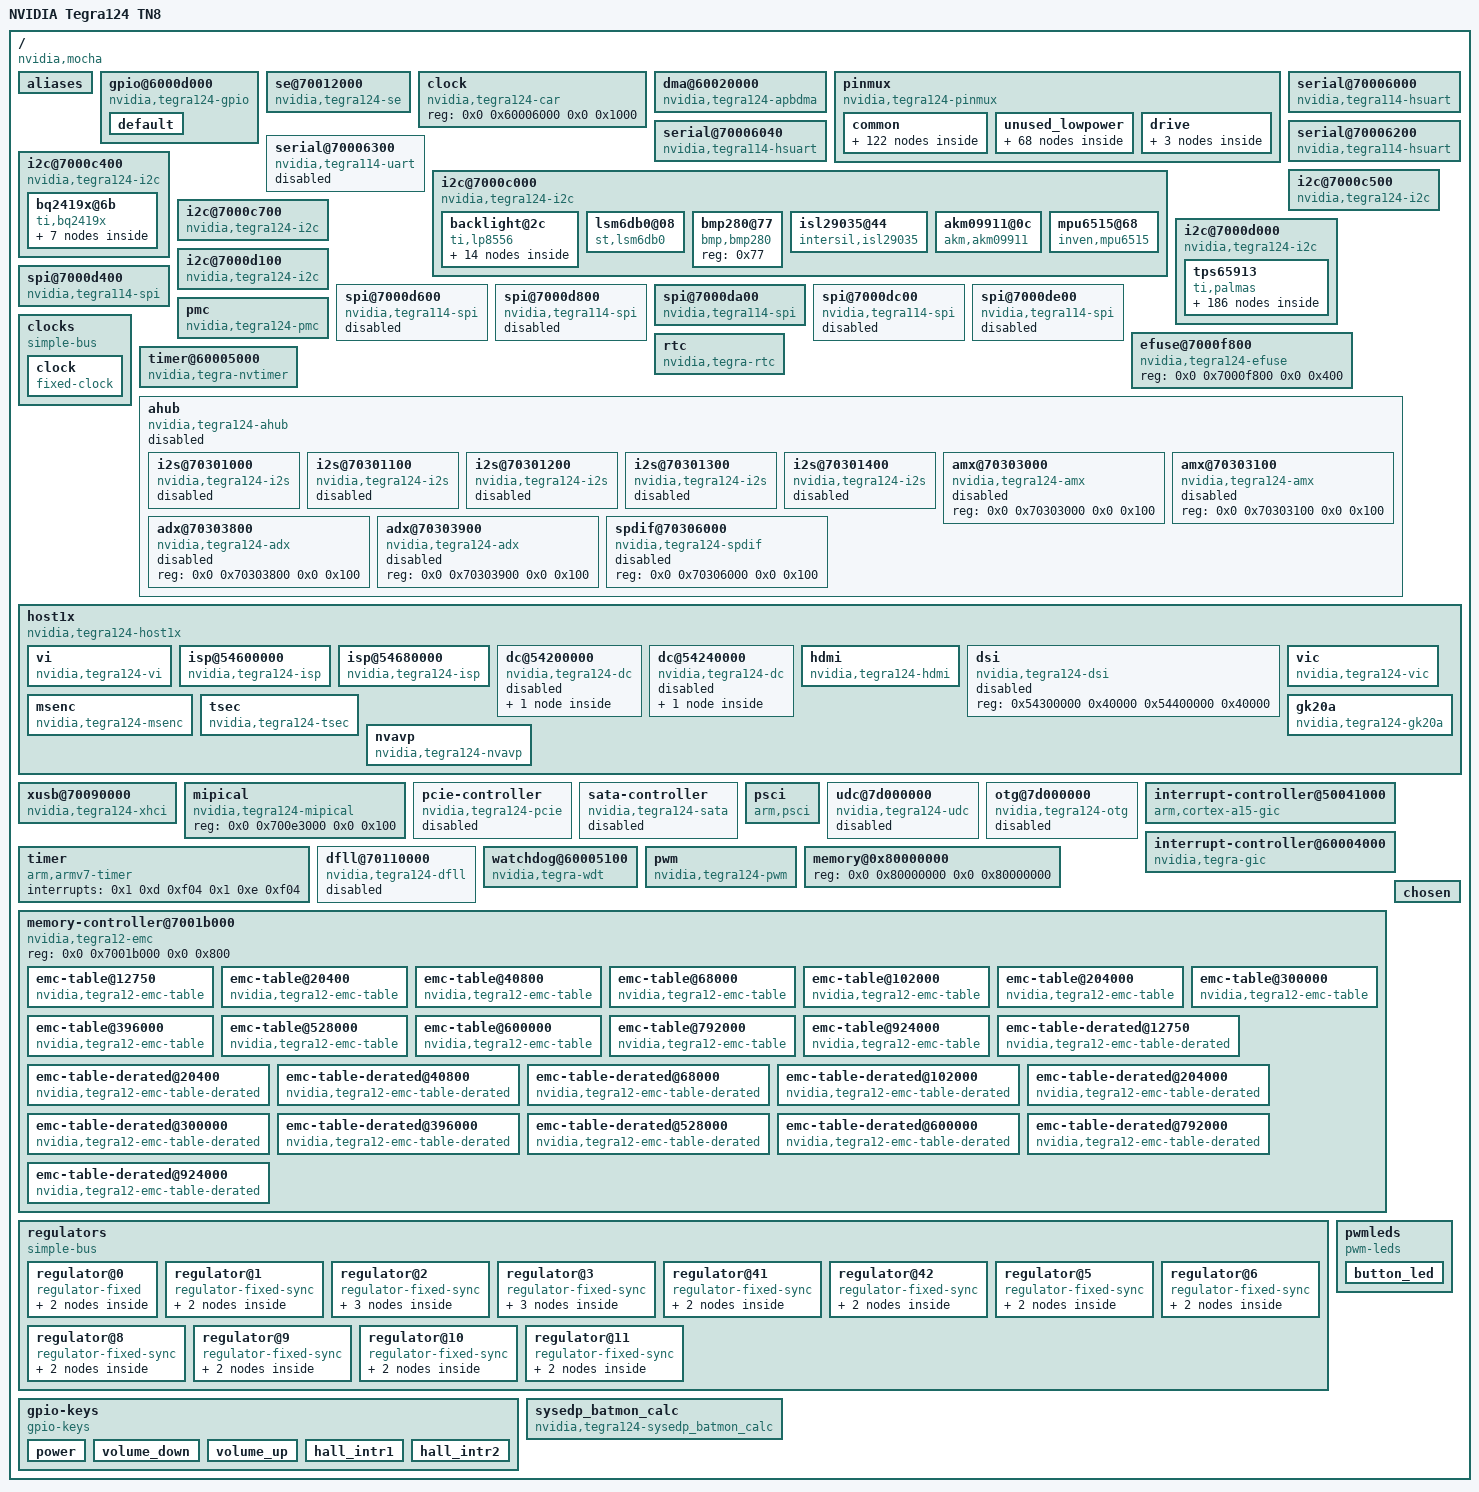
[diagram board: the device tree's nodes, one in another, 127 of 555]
/dts-v1/;

/ {
	compatible = "nvidia,mocha", "nvidia,tegra124";
	interrupt-parent = <0x1>;
	#address-cells = <0x2>;
	#size-cells = <0x2>;
	model = "NVIDIA Tegra124 TN8";
	nvidia,dtsfilename = "arch/arm/boot/dts/tegra124-mocha.dts";
	nvidia,boardids = "1780:1100:3:A:7", "1845:1000:0:A:7";

	aliases {
		i2c0 = "/i2c@7000c000";
		i2c1 = "/i2c@7000c400";
		i2c2 = "/i2c@7000c500";
		i2c3 = "/i2c@7000c700";
		i2c4 = "/i2c@7000d000";
		i2c5 = "/i2c@7000d100";
		serial0 = "/serial@70006000";
		serial1 = "/serial@70006040";
		serial2 = "/serial@70006200";
		serial3 = "/serial@70006300";
		spi0 = "/spi@7000d400";
		spi1 = "/spi@7000d600";
		spi2 = "/spi@7000d800";
		spi3 = "/spi@7000da00";
		spi4 = "/spi@7000dc00";
		spi5 = "/spi@7000de00";
		udc0 = "/udc@7d000000";
	};

	gpio@6000d000 {
		compatible = "nvidia,tegra124-gpio", "nvidia,tegra30-gpio";
		reg = <0x0 0x6000d000 0x0 0x1000>;
		interrupts = <0x0 0x20 0x4 0x0 0x21 0x4 0x0 0x22 0x4 0x0 0x23 0x4 0x0 0x37 0x4 0x0 0x57 0x4 0x0 0x59 0x4 0x0 0x7d 0x4>;
		#gpio-cells = <0x2>;
		gpio-controller;
		#interrupt-cells = <0x2>;
		interrupt-controller;
		gpio-init-names = "default";
		gpio-init-0 = <0x2>;
		linux,phandle = <0x7>;
		phandle = <0x7>;

		default {
			gpio-input = <0x2 0x3 0x32 0x33 0x45 0x46 0x47 0x48 0x50 0x52 0x80 0x85 0x86 0x87 0x8f 0x90 0x95 0xa5 0xa6 0xb2 0xb3 0xbb>;
			gpio-output-low = <0x4 0x5 0x36 0x37 0x3d 0x40 0x51 0x54 0x84 0x88 0x89 0x8b 0x8d 0x96 0xb9 0xbf 0xdb 0xde 0xdf 0xe1 0xe5 0xf1>;
			gpio-output-high = <0x3b 0x44 0x8a 0x92 0xb5 0xbd 0xdc 0xdd>;
			linux,phandle = <0x2>;
			phandle = <0x2>;
		};
	};

	se@70012000 {
		compatible = "nvidia,tegra124-se";
		reg = <0x0 0x70012000 0x0 0x2000 0x0 0x7000e400 0x0 0x400>;
		interrupts = <0x0 0x3a 0x4>;
	};

	clock {
		compatible = "nvidia,tegra124-car";
		reg = <0x0 0x60006000 0x0 0x1000>;
		#clock-cells = <0x1>;
		linux,phandle = <0xe>;
		phandle = <0xe>;
	};

	dma@60020000 {
		compatible = "nvidia,tegra124-apbdma";
		reg = <0x0 0x60020000 0x0 0x1400>;
		interrupts = <0x0 0x68 0x4 0x0 0x69 0x4 0x0 0x6a 0x4 0x0 0x6b 0x4 0x0 0x6c 0x4 0x0 0x6d 0x4 0x0 0x6e 0x4 0x0 0x6f 0x4 0x0 0x70 0x4 0x0 0x71 0x4 0x0 0x72 0x4 0x0 0x73 0x4 0x0 0x74 0x4 0x0 0x75 0x4 0x0 0x76 0x4 0x0 0x77 0x4 0x0 0x80 0x4 0x0 0x81 0x4 0x0 0x82 0x4 0x0 0x83 0x4 0x0 0x84 0x4 0x0 0x85 0x4 0x0 0x86 0x4 0x0 0x87 0x4 0x0 0x88 0x4 0x0 0x89 0x4 0x0 0x8a 0x4 0x0 0x8b 0x4 0x0 0x8c 0x4 0x0 0x8d 0x4 0x0 0x8e 0x4 0x0 0x8f 0x4>;
		linux,phandle = <0x6>;
		phandle = <0x6>;
	};

	pinmux {
		compatible = "nvidia,tegra124-pinmux";
		reg = <0x0 0x70000868 0x0 0x164 0x0 0x70003000 0x0 0x434>;
		status = "okay";
		pinctrl-names = "default", "drive", "unused";
		pinctrl-0 = <0x3>;
		pinctrl-1 = <0x4>;
		pinctrl-2 = <0x5>;

		common {
			linux,phandle = <0x3>;
			phandle = <0x3>;

			dap_mclk1_pw4 {
				nvidia,pins = "dap_mclk1_pw4";
				nvidia,function = "extperiph1";
				nvidia,enable-input = <0x0>;
				nvidia,pull = <0x0>;
				nvidia,tristate = <0x0>;
			};

			dap1_din_pn1 {
				nvidia,pins = "dap1_din_pn1";
				nvidia,function = "i2s0";
				nvidia,enable-input = <0x1>;
				nvidia,pull = <0x0>;
				nvidia,tristate = <0x1>;
			};

			dap1_dout_pn2 {
				nvidia,pins = "dap1_dout_pn2";
				nvidia,function = "i2s0";
				nvidia,enable-input = <0x0>;
				nvidia,pull = <0x0>;
				nvidia,tristate = <0x1>;
			};

			dap1_fs_pn0 {
				nvidia,pins = "dap1_fs_pn0";
				nvidia,function = "i2s0";
				nvidia,enable-input = <0x1>;
				nvidia,pull = <0x0>;
				nvidia,tristate = <0x1>;
			};

			dap1_sclk_pn3 {
				nvidia,pins = "dap1_sclk_pn3";
				nvidia,function = "i2s0";
				nvidia,enable-input = <0x1>;
				nvidia,pull = <0x0>;
				nvidia,tristate = <0x1>;
			};

			dap2_din_pa4 {
				nvidia,pins = "dap2_din_pa4";
				nvidia,function = "safe";
				nvidia,enable-input = <0x0>;
				nvidia,pull = <0x0>;
				nvidia,tristate = <0x0>;
			};

			dap2_dout_pa5 {
				nvidia,pins = "dap2_dout_pa5";
				nvidia,function = "safe";
				nvidia,enable-input = <0x0>;
				nvidia,pull = <0x0>;
				nvidia,tristate = <0x0>;
			};

			dap2_fs_pa2 {
				nvidia,pins = "dap2_fs_pa2";
				nvidia,function = "safe";
				nvidia,enable-input = <0x1>;
				nvidia,pull = <0x2>;
				nvidia,tristate = <0x0>;
			};

			dap2_sclk_pa3 {
				nvidia,pins = "dap2_sclk_pa3";
				nvidia,function = "safe";
				nvidia,enable-input = <0x1>;
				nvidia,pull = <0x2>;
				nvidia,tristate = <0x0>;
			};

			dvfs_pwm_px0 {
				nvidia,pins = "dvfs_pwm_px0";
				nvidia,function = "cldvfs";
				nvidia,enable-input = <0x0>;
				nvidia,pull = <0x0>;
				nvidia,tristate = <0x1>;
			};

			dvfs_clk_px2 {
				nvidia,pins = "dvfs_clk_px2";
				nvidia,function = "cldvfs";
				nvidia,enable-input = <0x0>;
				nvidia,pull = <0x0>;
				nvidia,tristate = <0x0>;
			};

			cam_i2c_scl_pbb1 {
				nvidia,pins = "cam_i2c_scl_pbb1";
				nvidia,function = "i2c3";
				nvidia,enable-input = <0x1>;
				nvidia,pull = <0x0>;
				nvidia,tristate = <0x0>;
				nvidia,lock = <0x0>;
				nvidia,open-drain = <0x0>;
			};

			cam_i2c_sda_pbb2 {
				nvidia,pins = "cam_i2c_sda_pbb2";
				nvidia,function = "i2c3";
				nvidia,enable-input = <0x1>;
				nvidia,pull = <0x0>;
				nvidia,tristate = <0x0>;
				nvidia,lock = <0x0>;
				nvidia,open-drain = <0x0>;
			};

			cam_mclk_pcc0 {
				nvidia,pins = "cam_mclk_pcc0";
				nvidia,function = "vi_alt3";
				nvidia,enable-input = <0x0>;
				nvidia,pull = <0x0>;
				nvidia,tristate = <0x0>;
			};

			pbb0 {
				nvidia,pins = "pbb0";
				nvidia,function = "vimclk2_alt";
				nvidia,enable-input = <0x0>;
				nvidia,pull = <0x0>;
				nvidia,tristate = <0x0>;
			};

			gen2_i2c_scl_pt5 {
				nvidia,pins = "gen2_i2c_scl_pt5";
				nvidia,function = "i2c2";
				nvidia,enable-input = <0x1>;
				nvidia,pull = <0x0>;
				nvidia,tristate = <0x0>;
				nvidia,lock = <0x0>;
				nvidia,open-drain = <0x0>;
			};

			gen2_i2c_sda_pt6 {
				nvidia,pins = "gen2_i2c_sda_pt6";
				nvidia,function = "i2c2";
				nvidia,enable-input = <0x1>;
				nvidia,pull = <0x0>;
				nvidia,tristate = <0x0>;
				nvidia,lock = <0x0>;
				nvidia,open-drain = <0x0>;
			};

			pj7 {
				nvidia,pins = "pj7";
				nvidia,function = "uartd";
				nvidia,enable-input = <0x0>;
				nvidia,pull = <0x0>;
				nvidia,tristate = <0x0>;
			};

			pb0 {
				nvidia,pins = "pb0";
				nvidia,function = "uartd";
				nvidia,enable-input = <0x1>;
				nvidia,pull = <0x2>;
				nvidia,tristate = <0x1>;
			};

			pg6 {
				nvidia,pins = "pg6";
				nvidia,function = "safe";
				nvidia,enable-input = <0x0>;
				nvidia,pull = <0x0>;
				nvidia,tristate = <0x0>;
			};

			pg7 {
				nvidia,pins = "pg7";
				nvidia,function = "safe";
				nvidia,enable-input = <0x0>;
				nvidia,pull = <0x0>;
				nvidia,tristate = <0x0>;
			};

			ph0 {
				nvidia,pins = "ph0";
				nvidia,function = "pwm0";
				nvidia,enable-input = <0x0>;
				nvidia,pull = <0x0>;
				nvidia,tristate = <0x0>;
			};

			ph1 {
				nvidia,pins = "ph1";
				nvidia,function = "pwm1";
				nvidia,enable-input = <0x0>;
				nvidia,pull = <0x0>;
				nvidia,tristate = <0x0>;
			};

			pj2 {
				nvidia,pins = "pj2";
				nvidia,function = "soc";
				nvidia,enable-input = <0x1>;
				nvidia,pull = <0x2>;
				nvidia,tristate = <0x0>;
			};

			kb_row15_ps7 {
				nvidia,pins = "kb_row15_ps7";
				nvidia,function = "soc";
				nvidia,enable-input = <0x1>;
				nvidia,pull = <0x2>;
				nvidia,tristate = <0x0>;
			};

			clk_32k_out_pa0 {
				nvidia,pins = "clk_32k_out_pa0";
				nvidia,function = "soc";
				nvidia,enable-input = <0x1>;
				nvidia,pull = <0x2>;
				nvidia,tristate = <0x0>;
			};

			clk2_out_pw5 {
				nvidia,pins = "clk2_out_pw5";
				nvidia,function = "safe";
				nvidia,enable-input = <0x0>;
				nvidia,pull = <0x2>;
				nvidia,tristate = <0x0>;
			};

			sdmmc1_clk_pz0 {
				nvidia,pins = "sdmmc1_clk_pz0";
				nvidia,function = "sdmmc1";
				nvidia,enable-input = <0x1>;
				nvidia,pull = <0x0>;
				nvidia,tristate = <0x0>;
			};

			sdmmc1_cmd_pz1 {
				nvidia,pins = "sdmmc1_cmd_pz1";
				nvidia,function = "sdmmc1";
				nvidia,enable-input = <0x1>;
				nvidia,pull = <0x2>;
				nvidia,tristate = <0x0>;
			};

			sdmmc1_dat0_py7 {
				nvidia,pins = "sdmmc1_dat0_py7";
				nvidia,function = "sdmmc1";
				nvidia,enable-input = <0x1>;
				nvidia,pull = <0x2>;
				nvidia,tristate = <0x0>;
			};

			sdmmc1_dat1_py6 {
				nvidia,pins = "sdmmc1_dat1_py6";
				nvidia,function = "sdmmc1";
				nvidia,enable-input = <0x1>;
				nvidia,pull = <0x2>;
				nvidia,tristate = <0x0>;
			};

			sdmmc1_dat2_py5 {
				nvidia,pins = "sdmmc1_dat2_py5";
				nvidia,function = "sdmmc1";
				nvidia,enable-input = <0x1>;
				nvidia,pull = <0x2>;
				nvidia,tristate = <0x0>;
			};

			sdmmc1_dat3_py4 {
				nvidia,pins = "sdmmc1_dat3_py4";
				nvidia,function = "sdmmc1";
				nvidia,enable-input = <0x1>;
				nvidia,pull = <0x2>;
				nvidia,tristate = <0x0>;
			};

			sdmmc3_clk_pa6 {
				nvidia,pins = "sdmmc3_clk_pa6";
				nvidia,function = "sdmmc3";
				nvidia,enable-input = <0x1>;
				nvidia,pull = <0x0>;
				nvidia,tristate = <0x0>;
			};

			sdmmc3_cmd_pa7 {
				nvidia,pins = "sdmmc3_cmd_pa7";
				nvidia,function = "sdmmc3";
				nvidia,enable-input = <0x1>;
				nvidia,pull = <0x2>;
				nvidia,tristate = <0x0>;
			};

			sdmmc3_dat0_pb7 {
				nvidia,pins = "sdmmc3_dat0_pb7";
				nvidia,function = "sdmmc3";
				nvidia,enable-input = <0x1>;
				nvidia,pull = <0x2>;
				nvidia,tristate = <0x0>;
			};

			sdmmc3_dat1_pb6 {
				nvidia,pins = "sdmmc3_dat1_pb6";
				nvidia,function = "sdmmc3";
				nvidia,enable-input = <0x1>;
				nvidia,pull = <0x2>;
				nvidia,tristate = <0x0>;
			};

			sdmmc3_dat2_pb5 {
				nvidia,pins = "sdmmc3_dat2_pb5";
				nvidia,function = "sdmmc3";
				nvidia,enable-input = <0x1>;
				nvidia,pull = <0x2>;
				nvidia,tristate = <0x0>;
			};

			sdmmc3_dat3_pb4 {
				nvidia,pins = "sdmmc3_dat3_pb4";
				nvidia,function = "sdmmc3";
				nvidia,enable-input = <0x1>;
				nvidia,pull = <0x2>;
				nvidia,tristate = <0x0>;
			};

			sdmmc3_clk_lb_out_pee4 {
				nvidia,pins = "sdmmc3_clk_lb_out_pee4";
				nvidia,function = "sdmmc3";
				nvidia,enable-input = <0x1>;
				nvidia,pull = <0x2>;
				nvidia,tristate = <0x0>;
			};

			sdmmc3_clk_lb_in_pee5 {
				nvidia,pins = "sdmmc3_clk_lb_in_pee5";
				nvidia,function = "sdmmc3";
				nvidia,enable-input = <0x1>;
				nvidia,pull = <0x2>;
				nvidia,tristate = <0x0>;
			};

			sdmmc3_cd_n_pv2 {
				nvidia,pins = "sdmmc3_cd_n_pv2";
				nvidia,function = "sdmmc3";
				nvidia,enable-input = <0x1>;
				nvidia,pull = <0x0>;
				nvidia,tristate = <0x0>;
			};

			sdmmc4_clk_pcc4 {
				nvidia,pins = "sdmmc4_clk_pcc4";
				nvidia,function = "sdmmc4";
				nvidia,enable-input = <0x1>;
				nvidia,pull = <0x0>;
				nvidia,tristate = <0x0>;
			};

			sdmmc4_cmd_pt7 {
				nvidia,pins = "sdmmc4_cmd_pt7";
				nvidia,function = "sdmmc4";
				nvidia,enable-input = <0x1>;
				nvidia,pull = <0x2>;
				nvidia,tristate = <0x0>;
			};

			sdmmc4_dat0_paa0 {
				nvidia,pins = "sdmmc4_dat0_paa0";
				nvidia,function = "sdmmc4";
				nvidia,enable-input = <0x1>;
				nvidia,pull = <0x2>;
				nvidia,tristate = <0x0>;
			};

			sdmmc4_dat1_paa1 {
				nvidia,pins = "sdmmc4_dat1_paa1";
				nvidia,function = "sdmmc4";
				nvidia,enable-input = <0x1>;
				nvidia,pull = <0x2>;
				nvidia,tristate = <0x0>;
			};

			sdmmc4_dat2_paa2 {
				nvidia,pins = "sdmmc4_dat2_paa2";
				nvidia,function = "sdmmc4";
				nvidia,enable-input = <0x1>;
				nvidia,pull = <0x2>;
				nvidia,tristate = <0x0>;
			};

			sdmmc4_dat3_paa3 {
				nvidia,pins = "sdmmc4_dat3_paa3";
				nvidia,function = "sdmmc4";
				nvidia,enable-input = <0x1>;
				nvidia,pull = <0x2>;
				nvidia,tristate = <0x0>;
			};

			sdmmc4_dat4_paa4 {
				nvidia,pins = "sdmmc4_dat4_paa4";
				nvidia,function = "sdmmc4";
				nvidia,enable-input = <0x1>;
				nvidia,pull = <0x2>;
				nvidia,tristate = <0x0>;
			};

			sdmmc4_dat5_paa5 {
				nvidia,pins = "sdmmc4_dat5_paa5";
				nvidia,function = "sdmmc4";
				nvidia,enable-input = <0x1>;
				nvidia,pull = <0x2>;
				nvidia,tristate = <0x0>;
			};

			sdmmc4_dat6_paa6 {
				nvidia,pins = "sdmmc4_dat6_paa6";
				nvidia,function = "sdmmc4";
				nvidia,enable-input = <0x1>;
				nvidia,pull = <0x2>;
				nvidia,tristate = <0x0>;
			};

			sdmmc4_dat7_paa7 {
				nvidia,pins = "sdmmc4_dat7_paa7";
				nvidia,function = "sdmmc4";
				nvidia,enable-input = <0x1>;
				nvidia,pull = <0x2>;
				nvidia,tristate = <0x0>;
			};

			kb_row3_pr3 {
				nvidia,pins = "kb_row3_pr3";
				nvidia,function = "safe";
				nvidia,enable-input = <0x1>;
				nvidia,pull = <0x0>;
				nvidia,tristate = <0x0>;
			};

			kb_row6_pr6 {
				nvidia,pins = "kb_row6_pr6";
				nvidia,function = "displaya_alt";
				nvidia,enable-input = <0x1>;
				nvidia,pull = <0x0>;
				nvidia,tristate = <0x0>;
			};

			pwr_i2c_scl_pz6 {
				nvidia,pins = "pwr_i2c_scl_pz6";
				nvidia,function = "i2cpwr";
				nvidia,enable-input = <0x1>;
				nvidia,pull = <0x0>;
				nvidia,tristate = <0x0>;
				nvidia,open-drain = <0x0>;
			};

			pwr_i2c_sda_pz7 {
				nvidia,pins = "pwr_i2c_sda_pz7";
				nvidia,function = "i2cpwr";
				nvidia,enable-input = <0x1>;
				nvidia,pull = <0x0>;
				nvidia,tristate = <0x0>;
				nvidia,open-drain = <0x0>;
			};

			clk_32k_in {
				nvidia,pins = "clk_32k_in";
				nvidia,function = "clk";
				nvidia,enable-input = <0x1>;
				nvidia,pull = <0x0>;
				nvidia,tristate = <0x0>;
			};

			core_pwr_req {
				nvidia,pins = "core_pwr_req";
				nvidia,function = "pwron";
				nvidia,enable-input = <0x0>;
				nvidia,pull = <0x0>;
				nvidia,tristate = <0x0>;
			};

			cpu_pwr_req {
				nvidia,pins = "cpu_pwr_req";
				nvidia,function = "cpu";
				nvidia,enable-input = <0x0>;
				nvidia,pull = <0x0>;
				nvidia,tristate = <0x0>;
			};

			pwr_int_n {
				nvidia,pins = "pwr_int_n";
				nvidia,function = "pmi";
				nvidia,enable-input = <0x1>;
				nvidia,pull = <0x2>;
				nvidia,tristate = <0x0>;
			};

			reset_out_n {
				nvidia,pins = "reset_out_n";
				nvidia,function = "reset_out_n";
				nvidia,enable-input = <0x0>;
				nvidia,pull = <0x0>;
				nvidia,tristate = <0x0>;
			};

			gen1_i2c_sda_pc5 {
				nvidia,pins = "gen1_i2c_sda_pc5";
				nvidia,function = "i2c1";
				nvidia,enable-input = <0x1>;
				nvidia,pull = <0x0>;
				nvidia,tristate = <0x0>;
				nvidia,lock = <0x0>;
				nvidia,open-drain = <0x0>;
			};

			gen1_i2c_scl_pc4 {
				nvidia,pins = "gen1_i2c_scl_pc4";
				nvidia,function = "i2c1";
				nvidia,enable-input = <0x1>;
				nvidia,pull = <0x0>;
				nvidia,tristate = <0x0>;
				nvidia,lock = <0x0>;
				nvidia,open-drain = <0x0>;
			};

			uart2_cts_n_pj5 {
				nvidia,pins = "uart2_cts_n_pj5";
				nvidia,function = "uartb";
				nvidia,enable-input = <0x1>;
				nvidia,pull = <0x2>;
				nvidia,tristate = <0x0>;
			};

			uart2_rts_n_pj6 {
				nvidia,pins = "uart2_rts_n_pj6";
				nvidia,function = "uartb";
				nvidia,enable-input = <0x0>;
				nvidia,pull = <0x2>;
				nvidia,tristate = <0x0>;
			};

			uart2_rxd_pc3 {
				nvidia,pins = "uart2_rxd_pc3";
				nvidia,function = "irda";
				nvidia,enable-input = <0x1>;
				nvidia,pull = <0x2>;
				nvidia,tristate = <0x0>;
			};

			uart2_txd_pc2 {
				nvidia,pins = "uart2_txd_pc2";
				nvidia,function = "irda";
				nvidia,enable-input = <0x0>;
				nvidia,pull = <0x2>;
				nvidia,tristate = <0x0>;
			};

			uart3_cts_n_pa1 {
				nvidia,pins = "uart3_cts_n_pa1";
				nvidia,function = "uartc";
				nvidia,enable-input = <0x1>;
				nvidia,pull = <0x2>;
				nvidia,tristate = <0x0>;
			};

			uart3_rts_n_pc0 {
				nvidia,pins = "uart3_rts_n_pc0";
				nvidia,function = "uartc";
				nvidia,enable-input = <0x0>;
				nvidia,pull = <0x2>;
				nvidia,tristate = <0x0>;
			};

			uart3_rxd_pw7 {
				nvidia,pins = "uart3_rxd_pw7";
				nvidia,function = "uartc";
				nvidia,enable-input = <0x1>;
				nvidia,pull = <0x2>;
				nvidia,tristate = <0x0>;
			};

			uart3_txd_pw6 {
				nvidia,pins = "uart3_txd_pw6";
				nvidia,function = "uartc";
				nvidia,enable-input = <0x0>;
				nvidia,pull = <0x2>;
				nvidia,tristate = <0x0>;
			};

			ddc_scl_pv4 {
				nvidia,pins = "ddc_scl_pv4";
				nvidia,function = "i2c4";
				nvidia,enable-input = <0x1>;
				nvidia,pull = <0x0>;
				nvidia,tristate = <0x0>;
			};

			ddc_sda_pv5 {
				nvidia,pins = "ddc_sda_pv5";
				nvidia,function = "i2c4";
				nvidia,enable-input = <0x1>;
				nvidia,pull = <0x0>;
				nvidia,tristate = <0x0>;
			};

			pi7 {
				nvidia,pins = "pi7";
				nvidia,function = "safe";
				nvidia,enable-input = <0x1>;
				nvidia,pull = <0x2>;
				nvidia,tristate = <0x0>;
			};

			gpio_x5_aud_px5 {
				nvidia,pins = "gpio_x5_aud_px5";
				nvidia,function = "safe";
				nvidia,enable-input = <0x0>;
				nvidia,pull = <0x0>;
				nvidia,tristate = <0x0>;
			};

			gpio_x7_aud_px7 {
				nvidia,pins = "gpio_x7_aud_px7";
				nvidia,function = "safe";
				nvidia,enable-input = <0x0>;
				nvidia,pull = <0x0>;
				nvidia,tristate = <0x0>;
			};

			gpio_w2_aud_pw2 {
				nvidia,pins = "gpio_w2_aud_pw2";
				nvidia,function = "safe";
				nvidia,enable-input = <0x1>;
				nvidia,pull = <0x2>;
				nvidia,tristate = <0x0>;
			};

			gpio_w3_aud_pw3 {
				nvidia,pins = "gpio_w3_aud_pw3";
				nvidia,function = "safe";
				nvidia,enable-input = <0x1>;
				nvidia,pull = <0x2>;
				nvidia,tristate = <0x0>;
			};

			gpio_x1_aud_px1 {
				nvidia,pins = "gpio_x1_aud_px1";
				nvidia,function = "safe";
				nvidia,enable-input = <0x0>;
				nvidia,pull = <0x0>;
				nvidia,tristate = <0x0>;
			};

			gpio_x3_aud_px3 {
				nvidia,pins = "gpio_x3_aud_px3";
				nvidia,function = "safe";
				nvidia,enable-input = <0x1>;
				nvidia,pull = <0x2>;
				nvidia,tristate = <0x0>;
			};

			ulpi_data1_po2 {
				nvidia,pins = "ulpi_data1_po2";
				nvidia,function = "spi3";
				nvidia,enable-input = <0x1>;
				nvidia,pull = <0x2>;
				nvidia,tristate = <0x0>;
			};

			ulpi_data2_po3 {
				nvidia,pins = "ulpi_data2_po3";
				nvidia,function = "spi3";
				nvidia,enable-input = <0x1>;
				nvidia,pull = <0x2>;
				nvidia,tristate = <0x0>;
			};

			pbb3 {
				nvidia,pins = "pbb3";
				nvidia,function = "safe";
				nvidia,enable-input = <0x0>;
				nvidia,pull = <0x0>;
				nvidia,tristate = <0x0>;
			};

			pbb4 {
				nvidia,pins = "pbb4";
				nvidia,function = "safe";
				nvidia,enable-input = <0x0>;
				nvidia,pull = <0x2>;
				nvidia,tristate = <0x0>;
			};

			pbb5 {
				nvidia,pins = "pbb5";
				nvidia,function = "safe";
				nvidia,enable-input = <0x0>;
				nvidia,pull = <0x2>;
				nvidia,tristate = <0x0>;
			};

			pbb6 {
				nvidia,pins = "pbb6";
				nvidia,function = "safe";
				nvidia,enable-input = <0x0>;
				nvidia,pull = <0x0>;
				nvidia,tristate = <0x0>;
			};

			pbb7 {
				nvidia,pins = "pbb7";
				nvidia,function = "safe";
				nvidia,enable-input = <0x0>;
				nvidia,pull = <0x0>;
				nvidia,tristate = <0x0>;
			};

			pcc1 {
				nvidia,pins = "pcc1";
				nvidia,function = "safe";
				nvidia,enable-input = <0x0>;
				nvidia,pull = <0x0>;
				nvidia,tristate = <0x0>;
			};

			ph2 {
				nvidia,pins = "ph2";
				nvidia,function = "pwm2";
				nvidia,enable-input = <0x0>;
				nvidia,pull = <0x0>;
				nvidia,tristate = <0x0>;
			};

			ph3 {
				nvidia,pins = "ph3";
				nvidia,function = "safe";
				nvidia,enable-input = <0x0>;
				nvidia,pull = <0x2>;
				nvidia,tristate = <0x0>;
			};

			ph5 {
				nvidia,pins = "ph5";
				nvidia,function = "safe";
				nvidia,enable-input = <0x0>;
				nvidia,pull = <0x0>;
				nvidia,tristate = <0x0>;
			};

			pg2 {
				nvidia,pins = "pg2";
				nvidia,function = "safe";
				nvidia,enable-input = <0x1>;
				nvidia,pull = <0x1>;
				nvidia,tristate = <0x0>;
			};

			pg3 {
				nvidia,pins = "pg3";
				nvidia,function = "safe";
				nvidia,enable-input = <0x1>;
				nvidia,pull = <0x1>;
				nvidia,tristate = <0x0>;
			};

			pk1 {
				nvidia,pins = "pk1";
				nvidia,function = "safe";
				nvidia,enable-input = <0x0>;
				nvidia,pull = <0x0>;
				nvidia,tristate = <0x0>;
			};

			pj0 {
				nvidia,pins = "pj0";
				nvidia,function = "safe";
				nvidia,enable-input = <0x1>;
				nvidia,pull = <0x2>;
				nvidia,tristate = <0x0>;
			};

			pk4 {
				nvidia,pins = "pk4";
				nvidia,function = "safe";
				nvidia,enable-input = <0x0>;
				nvidia,pull = <0x0>;
				nvidia,tristate = <0x0>;
			};

			pk2 {
				nvidia,pins = "pk2";
				nvidia,function = "safe";
				nvidia,enable-input = <0x1>;
				nvidia,pull = <0x2>;
				nvidia,tristate = <0x0>;
			};

			pi6 {
				nvidia,pins = "pi6";
				nvidia,function = "safe";
				nvidia,enable-input = <0x1>;
				nvidia,pull = <0x2>;
				nvidia,tristate = <0x0>;
			};

			pi5 {
				nvidia,pins = "pi5";
				nvidia,function = "safe";
				nvidia,enable-input = <0x1>;
				nvidia,pull = <0x0>;
				nvidia,tristate = <0x0>;
			};

			pc7 {
				nvidia,pins = "pc7";
				nvidia,function = "safe";
				nvidia,enable-input = <0x1>;
				nvidia,pull = <0x2>;
				nvidia,tristate = <0x0>;
			};

			pi0 {
				nvidia,pins = "pi0";
				nvidia,function = "safe";
				nvidia,enable-input = <0x0>;
				nvidia,pull = <0x0>;
				nvidia,tristate = <0x0>;
			};

			clk2_req_pcc5 {
				nvidia,pins = "clk2_req_pcc5";
				nvidia,function = "safe";
				nvidia,enable-input = <0x0>;
				nvidia,pull = <0x0>;
				nvidia,tristate = <0x0>;
			};

			kb_col0_pq0 {
				nvidia,pins = "kb_col0_pq0";
				nvidia,function = "safe";
				nvidia,enable-input = <0x1>;
				nvidia,pull = <0x2>;
				nvidia,tristate = <0x0>;
			};

			kb_col5_pq5 {
				nvidia,pins = "kb_col5_pq5";
				nvidia,function = "safe";
				nvidia,enable-input = <0x1>;
				nvidia,pull = <0x2>;
				nvidia,tristate = <0x0>;
			};

			kb_col6_pq6 {
				nvidia,pins = "kb_col6_pq6";
				nvidia,function = "safe";
				nvidia,enable-input = <0x1>;
				nvidia,pull = <0x2>;
				nvidia,tristate = <0x0>;
			};

			kb_col7_pq7 {
				nvidia,pins = "kb_col7_pq7";
				nvidia,function = "safe";
				nvidia,enable-input = <0x1>;
				nvidia,pull = <0x2>;
				nvidia,tristate = <0x0>;
			};

			kb_row0_pr0 {
				nvidia,pins = "kb_row0_pr0";
				nvidia,function = "safe";
				nvidia,enable-input = <0x0>;
				nvidia,pull = <0x0>;
				nvidia,tristate = <0x0>;
			};

			kb_row1_pr1 {
				nvidia,pins = "kb_row1_pr1";
				nvidia,function = "safe";
				nvidia,enable-input = <0x0>;
				nvidia,pull = <0x0>;
				nvidia,tristate = <0x0>;
			};

			kb_row13_ps5 {
				nvidia,pins = "kb_row13_ps5";
				nvidia,function = "safe";
				nvidia,enable-input = <0x1>;
				nvidia,pull = <0x2>;
				nvidia,tristate = <0x0>;
			};

			kb_row14_ps6 {
				nvidia,pins = "kb_row14_ps6";
				nvidia,function = "safe";
				nvidia,enable-input = <0x0>;
				nvidia,pull = <0x0>;
				nvidia,tristate = <0x0>;
			};

			kb_row2_pr2 {
				nvidia,pins = "kb_row2_pr2";
				nvidia,function = "safe";
				nvidia,enable-input = <0x0>;
				nvidia,pull = <0x0>;
				nvidia,tristate = <0x0>;
			};

			kb_row5_pr5 {
				nvidia,pins = "kb_row5_pr5";
				nvidia,function = "safe";
				nvidia,enable-input = <0x0>;
				nvidia,pull = <0x0>;
				nvidia,tristate = <0x0>;
			};

			kb_row7_pr7 {
				nvidia,pins = "kb_row7_pr7";
				nvidia,function = "safe";
				nvidia,enable-input = <0x1>;
				nvidia,pull = <0x2>;
				nvidia,tristate = <0x0>;
			};

			kb_row8_ps0 {
				nvidia,pins = "kb_row8_ps0";
				nvidia,function = "safe";
				nvidia,enable-input = <0x1>;
				nvidia,pull = <0x2>;
				nvidia,tristate = <0x0>;
			};

			kb_row10_ps2 {
				nvidia,pins = "kb_row10_ps2";
				nvidia,function = "safe";
				nvidia,enable-input = <0x0>;
				nvidia,pull = <0x2>;
				nvidia,tristate = <0x0>;
			};

			clk3_req_pee1 {
				nvidia,pins = "clk3_req_pee1";
				nvidia,function = "safe";
				nvidia,enable-input = <0x0>;
				nvidia,pull = <0x0>;
				nvidia,tristate = <0x0>;
			};

			pu4 {
				nvidia,pins = "pu4";
				nvidia,function = "safe";
				nvidia,enable-input = <0x0>;
				nvidia,pull = <0x0>;
				nvidia,tristate = <0x0>;
			};

			pu5 {
				nvidia,pins = "pu5";
				nvidia,function = "safe";
				nvidia,enable-input = <0x1>;
				nvidia,pull = <0x2>;
				nvidia,tristate = <0x0>;
			};

			pu6 {
				nvidia,pins = "pu6";
				nvidia,function = "safe";
				nvidia,enable-input = <0x1>;
				nvidia,pull = <0x2>;
				nvidia,tristate = <0x0>;
			};

			ulpi_data0_po1 {
				nvidia,pins = "ulpi_data0_po1";
				nvidia,function = "spi3";
				nvidia,enable-input = <0x0>;
				nvidia,pull = <0x1>;
				nvidia,tristate = <0x1>;
			};

			ulpi_data3_po4 {
				nvidia,pins = "ulpi_data3_po4";
				nvidia,function = "spi3";
				nvidia,enable-input = <0x0>;
				nvidia,pull = <0x1>;
				nvidia,tristate = <0x1>;
			};

			pi1 {
				nvidia,pins = "pi1";
				nvidia,function = "safe";
				nvidia,enable-input = <0x0>;
				nvidia,pull = <0x1>;
				nvidia,tristate = <0x1>;
			};
		};

		unused_lowpower {
			linux,phandle = <0x5>;
			phandle = <0x5>;

			dap_mclk1_req_pee2 {
				nvidia,pins = "dap_mclk1_req_pee2";
				nvidia,function = "safe";
				nvidia,enable-input = <0x0>;
				nvidia,pull = <0x1>;
				nvidia,tristate = <0x1>;
			};

			dap3_din_pp1 {
				nvidia,pins = "dap3_din_pp1";
				nvidia,function = "safe";
				nvidia,enable-input = <0x0>;
				nvidia,pull = <0x1>;
				nvidia,tristate = <0x1>;
			};

			dap3_dout_pp2 {
				nvidia,pins = "dap3_dout_pp2";
				nvidia,function = "safe";
				nvidia,enable-input = <0x0>;
				nvidia,pull = <0x1>;
				nvidia,tristate = <0x1>;
			};

			dap3_fs_pp0 {
				nvidia,pins = "dap3_fs_pp0";
				nvidia,function = "safe";
				nvidia,enable-input = <0x0>;
				nvidia,pull = <0x1>;
				nvidia,tristate = <0x1>;
			};

			dap3_sclk_pp3 {
				nvidia,pins = "dap3_sclk_pp3";
				nvidia,function = "safe";
				nvidia,enable-input = <0x0>;
				nvidia,pull = <0x1>;
				nvidia,tristate = <0x1>;
			};

			pex_l0_clkreq_n_pdd2 {
				nvidia,pins = "pex_l0_clkreq_n_pdd2";
				nvidia,function = "safe";
				nvidia,enable-input = <0x0>;
				nvidia,pull = <0x1>;
				nvidia,tristate = <0x1>;
			};

			pex_l0_rst_n_pdd1 {
				nvidia,pins = "pex_l0_rst_n_pdd1";
				nvidia,function = "safe";
				nvidia,enable-input = <0x0>;
				nvidia,pull = <0x1>;
				nvidia,tristate = <0x1>;
			};

			pex_l1_clkreq_n_pdd6 {
				nvidia,pins = "pex_l1_clkreq_n_pdd6";
				nvidia,function = "safe";
				nvidia,enable-input = <0x0>;
				nvidia,pull = <0x1>;
				nvidia,tristate = <0x1>;
			};

			pex_l1_rst_n_pdd5 {
				nvidia,pins = "pex_l1_rst_n_pdd5";
				nvidia,function = "safe";
				nvidia,enable-input = <0x0>;
				nvidia,pull = <0x1>;
				nvidia,tristate = <0x1>;
			};

			pex_wake_n_pdd3 {
				nvidia,pins = "pex_wake_n_pdd3";
				nvidia,function = "safe";
				nvidia,enable-input = <0x0>;
				nvidia,pull = <0x1>;
				nvidia,tristate = <0x1>;
			};

			pff2 {
				nvidia,pins = "pff2";
				nvidia,function = "safe";
				nvidia,enable-input = <0x0>;
				nvidia,pull = <0x1>;
				nvidia,tristate = <0x1>;
			};

			kb_col3_pq3 {
				nvidia,pins = "kb_col3_pq3";
				nvidia,function = "safe";
				nvidia,enable-input = <0x0>;
				nvidia,pull = <0x1>;
				nvidia,tristate = <0x1>;
			};

			kb_row16_pt0 {
				nvidia,pins = "kb_row16_pt0";
				nvidia,function = "safe";
				nvidia,enable-input = <0x0>;
				nvidia,pull = <0x1>;
				nvidia,tristate = <0x1>;
			};

			kb_row17_pt1 {
				nvidia,pins = "kb_row17_pt1";
				nvidia,function = "safe";
				nvidia,enable-input = <0x0>;
				nvidia,pull = <0x1>;
				nvidia,tristate = <0x1>;
			};

			owr {
				nvidia,pins = "owr";
				nvidia,function = "safe";
				nvidia,enable-input = <0x0>;
				nvidia,pull = <0x1>;
				nvidia,tristate = <0x1>;
			};

			ulpi_clk_py0 {
				nvidia,pins = "ulpi_clk_py0";
				nvidia,function = "safe";
				nvidia,enable-input = <0x0>;
				nvidia,pull = <0x1>;
				nvidia,tristate = <0x1>;
			};

			ulpi_dir_py1 {
				nvidia,pins = "ulpi_dir_py1";
				nvidia,function = "safe";
				nvidia,enable-input = <0x0>;
				nvidia,pull = <0x1>;
				nvidia,tristate = <0x1>;
			};

			ulpi_nxt_py2 {
				nvidia,pins = "ulpi_nxt_py2";
				nvidia,function = "safe";
				nvidia,enable-input = <0x0>;
				nvidia,pull = <0x1>;
				nvidia,tristate = <0x1>;
			};

			ulpi_stp_py3 {
				nvidia,pins = "ulpi_stp_py3";
				nvidia,function = "safe";
				nvidia,enable-input = <0x0>;
				nvidia,pull = <0x1>;
				nvidia,tristate = <0x1>;
			};

			hdmi_cec_pee3 {
				nvidia,pins = "hdmi_cec_pee3";
				nvidia,function = "safe";
				nvidia,enable-input = <0x0>;
				nvidia,pull = <0x1>;
				nvidia,tristate = <0x1>;
			};

			clk3_out_pee0 {
				nvidia,pins = "clk3_out_pee0";
				nvidia,function = "safe";
				nvidia,enable-input = <0x0>;
				nvidia,pull = <0x1>;
				nvidia,tristate = <0x1>;
			};

			dp_hpd_pff0 {
				nvidia,pins = "dp_hpd_pff0";
				nvidia,function = "safe";
				nvidia,enable-input = <0x0>;
				nvidia,pull = <0x1>;
				nvidia,tristate = <0x1>;
			};

			dap4_din_pp5 {
				nvidia,pins = "dap4_din_pp5";
				nvidia,function = "safe";
				nvidia,enable-input = <0x0>;
				nvidia,pull = <0x1>;
				nvidia,tristate = <0x1>;
			};

			dap4_dout_pp6 {
				nvidia,pins = "dap4_dout_pp6";
				nvidia,function = "safe";
				nvidia,enable-input = <0x0>;
				nvidia,pull = <0x1>;
				nvidia,tristate = <0x1>;
			};

			dap4_fs_pp4 {
				nvidia,pins = "dap4_fs_pp4";
				nvidia,function = "safe";
				nvidia,enable-input = <0x0>;
				nvidia,pull = <0x1>;
				nvidia,tristate = <0x1>;
			};

			dap4_sclk_pp7 {
				nvidia,pins = "dap4_sclk_pp7";
				nvidia,function = "safe";
				nvidia,enable-input = <0x0>;
				nvidia,pull = <0x1>;
				nvidia,tristate = <0x1>;
			};

			kb_row9_ps1 {
				nvidia,pins = "kb_row9_ps1";
				nvidia,function = "safe";
				nvidia,enable-input = <0x0>;
				nvidia,pull = <0x1>;
				nvidia,tristate = <0x1>;
			};

			pk0 {
				nvidia,pins = "pk0";
				nvidia,function = "safe";
				nvidia,enable-input = <0x0>;
				nvidia,pull = <0x1>;
				nvidia,tristate = <0x1>;
			};

			pi3 {
				nvidia,pins = "pi3";
				nvidia,function = "safe";
				nvidia,enable-input = <0x0>;
				nvidia,pull = <0x1>;
				nvidia,tristate = <0x1>;
			};

			pb1 {
				nvidia,pins = "pb1";
				nvidia,function = "safe";
				nvidia,enable-input = <0x0>;
				nvidia,pull = <0x1>;
				nvidia,tristate = <0x1>;
			};

			ulpi_data4_po5 {
				nvidia,pins = "ulpi_data4_po5";
				nvidia,function = "safe";
				nvidia,enable-input = <0x0>;
				nvidia,pull = <0x1>;
				nvidia,tristate = <0x1>;
			};

			ulpi_data5_po6 {
				nvidia,pins = "ulpi_data5_po6";
				nvidia,function = "safe";
				nvidia,enable-input = <0x0>;
				nvidia,pull = <0x1>;
				nvidia,tristate = <0x1>;
			};

			ulpi_data6_po7 {
				nvidia,pins = "ulpi_data6_po7";
				nvidia,function = "safe";
				nvidia,enable-input = <0x0>;
				nvidia,pull = <0x1>;
				nvidia,tristate = <0x1>;
			};

			ulpi_data7_po0 {
				nvidia,pins = "ulpi_data7_po0";
				nvidia,function = "safe";
				nvidia,enable-input = <0x0>;
				nvidia,pull = <0x1>;
				nvidia,tristate = <0x1>;
			};

			pv0 {
				nvidia,pins = "pv0";
				nvidia,function = "safe";
				nvidia,enable-input = <0x0>;
				nvidia,pull = <0x1>;
				nvidia,tristate = <0x1>;
			};

			pv1 {
				nvidia,pins = "pv1";
				nvidia,function = "safe";
				nvidia,enable-input = <0x0>;
				nvidia,pull = <0x1>;
				nvidia,tristate = <0x1>;
			};

			gpio_x6_aud_px6 {
				nvidia,pins = "gpio_x6_aud_px6";
				nvidia,function = "safe";
				nvidia,enable-input = <0x0>;
				nvidia,pull = <0x1>;
				nvidia,tristate = <0x1>;
			};

			gpio_x4_aud_px4 {
				nvidia,pins = "gpio_x4_aud_px4";
				nvidia,function = "safe";
				nvidia,enable-input = <0x0>;
				nvidia,pull = <0x1>;
				nvidia,tristate = <0x1>;
			};

			ph6 {
				nvidia,pins = "ph6";
				nvidia,function = "safe";
				nvidia,enable-input = <0x0>;
				nvidia,pull = <0x1>;
				nvidia,tristate = <0x1>;
			};

			ph7 {
				nvidia,pins = "ph7";
				nvidia,function = "safe";
				nvidia,enable-input = <0x0>;
				nvidia,pull = <0x1>;
				nvidia,tristate = <0x1>;
			};

			hdmi_int_pn7 {
				nvidia,pins = "hdmi_int_pn7";
				nvidia,function = "safe";
				nvidia,enable-input = <0x0>;
				nvidia,pull = <0x1>;
				nvidia,tristate = <0x1>;
			};

			spdif_out_pk5 {
				nvidia,pins = "spdif_out_pk5";
				nvidia,function = "safe";
				nvidia,enable-input = <0x0>;
				nvidia,pull = <0x1>;
				nvidia,tristate = <0x1>;
			};

			spdif_in_pk6 {
				nvidia,pins = "spdif_in_pk6";
				nvidia,function = "safe";
				nvidia,enable-input = <0x0>;
				nvidia,pull = <0x1>;
				nvidia,tristate = <0x1>;
			};

			pu2 {
				nvidia,pins = "pu2";
				nvidia,function = "safe";
				nvidia,enable-input = <0x0>;
				nvidia,pull = <0x1>;
				nvidia,tristate = <0x1>;
			};

			pu3 {
				nvidia,pins = "pu3";
				nvidia,function = "safe";
				nvidia,enable-input = <0x0>;
				nvidia,pull = <0x1>;
				nvidia,tristate = <0x1>;
			};

			kb_row4_pr4 {
				nvidia,pins = "kb_row4_pr4";
				nvidia,function = "safe";
				nvidia,enable-input = <0x0>;
				nvidia,pull = <0x1>;
				nvidia,tristate = <0x1>;
			};

			kb_row11_ps3 {
				nvidia,pins = "kb_row11_ps3";
				nvidia,function = "safe";
				nvidia,enable-input = <0x0>;
				nvidia,pull = <0x1>;
				nvidia,tristate = <0x1>;
			};

			kb_row12_ps4 {
				nvidia,pins = "kb_row12_ps4";
				nvidia,function = "safe";
				nvidia,enable-input = <0x0>;
				nvidia,pull = <0x1>;
				nvidia,tristate = <0x1>;
			};

			kb_col1_pq1 {
				nvidia,pins = "kb_col1_pq1";
				nvidia,function = "safe";
				nvidia,enable-input = <0x0>;
				nvidia,pull = <0x1>;
				nvidia,tristate = <0x1>;
			};

			kb_col2_pq2 {
				nvidia,pins = "kb_col2_pq2";
				nvidia,function = "safe";
				nvidia,enable-input = <0x0>;
				nvidia,pull = <0x1>;
				nvidia,tristate = <0x1>;
			};

			kb_col4_pq4 {
				nvidia,pins = "kb_col4_pq4";
				nvidia,function = "safe";
				nvidia,enable-input = <0x0>;
				nvidia,pull = <0x0>;
				nvidia,tristate = <0x0>;
			};

			sdmmc1_wp_n_pv3 {
				nvidia,pins = "sdmmc1_wp_n_pv3";
				nvidia,function = "safe";
				nvidia,enable-input = <0x0>;
				nvidia,pull = <0x1>;
				nvidia,tristate = <0x1>;
			};

			pc7 {
				nvidia,pins = "pc7";
				nvidia,function = "safe";
				nvidia,enable-input = <0x0>;
				nvidia,pull = <0x1>;
				nvidia,tristate = <0x1>;
			};

			pi2 {
				nvidia,pins = "pi2";
				nvidia,function = "safe";
				nvidia,enable-input = <0x0>;
				nvidia,pull = <0x1>;
				nvidia,tristate = <0x1>;
			};

			pk3 {
				nvidia,pins = "pk3";
				nvidia,function = "safe";
				nvidia,enable-input = <0x0>;
				nvidia,pull = <0x1>;
				nvidia,tristate = <0x1>;
			};

			ph4 {
				nvidia,pins = "ph4";
				nvidia,function = "safe";
				nvidia,enable-input = <0x0>;
				nvidia,pull = <0x1>;
				nvidia,tristate = <0x1>;
			};

			pcc2 {
				nvidia,pins = "pcc2";
				nvidia,function = "safe";
				nvidia,enable-input = <0x0>;
				nvidia,pull = <0x1>;
				nvidia,tristate = <0x1>;
			};

			pg0 {
				nvidia,pins = "pg0";
				nvidia,function = "safe";
				nvidia,enable-input = <0x0>;
				nvidia,pull = <0x1>;
				nvidia,tristate = <0x1>;
			};

			pg1 {
				nvidia,pins = "pg1";
				nvidia,function = "safe";
				nvidia,enable-input = <0x0>;
				nvidia,pull = <0x1>;
				nvidia,tristate = <0x1>;
			};

			pk7 {
				nvidia,pins = "pk7";
				nvidia,function = "safe";
				nvidia,enable-input = <0x0>;
				nvidia,pull = <0x1>;
				nvidia,tristate = <0x1>;
			};

			pu0 {
				nvidia,pins = "pu0";
				nvidia,function = "safe";
				nvidia,enable-input = <0x0>;
				nvidia,pull = <0x1>;
				nvidia,tristate = <0x1>;
			};

			pu1 {
				nvidia,pins = "pu1";
				nvidia,function = "safe";
				nvidia,enable-input = <0x0>;
				nvidia,pull = <0x1>;
				nvidia,tristate = <0x1>;
			};

			pg4 {
				nvidia,pins = "pg4";
				nvidia,function = "safe";
				nvidia,enable-input = <0x0>;
				nvidia,pull = <0x1>;
				nvidia,tristate = <0x1>;
			};

			pg5 {
				nvidia,pins = "pg5";
				nvidia,function = "safe";
				nvidia,enable-input = <0x0>;
				nvidia,pull = <0x1>;
				nvidia,tristate = <0x1>;
			};

			usb_vbus_en0_pn4 {
				nvidia,pins = "usb_vbus_en0_pn4";
				nvidia,function = "safe";
				nvidia,enable-input = <0x0>;
				nvidia,pull = <0x1>;
				nvidia,tristate = <0x1>;
			};

			usb_vbus_en1_pn5 {
				nvidia,pins = "usb_vbus_en1_pn5";
				nvidia,function = "safe";
				nvidia,enable-input = <0x0>;
				nvidia,pull = <0x1>;
				nvidia,tristate = <0x1>;
			};

			usb_vbus_en2_pff1 {
				nvidia,pins = "usb_vbus_en2_pff1";
				nvidia,function = "safe";
				nvidia,enable-input = <0x0>;
				nvidia,pull = <0x1>;
				nvidia,tristate = <0x1>;
			};

			jtag_rtck {
				nvidia,pins = "jtag_rtck";
				nvidia,function = "safe";
				nvidia,enable-input = <0x0>;
				nvidia,pull = <0x1>;
				nvidia,tristate = <0x1>;
			};
		};

		drive {
			linux,phandle = <0x4>;
			phandle = <0x4>;

			drive_sdio1 {
				nvidia,pins = "drive_sdio1";
				nvidia,high-speed-mode = <0x1>;
				nvidia,schmitt = <0x0>;
				nvidia,pull-down-strength = <0x20>;
				nvidia,pull-up-strength = <0x2a>;
				nvidia,slew-rate-rising = <0x0>;
				nvidia,slew-rate-falling = <0x0>;
			};

			drive_sdio3 {
				nvidia,pins = "drive_sdio3";
				nvidia,high-speed-mode = <0x1>;
				nvidia,schmitt = <0x0>;
				nvidia,pull-down-strength = <0x14>;
				nvidia,pull-up-strength = <0x24>;
				nvidia,slew-rate-rising = <0x0>;
				nvidia,slew-rate-falling = <0x0>;
			};

			drive_gma {
				nvidia,pins = "drive_gma";
				nvidia,high-speed-mode = <0x1>;
				nvidia,schmitt = <0x0>;
				nvidia,low-power-mode = <0x3>;
				nvidia,pull-down-strength = <0x1>;
				nvidia,pull-up-strength = <0x2>;
				nvidia,slew-rate-rising = <0x0>;
				nvidia,slew-rate-falling = <0x0>;
				nvidia,drive-type = <0x1>;
			};
		};
	};

	serial@70006000 {
		compatible = "nvidia,tegra114-hsuart";
		reg = <0x0 0x70006000 0x0 0x40>;
		reg-shift = <0x2>;
		interrupts = <0x0 0x24 0x4>;
		nvidia,dma-request-selector = <0x6 0x8>;
		nvidia,memory-clients = <0xe>;
		status = "okay";
	};

	serial@70006040 {
		compatible = "nvidia,tegra114-hsuart";
		reg = <0x0 0x70006040 0x0 0x40>;
		reg-shift = <0x2>;
		interrupts = <0x0 0x25 0x4>;
		nvidia,dma-request-selector = <0x6 0x9>;
		nvidia,memory-clients = <0xe>;
		status = "okay";
	};

	serial@70006200 {
		compatible = "nvidia,tegra114-hsuart";
		reg = <0x0 0x70006200 0x0 0x40>;
		reg-shift = <0x2>;
		interrupts = <0x0 0x2e 0x4>;
		nvidia,dma-request-selector = <0x6 0xa>;
		nvidia,memory-clients = <0xe>;
		status = "okay";
	};

	serial@70006300 {
		compatible = "nvidia,tegra114-uart", "nvidia,tegra20-uart";
		reg = <0x0 0x70006300 0x0 0x40>;
		reg-shift = <0x2>;
		interrupts = <0x0 0x5a 0x4>;
		nvidia,dma-request-selector = <0x6 0x13>;
		nvidia,memory-clients = <0xe>;
		status = "disabled";
	};

	i2c@7000c000 {
		#address-cells = <0x1>;
		#size-cells = <0x0>;
		compatible = "nvidia,tegra124-i2c";
		reg = <0x0 0x7000c000 0x0 0x100>;
		interrupts = <0x0 0x26 0x4>;
		scl-gpio = <0x7 0x14 0x0>;
		sda-gpio = <0x7 0x15 0x0>;
		nvidia,memory-clients = <0xe>;
		status = "okay";
		clock-frequency = <0x61a80>;

		backlight@2c {
			compatible = "ti,lp8556";
			reg = <0x2c>;
			dev-ctrl = [83];
			init-brt = [1f];
			led-en = [0f];

			rom_98h {
				rom-addr = [98];
				rom-val = [80];
			};

			rom_9eh {
				rom-addr = [9e];
				rom-val = [21];
			};

			rom_a0h {
				rom-addr = [a0];
				rom-val = [ff];
			};

			rom_a1h {
				rom-addr = [a1];
				rom-val = [3f];
			};

			rom_a2h {
				rom-addr = [a2];
				rom-val = [20];
			};

			rom_a3h {
				rom-addr = [a3];
				rom-val = [00];
			};

			rom_a4h {
				rom-addr = [a4];
				rom-val = [72];
			};

			rom_a5h {
				rom-addr = [a5];
				rom-val = [24];
			};

			rom_a6h {
				rom-addr = [a6];
				rom-val = [80];
			};

			rom_a7h {
				rom-addr = [a7];
				rom-val = [f5];
			};

			rom_a8h {
				rom-addr = [a8];
				rom-val = [24];
			};

			rom_a9h {
				rom-addr = [a9];
				rom-val = [b2];
			};

			rom_aah {
				rom-addr = [aa];
				rom-val = [8f];
			};

			rom_aeh {
				rom-addr = [ae];
				rom-val = [0f];
			};
		};

		lsm6db0@08 {
			compatible = "st,lsm6db0";
			reg = <0x8>;
			st,irq-gpio = <0x7 0x8b 0x0>;
			st,reset-gpio = <0x7 0xb5 0x0>;
			st,wakeup-gpio = <0x7 0x90 0x0>;
		};

		bmp280@77 {
			compatible = "bmp,bmp280";
			reg = <0x77>;
		};

		isl29035@44 {
			compatible = "intersil,isl29035";
			reg = <0x44>;
			interrupt-parent = <0x7>;
			interrupts = <0xbb 0x8>;
			als_factor = <0x10>;
			als_highrange = <0x2>;
			als_lowthres = <0xe00>;
			als_highthres = <0xf800>;
			als_sensitive = <0x19>;
		};

		akm09911@0c {
			compatible = "akm,akm09911";
			reg = <0xc>;
			akm,layout = <0x6>;
			akm,gpio_rst = <0x84>;
		};

		mpu6515@68 {
			compatible = "inven,mpu6515";
			reg = <0x68>;
			interrupt-parent = <0x7>;
			interrupts = <0x8b 0x1>;
			regulator_config = <0x0>;
			fs_range = <0x0>;
			axis_map_x = <0x0>;
			axis_map_y = <0x1>;
			axis_map_z = <0x2>;
			negate_x = <0x0>;
			negate_y = <0x1>;
			negate_z = <0x1>;
			poll_interval = <0xc8>;
			min_interval = <0x5>;
			inven,secondary_type = "none";
			inven,secondary_reg = <0xc>;
			inven,secondary_name = "ak8963";
			inven,secondary_axis_map_x = <0x1>;
			inven,secondary_axis_map_y = <0x0>;
			inven,secondary_axis_map_z = <0x2>;
			inven,secondary_negate_x = <0x0>;
			inven,secondary_negate_y = <0x0>;
			inven,secondary_negate_z = <0x1>;
			inven,aux_type = "none";
			inven,aux_reg = <0x76>;
			inven,aus_name = "bmp280";
		};
	};

	i2c@7000c400 {
		#address-cells = <0x1>;
		#size-cells = <0x0>;
		compatible = "nvidia,tegra124-i2c";
		reg = <0x0 0x7000c400 0x0 0x100>;
		interrupts = <0x0 0x54 0x4>;
		scl-gpio = <0x7 0x9d 0x0>;
		sda-gpio = <0x7 0x9e 0x0>;
		nvidia,memory-clients = <0xe>;
		status = "okay";
		clock-frequency = <0x61a80>;

		bq2419x@6b {
			compatible = "ti,bq2419x";
			interrupt-parent = <0x7>;
			interrupts = <0x48 0x0>;
			reg = <0x6b>;

			charger {
				regulator-name = "batt_regulator";
				regulator-max-microamp = <0x1e8480>;
				ti,watchdog-timeout = <0x0>;
				rtc-alarm-time = <0xe10>;
				ti,auto-recharge-time = <0x3c>;
				ti,input-voltage-limit-millivolt = <0x10cc>;
				ti,fast-charge-current-limit-milliamp = <0x9c4>;
				ti,pre-charge-current-limit-milliamp = <0x100>;
				ti,charge-term-current-limit-milliamp = <0x190>;
				ti,ir-comp-resister-ohm = <0xa>;
				ti,ir-comp-voltage-millivolt = <0x20>;
				ti,thermal-regulation-threshold-degc = <0x64>;
				ti,charge-voltage-limit-millivolt = <0x10fe>;
				ti,disbale-suspend-during-charging;

				consumers {

					c1 {
						regulator-consumer-supply = "usb_bat_chg";
						regulator-consumer-device = "tegra-udc.0";
					};
				};
			};

			vbus {
				regulator-name = "vbus_regulator";

				consumers {

					c1 {
						regulator-consumer-supply = "usb_vbus";
						regulator-consumer-device = "tegra-ehci.0";
					};

					c2 {
						regulator-consumer-supply = "usb_vbus";
						regulator-consumer-device = "tegra-otg";
					};
				};
			};
		};
	};

	i2c@7000c500 {
		#address-cells = <0x1>;
		#size-cells = <0x0>;
		compatible = "nvidia,tegra124-i2c";
		reg = <0x0 0x7000c500 0x0 0x100>;
		interrupts = <0x0 0x5c 0x4>;
		scl-gpio = <0x7 0xd9 0x0>;
		sda-gpio = <0x7 0xda 0x0>;
		nvidia,memory-clients = <0xe>;
		status = "okay";
		clock-frequency = <0x61a80>;
	};

	i2c@7000c700 {
		#address-cells = <0x1>;
		#size-cells = <0x0>;
		compatible = "nvidia,tegra124-i2c";
		reg = <0x0 0x7000c700 0x0 0x100>;
		interrupts = <0x0 0x78 0x4>;
		scl-gpio = <0x7 0xac 0x0>;
		sda-gpio = <0x7 0xad 0x0>;
		nvidia,memory-clients = <0xe>;
		status = "okay";
		clock-frequency = <0x61a80>;
		nvidia,clock-always-on;
	};

	i2c@7000d000 {
		#address-cells = <0x1>;
		#size-cells = <0x0>;
		compatible = "nvidia,tegra124-i2c";
		reg = <0x0 0x7000d000 0x0 0x100>;
		interrupts = <0x0 0x35 0x4>;
		nvidia,require-cldvfs-clock;
		scl-gpio = <0x7 0xce 0x0>;
		sda-gpio = <0x7 0xcf 0x0>;
		nvidia,memory-clients = <0xe>;
		status = "okay";
		clock-frequency = <0x61a80>;
		nvidia,bit-banging-xfer-after-shutdown;

		tps65913 {
			compatible = "ti,palmas";
			reg = <0x58>;
			interrupts = <0x0 0x56 0x0>;
			#interrupt-cells = <0x2>;
			interrupt-controller;
			ti,long_press_delay = <0x1>;
			linux,phandle = <0x8>;
			phandle = <0x8>;

			gpio {
				compatible = "ti,palmas-gpio";
				gpio-controller;
				#gpio-cells = <0x2>;
				linux,phandle = <0x10>;
				phandle = <0x10>;
			};

			rtc {
				compatible = "ti,palmas-rtc";
				interrupt-parent = <0x8>;
				interrupts = <0x8 0x0>;
			};

			pinmux {
				compatible = "ti,tps65913-pinctrl";
				pinctrl-names = "default";
				pinctrl-0 = <0x9>;

				pinmux {
					linux,phandle = <0x9>;
					phandle = <0x9>;

					powergood {
						pins = "powergood";
						function = "powergood";
					};

					vac {
						pins = "vac";
						function = "vac";
					};

					pin_gpio0 {
						pins = "gpio0";
						function = "id";
						bias-pull-up;
					};

					pin_gpio1 {
						pins = "gpio1";
						function = "gpio";
					};

					pin_gpio6 {
						pins = "gpio2", "gpio3", "gpio4", "gpio6", "gpio7";
						function = "gpio";
					};

					pin_gpio5 {
						pins = "gpio5";
						function = "clk32kgaudio";
					};
				};
			};

			extcon {
				compatible = "ti,palmas-usb";
				extcon-name = "palmas-extcon";
				ti,wakeup;
				ti,enable-id-detection;
				ti,enable-vbus-detection;
			};

			power_pm {
				compatible = "ti,palmas-pm";
				system-pmic-power-off;
			};

			gpadc {
				compatible = "ti,palmas-gpadc";
				interrupt-parent = <0x8>;
				interrupts = <0x12 0x0 0x10 0x0 0x11 0x0>;
				ti,channel0-current-microamp = <0x14>;

				iio_map {

					ch1 {
						ti,adc-channel-number = <0x1>;
						ti,adc-consumer-device = "generic-adc-thermal.0";
						ti,adc-consumer-channel = "battery-temp-channel";
					};

					ch6 {
						ti,adc-channel-number = <0x6>;
						ti,adc-consumer-device = "palmas-battery";
						ti,adc-consumer-channel = "vbat_channel";
					};
				};
			};

			clock {
				compatible = "ti,palmas-clk";

				clk32k_kg {
					ti,clock-boot-enable;
				};

				clk32k_kg_audio {
					ti,clock-boot-enable;
				};
			};

			pmic {
				compatible = "ti,tps65913-pmic", "ti,palmas-pmic";
				ldo1-in-supply = <0xa>;
				ldo2-in-supply = <0xa>;
				ldo3-in-supply = <0xb>;
				ldo5-in-supply = <0xc>;
				ldo6-in-supply = <0xd>;
				ldo7-in-supply = <0xd>;
				ldo9-in-supply = <0xd>;
				ldoln-in-supply = <0xb>;
				smps10-out2-supply = <0xb>;

				regulators {

					smps123 {
						regulator-name = "vdd-cpu";
						regulator-min-microvolt = <0xaae60>;
						regulator-max-microvolt = <0x155cc0>;
						regulator-always-on;
						regulator-boot-on;
						ti,roof-floor = <0x1>;
						ti,config-flags = <0x8>;

						consumers {

							c1 {
								regulator-consumer-supply = "vdd_cpu";
							};
						};
					};

					smps45 {
						regulator-name = "vdd-gpu";
						regulator-min-microvolt = <0xaae60>;
						regulator-max-microvolt = <0x155cc0>;
						regulator-init-microvolt = <0xf4240>;
						regulator-boot-on;

						consumers {

							c1 {
								regulator-consumer-supply = "vdd_gpu";
							};
						};
					};

					smps6 {
						regulator-name = "vddio-ddr";
						regulator-min-microvolt = <0x124f80>;
						regulator-max-microvolt = <0x124f80>;
						regulator-always-on;
						regulator-boot-on;
						linux,phandle = <0xa>;
						phandle = <0xa>;

						consumers {

							c1 {
								regulator-consumer-supply = "vddio_ddr";
							};

							c2 {
								regulator-consumer-supply = "vddio_ddr_mclk";
							};

							c3 {
								regulator-consumer-supply = "vddio_ddr3";
							};

							c4 {
								regulator-consumer-supply = "vcore1_ddr3";
							};
						};
					};

					smps7 {
						regulator-name = "vdd-core";
						regulator-min-microvolt = <0xaae60>;
						regulator-max-microvolt = <0x155cc0>;
						regulator-always-on;
						regulator-boot-on;
						ti,roof-floor = <0x3>;

						consumers {

							c1 {
								regulator-consumer-supply = "vdd_core";
							};
						};
					};

					smps8 {
						regulator-name = "vdd-1v8";
						regulator-min-microvolt = <0x1b7740>;
						regulator-max-microvolt = <0x1b7740>;
						regulator-always-on;
						regulator-boot-on;
						linux,phandle = <0xc>;
						phandle = <0xc>;

						consumers {

							c1 {
								regulator-consumer-supply = "dbvdd";
								regulator-consumer-device = "tegra-snd-rt5639.0";
							};

							c2 {
								regulator-consumer-supply = "dbvdd";
								regulator-consumer-device = "tegra-snd-rt5645.0";
							};

							c3 {
								regulator-consumer-supply = "avdd";
								regulator-consumer-device = "tegra-snd-rt5639.0";
							};

							c4 {
								regulator-consumer-supply = "avdd";
								regulator-consumer-device = "tegra-snd-rt5645.0";
							};

							c5 {
								regulator-consumer-supply = "dmicvdd";
								regulator-consumer-device = "tegra-snd-rt5639.0";
							};

							c6 {
								regulator-consumer-supply = "dmicvdd";
								regulator-consumer-device = "tegra-snd-rt5645.0";
							};

							c7 {
								regulator-consumer-supply = "avdd_osc";
							};

							c8 {
								regulator-consumer-supply = "vddio_sys";
							};

							c9 {
								regulator-consumer-supply = "vddio_sys_2";
							};

							c10 {
								regulator-consumer-supply = "pwrdet_nand";
							};

							c11 {
								regulator-consumer-supply = "vddio_sdmmc";
								regulator-consumer-device = "sdhci-tegra.0";
							};

							c12 {
								regulator-consumer-supply = "pwrdet_sdmmc1";
							};

							c13 {
								regulator-consumer-supply = "vddio_sdmmc";
								regulator-consumer-device = "sdhci-tegra.3";
							};

							c14 {
								regulator-consumer-supply = "pwrdet_sdmmc4";
							};

							c15 {
								regulator-consumer-supply = "avdd_pll_utmip";
								regulator-consumer-device = "tegra-udc.0";
							};

							c16 {
								regulator-consumer-supply = "avdd_pll_utmip";
								regulator-consumer-device = "tegra-ehci.0";
							};

							c17 {
								regulator-consumer-supply = "avdd_pll_utmip";
								regulator-consumer-device = "tegra-ehci.1";
							};

							c18 {
								regulator-consumer-supply = "avdd_pll_utmip";
								regulator-consumer-device = "tegra-ehci.2";
							};

							c19 {
								regulator-consumer-supply = "avdd_pll_utmip";
								regulator-consumer-device = "tegra-xhci";
							};

							c20 {
								regulator-consumer-supply = "vddio_audio";
							};

							c21 {
								regulator-consumer-supply = "pwrdet_audio";
							};

							c22 {
								regulator-consumer-supply = "vddio_uart";
							};

							c23 {
								regulator-consumer-supply = "pwrdet_uart";
							};

							c24 {
								regulator-consumer-supply = "vddio_bb";
							};

							c25 {
								regulator-consumer-supply = "pwrdet_bb";
							};

							c26 {
								regulator-consumer-supply = "vdd_dtv";
							};

							c27 {
								regulator-consumer-supply = "vdd_1v8_eeprom";
							};

							c28 {
								regulator-consumer-supply = "vddio_cam";
								regulator-consumer-device = "tegra_camera";
							};

							c29 {
								regulator-consumer-supply = "vddio_cam";
								regulator-consumer-device = "vi";
							};

							c30 {
								regulator-consumer-supply = "pwrdet_cam";
							};

							c31 {
								regulator-consumer-supply = "dvdd";
								regulator-consumer-device = "spi0.0";
							};

							c32 {
								regulator-consumer-supply = "vdd";
								regulator-consumer-device = "0-004c";
							};

							c33 {
								regulator-consumer-supply = "vdd";
								regulator-consumer-device = "0-004d";
							};

							c34 {
								regulator-consumer-supply = "vddio";
								regulator-consumer-device = "0-0077";
							};

							c35 {
								regulator-consumer-supply = "dvdd_lcd";
							};

							c36 {
								regulator-consumer-supply = "vdd_lcd_1v8_s";
							};
						};
					};

					smps9 {
						regulator-name = "vdd-snsr";
						regulator-min-microvolt = <0x325aa0>;
						regulator-max-microvolt = <0x325aa0>;
						linux,phandle = <0xd>;
						phandle = <0xd>;

						consumers {

							c1 {
								regulator-consumer-supply = "vdd_snsr";
							};

							c2 {
								regulator-consumer-supply = "vddio_sd_slot";
								regulator-consumer-device = "sdhci-tegra.3";
							};

							c3 {
								regulator-consumer-supply = "vddio_sd_slot";
								regulator-consumer-device = "sdhci-tegra.2";
							};

							c4 {
								regulator-consumer-supply = "vdd_3v3_gps";
							};

							c5 {
								regulator-consumer-supply = "vdd_3v3_nfc";
							};

							c8 {
								regulator-consumer-supply = "vdd";
								regulator-consumer-device = "0-0077";
							};
						};
					};

					smps10_out1 {
						regulator-name = "vdd-out1-5v0";
						regulator-min-microvolt = <0x4c4b40>;
						regulator-max-microvolt = <0x4c4b40>;
						regulator-always-on;
						regulator-boot-on;
						linux,phandle = <0x11>;
						phandle = <0x11>;
					};

					smps10_out2 {
						regulator-name = "vdd-out2-5v0";
						regulator-min-microvolt = <0x4c4b40>;
						regulator-max-microvolt = <0x4c4b40>;
						linux,phandle = <0xb>;
						phandle = <0xb>;

						consumers {

							c1 {
								regulator-consumer-supply = "vdd_5v0_mdm";
							};

							c2 {
								regulator-consumer-supply = "vdd_5v0_snsr";
							};

							c3 {
								regulator-consumer-supply = "vdd_5v0_dis";
							};

							c6 {
								regulator-consumer-supply = "avddio_pex";
								regulator-consumer-device = "tegra-pcie";
							};

							c7 {
								regulator-consumer-supply = "dvddio_pex";
								regulator-consumer-device = "tegra-pcie";
							};

							c8 {
								regulator-consumer-supply = "avddio_usb";
								regulator-consumer-device = "tegra-xhci";
							};
						};
					};

					ldo1 {
						regulator-name = "avdd-pll";
						regulator-min-microvolt = <0x100590>;
						regulator-max-microvolt = <0x100590>;
						regulator-always-on;
						regulator-boot-on;
						ti,roof-floor = <0x3>;

						consumers {

							c1 {
								regulator-consumer-supply = "avdd_pll_m";
							};

							c2 {
								regulator-consumer-supply = "avdd_pll_ap_c2_c3";
							};

							c3 {
								regulator-consumer-supply = "avdd_pll_cud2dpd";
							};

							c4 {
								regulator-consumer-supply = "avdd_pll_c4";
							};

							c5 {
								regulator-consumer-supply = "avdd_lvds0_io";
							};

							c6 {
								regulator-consumer-supply = "vddio_ddr_hs";
							};

							c7 {
								regulator-consumer-supply = "avdd_pll_erefe";
							};

							c8 {
								regulator-consumer-supply = "avdd_pll_x";
							};

							c9 {
								regulator-consumer-supply = "avdd_pll_cg";
							};

							c10 {
								regulator-consumer-supply = "avdd_pex_pll";
								regulator-consumer-device = "tegra-pcie";
							};

							c11 {
								regulator-consumer-supply = "avdd_hdmi_pll";
								regulator-consumer-device = "tegradc.1";
							};
						};
					};

					ldo2 {
						regulator-name = "vdd-lcd-io";
						regulator-min-microvolt = <0x1b7740>;
						regulator-max-microvolt = <0x1b7740>;
						regulator-boot-on;

						consumers {

							c1 {
								regulator-consumer-supply = "vdd_cam_1v1_cam";
							};

							c2 {
								regulator-consumer-supply = "imx179_reg2";
							};

							c3 {
								regulator-consumer-supply = "vdd_1v2_cam";
							};

							c4 {
								regulator-consumer-supply = "vdig";
								regulator-consumer-device = "2-0010";
							};

							c5 {
								regulator-consumer-supply = "dvdd";
								regulator-consumer-device = "2-0036";
							};

							c6 {
								regulator-consumer-supply = "vdig";
								regulator-consumer-device = "2-0036";
							};

							c7 {
								regulator-consumer-supply = "vdig_lv";
								regulator-consumer-device = "2-0010";
							};

							c8 {
								regulator-consumer-supply = "dvdd_lcdio";
							};
						};
					};

					ldo3 {
						regulator-name = "vdd-touch";
						regulator-min-microvolt = <0x325aa0>;
						regulator-max-microvolt = <0x325aa0>;

						consumers {

							c1 {
								regulator-consumer-supply = "avdd";
								regulator-consumer-device = "spi0.0";
							};

							c2 {
								regulator-consumer-supply = "vdd-touch";
								regulator-consumer-device = "3-004a";
							};
						};
					};

					ldo4 {
						regulator-name = "avdd-cam";
						regulator-min-microvolt = <0x2932e0>;
						regulator-max-microvolt = <0x2932e0>;

						consumers {

							c1 {
								regulator-consumer-supply = "vdd_2v7_hv";
							};

							c2 {
								regulator-consumer-supply = "avdd_cam1_cam";
							};

							c3 {
								regulator-consumer-supply = "avdd_cam2_cam";
							};

							c4 {
								regulator-consumer-supply = "avdd_cam3_cam";
							};

							c5 {
								regulator-consumer-supply = "vana";
								regulator-consumer-device = "2-0010";
							};

							c6 {
								regulator-consumer-supply = "avdd";
								regulator-consumer-device = "2-0010";
							};

							c7 {
								regulator-consumer-supply = "avdd_ov5693";
								regulator-consumer-device = "2-0036";
							};
						};
					};

					ldo5 {
						regulator-name = "avdd-dsi-csi";
						regulator-min-microvolt = <0x124f80>;
						regulator-max-microvolt = <0x124f80>;

						consumers {

							c1 {
								regulator-consumer-supply = "vddio_hsic";
								regulator-consumer-device = "tegra-ehci.1";
							};

							c2 {
								regulator-consumer-supply = "vddio_hsic";
								regulator-consumer-device = "tegra-ehci.2";
							};

							c3 {
								regulator-consumer-supply = "vddio_hsic";
								regulator-consumer-device = "tegra-xhci";
							};

							c4 {
								regulator-consumer-supply = "avdd_dsi_csi";
								regulator-consumer-device = "tegradc.0";
							};

							c5 {
								regulator-consumer-supply = "avdd_dsi_csi";
								regulator-consumer-device = "tegradc.1";
							};

							c6 {
								regulator-consumer-supply = "avdd_dsi_csi";
								regulator-consumer-device = "vi.0";
							};

							c7 {
								regulator-consumer-supply = "avdd_dsi_csi";
								regulator-consumer-device = "vi.1";
							};

							c8 {
								regulator-consumer-supply = "pwrdet_mipi";
							};

							c9 {
								regulator-consumer-supply = "avdd_hsic_com";
							};

							c10 {
								regulator-consumer-supply = "avdd_hsic_mdm";
							};

							c11 {
								regulator-consumer-supply = "vdd_lcd_bl";
							};
						};
					};

					ldo6 {
						regulator-name = "vdd-cam-af";
						regulator-min-microvolt = <0x1b7740>;
						regulator-max-microvolt = <0x1b7740>;

						consumers {

							c1 {
								regulator-consumer-supply = "vdd_cam1_1v8_cam";
							};

							c2 {
								regulator-consumer-supply = "vdd_cam2_1v8_cam";
							};

							c3 {
								regulator-consumer-supply = "vif";
								regulator-consumer-device = "2-0010";
							};

							c4 {
								regulator-consumer-supply = "dovdd";
								regulator-consumer-device = "2-0036";
							};

							c5 {
								regulator-consumer-supply = "vif2";
								regulator-consumer-device = "2-0021";
							};

							c6 {
								regulator-consumer-supply = "vif";
								regulator-consumer-device = "2-0036";
							};

							c7 {
								regulator-consumer-supply = "vdd_i2c";
								regulator-consumer-device = "2-000c";
							};

							c8 {
								regulator-consumer-supply = "vi2c";
								regulator-consumer-device = "2-0030";
							};

							c9 {
								regulator-consumer-supply = "vdd";
								regulator-consumer-device = "2-004a";
							};

							c10 {
								regulator-consumer-supply = "vif";
								regulator-consumer-device = "2-0048";
							};
						};
					};

					ldo7 {
						regulator-name = "avdd-cam-af";
						regulator-min-microvolt = <0x2932e0>;
						regulator-max-microvolt = <0x2932e0>;

						consumers {

							c1 {
								regulator-consumer-supply = "avdd_af1_cam";
							};

							c2 {
								regulator-consumer-supply = "imx179_reg1";
							};

							c3 {
								regulator-consumer-supply = "vana";
								regulator-consumer-device = "2-0021";
							};

							c4 {
								regulator-consumer-supply = "vdd";
								regulator-consumer-device = "2-000c";
							};

							c5 {
								regulator-consumer-supply = "vdd_af1";
								regulator-consumer-device = "2-0010";
							};

							c6 {
								regulator-consumer-supply = "vin";
								regulator-consumer-device = "2-0030";
							};

							c7 {
								regulator-consumer-supply = "vin";
								regulator-consumer-device = "2-004a";
							};

							c8 {
								regulator-consumer-supply = "vana";
								regulator-consumer-device = "2-0036";
							};

							c9 {
								regulator-consumer-supply = "vana";
								regulator-consumer-device = "2-0048";
							};
						};
					};

					ldo8 {
						regulator-name = "vdd-rtc";
						regulator-min-microvolt = <0xe7ef0>;
						regulator-max-microvolt = <0xe7ef0>;
						regulator-always-on;
						regulator-boot-on;

						consumers {

							c1 {
								regulator-consumer-supply = "vdd_rtc";
							};
						};
					};

					ldo9 {
						regulator-name = "vddio-sdmmc-2";
						regulator-min-microvolt = <0x1b7740>;
						regulator-max-microvolt = <0x325aa0>;

						consumers {

							c1 {
								regulator-consumer-supply = "vddio_sdmmc";
								regulator-consumer-device = "sdhci-tegra.2";
							};

							c2 {
								regulator-consumer-supply = "pwrdet_sdmmc3";
							};
						};
					};

					ldoln {
						regulator-name = "vddio-hv";
						regulator-min-microvolt = <0x325aa0>;
						regulator-max-microvolt = <0x325aa0>;
						regulator-always-on;
						regulator-boot-on;

						consumers {

							c1 {
								regulator-consumer-supply = "vddio_hv";
								regulator-consumer-device = "tegradc.1";
							};

							c2 {
								regulator-consumer-supply = "avdd_hdmi";
								regulator-consumer-device = "tegradc.1";
							};

							c3 {
								regulator-consumer-supply = "pwrdet_hv";
							};

							c4 {
								regulator-consumer-supply = "vddio_pex_ctl";
								regulator-consumer-device = "tegra-pcie";
							};
						};
					};

					ldousb {
						regulator-name = "avdd-usb";
						regulator-min-microvolt = <0x325aa0>;
						regulator-max-microvolt = <0x325aa0>;
						regulator-always-on;
						regulator-boot-on;

						consumers {

							c1 {
								regulator-consumer-supply = "pwrdet_pex_ctl";
							};

							c2 {
								regulator-consumer-supply = "avdd_usb";
								regulator-consumer-device = "tegra-udc.0";
							};

							c3 {
								regulator-consumer-supply = "avdd_usb";
								regulator-consumer-device = "tegra-ehci.0";
							};

							c4 {
								regulator-consumer-supply = "avdd_usb";
								regulator-consumer-device = "tegra-ehci.1";
							};

							c5 {
								regulator-consumer-supply = "avdd_usb";
								regulator-consumer-device = "tegra-ehci.2";
							};

							c6 {
								regulator-consumer-supply = "hvdd_usb";
								regulator-consumer-device = "tegra-xhci";
							};

							c7 {
								regulator-consumer-supply = "hvdd_pex";
								regulator-consumer-device = "tegra-pcie";
							};

							c8 {
								regulator-consumer-supply = "hvdd_pex_pll_e";
								regulator-consumer-device = "tegra-pcie";
							};
						};
					};
				};
			};
		};
	};

	i2c@7000d100 {
		#address-cells = <0x1>;
		#size-cells = <0x0>;
		compatible = "nvidia,tegra124-i2c";
		reg = <0x0 0x7000d100 0x0 0x100>;
		interrupts = <0x0 0x3f 0x4>;
		nvidia,memory-clients = <0xe>;
		status = "okay";
		clock-frequency = <0x61a80>;
	};

	spi@7000d400 {
		compatible = "nvidia,tegra114-spi";
		reg = <0x0 0x7000d400 0x0 0x200>;
		interrupts = <0x0 0x3b 0x4>;
		nvidia,dma-request-selector = <0x6 0xf>;
		nvidia,memory-clients = <0xe>;
		#address-cells = <0x1>;
		#size-cells = <0x0>;
		status = "okay";
		spi-max-frequency = <0x17d7840>;
	};

	spi@7000d600 {
		compatible = "nvidia,tegra114-spi";
		reg = <0x0 0x7000d600 0x0 0x200>;
		interrupts = <0x0 0x52 0x4>;
		nvidia,dma-request-selector = <0x6 0x10>;
		nvidia,memory-clients = <0xe>;
		#address-cells = <0x1>;
		#size-cells = <0x0>;
		status = "disabled";
	};

	spi@7000d800 {
		compatible = "nvidia,tegra114-spi";
		reg = <0x0 0x7000d800 0x0 0x200>;
		interrupts = <0x0 0x53 0x4>;
		nvidia,dma-request-selector = <0x6 0x11>;
		nvidia,memory-clients = <0xe>;
		#address-cells = <0x1>;
		#size-cells = <0x0>;
		status = "disabled";
	};

	spi@7000da00 {
		compatible = "nvidia,tegra114-spi";
		reg = <0x0 0x7000da00 0x0 0x200>;
		interrupts = <0x0 0x5d 0x4>;
		nvidia,dma-request-selector = <0x6 0x12>;
		nvidia,memory-clients = <0xe>;
		#address-cells = <0x1>;
		#size-cells = <0x0>;
		status = "okay";
		spi-max-frequency = <0x17d7840>;
	};

	spi@7000dc00 {
		compatible = "nvidia,tegra114-spi";
		reg = <0x0 0x7000dc00 0x0 0x200>;
		interrupts = <0x0 0x5e 0x4>;
		nvidia,dma-request-selector = <0x6 0x1b>;
		nvidia,memory-clients = <0xe>;
		#address-cells = <0x1>;
		#size-cells = <0x0>;
		status = "disabled";
	};

	spi@7000de00 {
		compatible = "nvidia,tegra114-spi";
		reg = <0x0 0x7000de00 0x0 0x200>;
		interrupts = <0x0 0x4f 0x4>;
		nvidia,dma-request-selector = <0x6 0x1c>;
		nvidia,memory-clients = <0xe>;
		#address-cells = <0x1>;
		#size-cells = <0x0>;
		status = "disabled";
	};

	pmc {
		compatible = "nvidia,tegra124-pmc";
		reg = <0x0 0x7000e400 0x0 0x400>;
		clocks = <0xe 0x105 0xf>;
		clock-names = "pclk", "clk32k_in";
	};

	efuse@7000f800 {
		compatible = "nvidia,tegra124-efuse";
		reg = <0x0 0x7000f800 0x0 0x400>;
	};

	clocks {
		compatible = "simple-bus";
		#address-cells = <0x1>;
		#size-cells = <0x0>;

		clock {
			compatible = "fixed-clock";
			reg = <0x0>;
			#clock-cells = <0x0>;
			clock-frequency = <0x8000>;
			linux,phandle = <0xf>;
			phandle = <0xf>;
		};
	};

	timer@60005000 {
		compatible = "nvidia,tegra-nvtimer";
		reg = <0x0 0x60005000 0x0 0x400>;
		interrupts = <0x0 0x0 0x4 0x0 0x1 0x4 0x0 0x29 0x4 0x0 0x2a 0x4 0x0 0x79 0x4 0x0 0x97 0x4 0x0 0x98 0x4 0x0 0x99 0x4 0x0 0x9a 0x4 0x0 0x9b 0x4 0x0 0x7a 0x4>;
		clocks = <0xe 0x5>;
	};

	rtc {
		compatible = "nvidia,tegra-rtc";
		reg = <0x0 0x7000e000 0x0 0x100>;
		interrupts = <0x0 0x2 0x4>;
		clocks = <0xe 0x4>;
	};

	ahub {
		compatible = "nvidia,tegra124-ahub";
		reg = <0x0 0x70300000 0x0 0x200 0x0 0x70300800 0x0 0x800 0x0 0x70300200 0x0 0x200>;
		interrupts = <0x0 0x67 0x4>;
		nvidia,dma-request-selector = <0x6 0x1 0x6 0x2 0x6 0x3 0x6 0x4 0x6 0x6 0x6 0x7 0x6 0xc 0x6 0xd 0x6 0xe 0x6 0x1d>;
		status = "disabled";
		ranges;
		#address-cells = <0x2>;
		#size-cells = <0x2>;

		i2s@70301000 {
			compatible = "nvidia,tegra124-i2s";
			reg = <0x0 0x70301000 0x0 0x100>;
			nvidia,ahub-cif-ids = <0x4 0x4>;
			status = "disabled";
		};

		i2s@70301100 {
			compatible = "nvidia,tegra124-i2s";
			reg = <0x0 0x70301100 0x0 0x100>;
			nvidia,ahub-cif-ids = <0x5 0x5>;
			status = "disabled";
		};

		i2s@70301200 {
			compatible = "nvidia,tegra124-i2s";
			reg = <0x0 0x70301200 0x0 0x100>;
			nvidia,ahub-cif-ids = <0x6 0x6>;
			status = "disabled";
		};

		i2s@70301300 {
			compatible = "nvidia,tegra124-i2s";
			reg = <0x0 0x70301300 0x0 0x100>;
			nvidia,ahub-cif-ids = <0x7 0x7>;
			status = "disabled";
		};

		i2s@70301400 {
			compatible = "nvidia,tegra124-i2s";
			reg = <0x0 0x70301400 0x0 0x100>;
			nvidia,ahub-cif-ids = <0x8 0x8>;
			status = "disabled";
		};

		amx@70303000 {
			compatible = "nvidia,tegra124-amx";
			reg = <0x0 0x70303000 0x0 0x100>;
			status = "disabled";
		};

		amx@70303100 {
			compatible = "nvidia,tegra124-amx";
			reg = <0x0 0x70303100 0x0 0x100>;
			status = "disabled";
		};

		adx@70303800 {
			compatible = "nvidia,tegra124-adx";
			reg = <0x0 0x70303800 0x0 0x100>;
			status = "disabled";
		};

		adx@70303900 {
			compatible = "nvidia,tegra124-adx";
			reg = <0x0 0x70303900 0x0 0x100>;
			status = "disabled";
		};

		spdif@70306000 {
			compatible = "nvidia,tegra124-spdif";
			reg = <0x0 0x70306000 0x0 0x100>;
			status = "disabled";
		};
	};

	host1x {
		compatible = "nvidia,tegra124-host1x", "simple-bus";
		reg = <0x0 0x50000000 0x0 0x28000>;
		interrupts = <0x0 0x41 0x4 0x0 0x43 0x4>;
		nvidia,memory-clients = <0x4 0x6 0x7 0x11>;
		#address-cells = <0x1>;
		#size-cells = <0x1>;
		ranges = <0x53000000 0x0 0x53000000 0x6000000 0x60001000 0x0 0x60001000 0xe200>;

		vi {
			compatible = "nvidia,tegra124-vi";
			reg = <0x54080000 0x40000>;
			interrupts = <0x0 0x45 0x4>;
			nvidia,memory-clients = <0x12>;
		};

		isp@54600000 {
			compatible = "nvidia,tegra124-isp";
			reg = <0x54600000 0x40000>;
			interrupts = <0x0 0x47 0x4>;
			nvidia,memory-clients = <0x8 0x1d>;
		};

		isp@54680000 {
			compatible = "nvidia,tegra124-isp";
			reg = <0x54680000 0x40000>;
			interrupts = <0x0 0x46 0x4>;
			nvidia,memory-clients = <0x8 0x1d>;
		};

		dc@54200000 {
			compatible = "nvidia,tegra124-dc";
			reg = <0x54200000 0x40000>;
			interrupts = <0x0 0x49 0x4>;
			nvidia,memory-clients = <0x2>;
			status = "disabled";

			rgb {
				status = "disabled";
			};
		};

		dc@54240000 {
			compatible = "nvidia,tegra124-dc";
			reg = <0x54240000 0x40000>;
			interrupts = <0x0 0x4a 0x4>;
			nvidia,memory-clients = <0x3>;
			status = "disabled";

			rgb {
				status = "disabled";
			};
		};

		hdmi {
			compatible = "nvidia,tegra124-hdmi";
			reg = <0x54280000 0x40000>;
			interrupts = <0x0 0x4b 0x4>;
			status = "okay";
		};

		dsi {
			compatible = "nvidia,tegra124-dsi";
			reg = <0x54300000 0x40000 0x54400000 0x40000>;
			status = "disabled";
		};

		vic {
			compatible = "nvidia,tegra124-vic";
			reg = <0x54340000 0x40000>;
			nvidia,memory-clients = <0x13>;
		};

		msenc {
			compatible = "nvidia,tegra124-msenc";
			reg = <0x544c0000 0x40000>;
			nvidia,memory-clients = <0xb>;
		};

		tsec {
			compatible = "nvidia,tegra124-tsec";
			reg = <0x54500000 0x40000>;
			nvidia,memory-clients = <0x17>;
		};

		gk20a {
			compatible = "nvidia,tegra124-gk20a";
			reg = <0x57000000 0x1000000 0x58000000 0x1000000 0x538f0000 0x1000>;
			interrupts = <0x0 0x9d 0x4 0x0 0x9e 0x4>;
			nvidia,memory-clients = <0x1e 0x1f>;
		};

		nvavp {
			compatible = "nvidia,tegra124-nvavp";
			interrupts = <0x0 0x4 0x4>;
			reg = <0x60001000 0xe200>;
		};
	};

	xusb@70090000 {
		compatible = "nvidia,tegra124-xhci";
		reg = <0x0 0x70090000 0x0 0x8000 0x0 0x70098000 0x0 0x1000 0x0 0x70099000 0x0 0x1000 0x0 0x7009f000 0x0 0x1000>;
		interrupts = <0x0 0x27 0x4 0x0 0x28 0x4 0x0 0x31 0x4 0x0 0x61 0x4 0x0 0x15 0x4>;
		status = "okay";
		nvidia,gpio_ss1_sata = <0x0>;
		nvidia,portmap = <0x101>;
		nvidia,ss_portmap = <0x0>;
		nvidia,lane_owner = <0x4>;
		nvidia,ulpicap = <0x0>;
		nvidia,supply_utmi_vbuses = "usb_vbus0", "usb_vbus1", "usb_vbus2";
		nvidia,supply_s3p3v = "hvdd_usb";
		nvidia,supply_s1p8v = "avdd_pll_utmip";
		nvidia,supply_vddio_hsic = "vddio_hsic";
		nvidia,supply_s1p05v = "avddio_usb";
	};

	mipical {
		compatible = "nvidia,tegra124-mipical";
		reg = <0x0 0x700e3000 0x0 0x100>;
	};

	pcie-controller {
		compatible = "nvidia,tegra124-pcie";
		status = "disabled";
	};

	sata-controller {
		compatible = "nvidia,tegra124-sata";
		reg = <0x0 0x70027000 0x0 0x2000 0x0 0x70021000 0x0 0x1000>;
		interrupts = <0x0 0x17 0x4>;
		status = "disabled";
	};

	psci {
		compatible = "arm,psci";
		method = "smc";
		cpu_suspend = <0x84000001>;
		cpu_on = <0x84000003>;
	};

	udc@7d000000 {
		compatible = "nvidia,tegra124-udc";
		reg = <0x0 0x7d000000 0x0 0x4000>;
		interrupts = <0x0 0x14 0x4>;
		status = "disabled";
		nvidia,port-otg;
		nvidia,charging-supported;
		nvidia,turn-off-vbus-in-lp0;
		nvidia,dcp-current-limit-ma = <0xbb8>;
	};

	otg@7d000000 {
		compatible = "nvidia,tegra124-otg";
		reg = <0x0 0x7d000000 0x0 0x4000>;
		interrupts = <0x0 0x14 0x4>;
		status = "disabled";
		nvidia,turn-off-vbus-in-lp0;
	};

	interrupt-controller@50041000 {
		compatible = "arm,cortex-a15-gic";
		interrupt-controller;
		#interrupt-cells = <0x3>;
		reg = <0x0 0x50041000 0x0 0x1000 0x0 0x50042000 0x0 0x100>;
		linux,phandle = <0x1>;
		phandle = <0x1>;
	};

	interrupt-controller@60004000 {
		compatible = "nvidia,tegra-gic";
		interrupt-controller;
		reg = <0x0 0x60004000 0x0 0x40 0x0 0x60004100 0x0 0x40 0x0 0x60004200 0x0 0x40 0x0 0x60004300 0x0 0x40 0x0 0x60004400 0x0 0x40>;
	};

	timer {
		compatible = "arm,armv7-timer";
		interrupts = <0x1 0xd 0xf04 0x1 0xe 0xf04>;
	};

	dfll@70110000 {
		compatible = "nvidia,tegra124-dfll";
		reg = <0x0 0x70110000 0x0 0x400>;
		out-clock-name = "dfll_cpu";
		status = "disabled";
	};

	watchdog@60005100 {
		compatible = "nvidia,tegra-wdt";
		reg = <0x0 0x60005100 0x0 0x20 0x0 0x60005070 0x0 0x8>;
	};

	pwm {
		compatible = "nvidia,tegra124-pwm";
		reg = <0x0 0x7000a000 0x0 0x100>;
		#pwm-cells = <0x2>;
		clocks = <0xe 0x11>;
		status = "okay";
		linux,phandle = <0x12>;
		phandle = <0x12>;
	};

	memory@0x80000000 {
		device_type = "memory";
		reg = <0x0 0x80000000 0x0 0x80000000>;
	};

	memory-controller@7001b000 {
		compatible = "nvidia,tegra12-emc";
		reg = <0x0 0x7001b000 0x0 0x800>;
		#address-cells = <0x1>;
		#size-cells = <0x0>;

		emc-table@12750 {
			compatible = "nvidia,tegra12-emc-table";
			nvidia,revision = <0x19>;
			nvidia,dvfs-version = "3_12750_02_V5.0.14_V1.1";
			clock-frequency = <0x31ce>;
			nvidia,emc-min-mv = <0x320>;
			nvidia,gk20a-min-mv = <0x320>;
			nvidia,source = "pllp_out0";
			nvidia,src-sel-reg = <0x4000003e>;
			nvidia,burst-regs-num = <0xa5>;
			nvidia,burst-up-down-regs-num = <0x1f>;
			nvidia,emc-registers = <0x0 0x3 0x0 0x2 0x2 0x6 0x8 0x3 0xa 0x2 0x2 0x1 0x2 0x0 0x3 0x3 0x6 0x2 0x0 0x5 0x5 0x10000 0x3 0x0 0x0 0x0 0x0 0x4 0xc 0xd 0xf 0x30 0x0 0xc 0x2 0x2 0x2 0x0 0x1 0xc 0x3 0x3 0x3 0x3 0x3 0x6 0x4 0x3 0x3 0x56 0x0 0x0 0x0 0x1363a296 0x5800a0 0x8000 0x48000 0x48000 0x48000 0x48000 0x48000 0x48000 0x48000 0x48000 0x48000 0x48000 0x48000 0x48000 0x48000 0x48000 0x48000 0x48000 0x0 0x0 0x0 0x0 0x0 0x0 0x0 0x0 0xfc000 0xfc000 0x0 0xfc000 0xfc000 0x0 0x0 0x0 0x0 0x0 0x0 0x0 0x0 0x0 0x0 0x0 0x0 0x0 0x0 0x0 0x0 0x0 0x0 0x0 0x0 0x0 0x0 0x0 0x0 0x0 0xfc000 0xfc000 0xfc000 0xfc000 0xfc00 0xfc00 0xfc00 0xfc00 0x200 0x0 0x100100 0x130b018 0x0 0x0 0x77ffc000 0x303 0x81f1f008 0x7070000 0x3f 0x15ddddd 0x51451400 0x514514 0x514514 0x51451400 0x3f 0x0 0x0 0x64000 0x11 0xd0011 0xd0011 0x0 0x3 0xf3f3 0x80000164 0xa 0x40040001 0x8000000a 0x1 0x1 0x2 0x0 0x3 0x1 0x2 0x7 0x2 0x1 0x4 0x5 0x5040102 0x90402 0x77c30303 0x70000f03 0x1f0000>;
			nvidia,emc-burst-up-down-regs = <0x1 0x7 0xff00ff 0xff00ff 0xff00ff 0xff00ff 0xff00ff 0xff00ff 0xff00ff 0xff0049 0xff0080 0xff0004 0xff0004 0x800ff 0xff 0xff0004 0xff00ff 0xff00ff 0xff0024 0xff00ff 0xff 0xff 0xff00ff 0xff 0xff00ff 0xff00ff 0xff00ff 0xff00ff 0xff00ff 0xff00ff 0xff00ff>;
			nvidia,emc-zcal-cnt-long = <0x15>;
			nvidia,emc-acal-interval = <0x1fffff>;
			nvidia,emc-ctt-term_ctrl = <0x802>;
			nvidia,emc-cfg = <0xf3200000>;
			nvidia,emc-cfg-2 = <0x8c7>;
			nvidia,emc-sel-dpd-ctrl = <0x4013c>;
			nvidia,emc-cfg-dig-dll = <0x580068>;
			nvidia,emc-bgbias-ctl0 = <0x8>;
			nvidia,emc-auto-cal-config2 = <0x0>;
			nvidia,emc-auto-cal-config3 = <0x0>;
			nvidia,emc-auto-cal-config = <0xa1430000>;
			nvidia,emc-mode-0 = <0x0>;
			nvidia,emc-mode-1 = <0x10083>;
			nvidia,emc-mode-2 = <0x20004>;
			nvidia,emc-mode-4 = <0x800b0000>;
			nvidia,emc-clock-latency-change = <0xe1dc>;
		};

		emc-table@20400 {
			compatible = "nvidia,tegra12-emc-table";
			nvidia,revision = <0x19>;
			nvidia,dvfs-version = "3_20400_02_V5.0.14_V1.1";
			clock-frequency = <0x4fb0>;
			nvidia,emc-min-mv = <0x320>;
			nvidia,gk20a-min-mv = <0x320>;
			nvidia,source = "pllp_out0";
			nvidia,src-sel-reg = <0x40000026>;
			nvidia,burst-regs-num = <0xa5>;
			nvidia,burst-up-down-regs-num = <0x1f>;
			nvidia,emc-registers = <0x1 0x4 0x0 0x2 0x2 0x6 0x8 0x3 0xa 0x2 0x2 0x1 0x2 0x0 0x3 0x3 0x6 0x2 0x0 0x5 0x5 0x10000 0x3 0x0 0x0 0x0 0x0 0x4 0xc 0xd 0xf 0x4d 0x0 0x13 0x2 0x2 0x2 0x0 0x1 0xc 0x5 0x5 0x3 0x3 0x3 0x6 0x4 0x3 0x3 0x8a 0x0 0x0 0x0 0x1363a296 0x5800a0 0x8000 0x48000 0x48000 0x48000 0x48000 0x48000 0x48000 0x48000 0x48000 0x48000 0x48000 0x48000 0x48000 0x48000 0x48000 0x48000 0x48000 0x0 0x0 0x0 0x0 0x0 0x0 0x0 0x0 0xfc000 0xfc000 0x0 0xfc000 0xfc000 0x0 0x0 0x0 0x0 0x0 0x0 0x0 0x0 0x0 0x0 0x0 0x0 0x0 0x0 0x0 0x0 0x0 0x0 0x0 0x0 0x0 0x0 0x0 0x0 0x0 0xfc000 0xfc000 0xfc000 0xfc000 0xfc00 0xfc00 0xfc00 0xfc00 0x200 0x0 0x100100 0x130b018 0x0 0x0 0x77ffc000 0x303 0x81f1f008 0x7070000 0x3f 0x15ddddd 0x51451400 0x514514 0x514514 0x51451400 0x3f 0x0 0x0 0x64000 0x11 0x150011 0x150011 0x0 0x3 0xf3f3 0x8000019f 0xa 0x40020001 0x80000012 0x1 0x1 0x2 0x0 0x3 0x1 0x2 0x7 0x2 0x1 0x4 0x5 0x5040102 0x90402 0x75a30303 0x70000f03 0x1f0000>;
			nvidia,emc-burst-up-down-regs = <0x1 0xa 0xff00ff 0xff00ff 0xff00ff 0xff00ff 0xff00ff 0xff00ff 0xff00ff 0xff0049 0xff0080 0xff0004 0xff0004 0x800ff 0xff 0xff0004 0xff00ff 0xff00ff 0xff0024 0xff00ff 0xff 0xff 0xff00ff 0xff 0xff00ff 0xff00ff 0xff00ff 0xff00ff 0xff00ff 0xff00ff 0xff00ff>;
			nvidia,emc-zcal-cnt-long = <0x15>;
			nvidia,emc-acal-interval = <0x1fffff>;
			nvidia,emc-ctt-term_ctrl = <0x802>;
			nvidia,emc-cfg = <0xf3200000>;
			nvidia,emc-cfg-2 = <0x8c7>;
			nvidia,emc-sel-dpd-ctrl = <0x4013c>;
			nvidia,emc-cfg-dig-dll = <0x580068>;
			nvidia,emc-bgbias-ctl0 = <0x8>;
			nvidia,emc-auto-cal-config2 = <0x0>;
			nvidia,emc-auto-cal-config3 = <0x0>;
			nvidia,emc-auto-cal-config = <0xa1430000>;
			nvidia,emc-mode-0 = <0x0>;
			nvidia,emc-mode-1 = <0x10083>;
			nvidia,emc-mode-2 = <0x20004>;
			nvidia,emc-mode-4 = <0x800b0000>;
			nvidia,emc-clock-latency-change = <0x8b1a>;
		};

		emc-table@40800 {
			compatible = "nvidia,tegra12-emc-table";
			nvidia,revision = <0x19>;
			nvidia,dvfs-version = "3_40800_02_V5.0.14_V1.1";
			clock-frequency = <0x9f60>;
			nvidia,emc-min-mv = <0x320>;
			nvidia,gk20a-min-mv = <0x320>;
			nvidia,source = "pllp_out0";
			nvidia,src-sel-reg = <0x40000012>;
			nvidia,burst-regs-num = <0xa5>;
			nvidia,burst-up-down-regs-num = <0x1f>;
			nvidia,emc-registers = <0x2 0x8 0x0 0x2 0x2 0x6 0x8 0x3 0xa 0x2 0x2 0x1 0x2 0x0 0x3 0x3 0x6 0x2 0x0 0x5 0x5 0x10000 0x3 0x0 0x0 0x0 0x0 0x4 0xc 0xd 0xf 0x9a 0x0 0x26 0x2 0x2 0x2 0x0 0x1 0xc 0x9 0x9 0x3 0x3 0x3 0x6 0x4 0x3 0x3 0x113 0x0 0x0 0x0 0x1363a296 0x5800a0 0x8000 0x48000 0x48000 0x48000 0x48000 0x48000 0x48000 0x48000 0x48000 0x48000 0x48000 0x48000 0x48000 0x48000 0x48000 0x48000 0x48000 0x0 0x0 0x0 0x0 0x0 0x0 0x0 0x0 0xfc000 0xfc000 0x0 0xfc000 0xfc000 0x0 0x0 0x0 0x0 0x0 0x0 0x0 0x0 0x0 0x0 0x0 0x0 0x0 0x0 0x0 0x0 0x0 0x0 0x0 0x0 0x0 0x0 0x0 0x0 0x0 0xfc000 0xfc000 0xfc000 0xfc000 0xfc00 0xfc00 0xfc00 0xfc00 0x200 0x0 0x100100 0x130b018 0x0 0x0 0x77ffc000 0x303 0x81f1f008 0x7070000 0x3f 0x15ddddd 0x51451400 0x514514 0x514514 0x51451400 0x3f 0x0 0x0 0x64000 0x11 0x290011 0x290011 0x0 0x3 0xf3f3 0x8000023a 0xa 0xa0000001 0x80000017 0x1 0x1 0x2 0x0 0x3 0x1 0x2 0x7 0x2 0x1 0x4 0x5 0x5040102 0x90402 0x74030303 0x70000f03 0x1f0000>;
			nvidia,emc-burst-up-down-regs = <0x1 0x14 0xff00ff 0xff00ff 0xff00ff 0xff00ff 0xff00ff 0xff00ff 0xff00ff 0xff0049 0xff0080 0xff0004 0xff0004 0x800ff 0xff 0xff0004 0xff00ff 0xff00ff 0xff0024 0xff00ff 0xff 0xff 0xff00ff 0xff 0xff00ff 0xff00ff 0xff00ff 0xff00ff 0xff00ff 0xff00ff 0xff00ff>;
			nvidia,emc-zcal-cnt-long = <0x15>;
			nvidia,emc-acal-interval = <0x1fffff>;
			nvidia,emc-ctt-term_ctrl = <0x802>;
			nvidia,emc-cfg = <0xf3200000>;
			nvidia,emc-cfg-2 = <0x8c7>;
			nvidia,emc-sel-dpd-ctrl = <0x4013c>;
			nvidia,emc-cfg-dig-dll = <0x580068>;
			nvidia,emc-bgbias-ctl0 = <0x8>;
			nvidia,emc-auto-cal-config2 = <0x0>;
			nvidia,emc-auto-cal-config3 = <0x0>;
			nvidia,emc-auto-cal-config = <0xa1430000>;
			nvidia,emc-mode-0 = <0x0>;
			nvidia,emc-mode-1 = <0x10083>;
			nvidia,emc-mode-2 = <0x20004>;
			nvidia,emc-mode-4 = <0x800b0000>;
			nvidia,emc-clock-latency-change = <0x5172>;
		};

		emc-table@68000 {
			compatible = "nvidia,tegra12-emc-table";
			nvidia,revision = <0x19>;
			nvidia,dvfs-version = "3_68000_02_V5.0.14_V1.1";
			clock-frequency = <0x109a0>;
			nvidia,emc-min-mv = <0x320>;
			nvidia,gk20a-min-mv = <0x320>;
			nvidia,source = "pllp_out0";
			nvidia,src-sel-reg = <0x4000000a>;
			nvidia,burst-regs-num = <0xa5>;
			nvidia,burst-up-down-regs-num = <0x1f>;
			nvidia,emc-registers = <0x4 0xe 0x0 0x2 0x2 0x6 0x8 0x3 0xa 0x2 0x2 0x1 0x2 0x0 0x3 0x3 0x6 0x2 0x0 0x5 0x5 0x10000 0x3 0x0 0x0 0x0 0x0 0x4 0xc 0xd 0xf 0x101 0x0 0x40 0x2 0x2 0x2 0x0 0x1 0xc 0xf 0xf 0x3 0x3 0x3 0x6 0x4 0x3 0x3 0x1c9 0x0 0x0 0x0 0x1363a296 0x5800a0 0x8000 0x48000 0x48000 0x48000 0x48000 0x48000 0x48000 0x48000 0x48000 0x48000 0x48000 0x48000 0x48000 0x48000 0x48000 0x48000 0x48000 0x0 0x0 0x0 0x0 0x0 0x0 0x0 0x0 0xfc000 0xfc000 0x0 0xfc000 0xfc000 0x0 0x0 0x0 0x0 0x0 0x0 0x0 0x0 0x0 0x0 0x0 0x0 0x0 0x0 0x0 0x0 0x0 0x0 0x0 0x0 0x0 0x0 0x0 0x0 0x0 0xfc000 0xfc000 0xfc000 0xfc000 0xfc00 0xfc00 0xfc00 0xfc00 0x200 0x0 0x100100 0x130b018 0x0 0x0 0x77ffc000 0x303 0x81f1f008 0x7070000 0x3f 0x15ddddd 0x51451400 0x514514 0x514514 0x51451400 0x3f 0x0 0x0 0x64000 0x19 0x440011 0x440011 0x0 0x3 0xf3f3 0x80000309 0xa 0x1 0x8000001e 0x1 0x1 0x2 0x0 0x3 0x1 0x2 0x7 0x2 0x1 0x4 0x5 0x5040102 0x90402 0x73830403 0x70000f03 0x1f0000>;
			nvidia,emc-burst-up-down-regs = <0x1 0x21 0xff00ff 0xff00ff 0xff00b0 0xff00ff 0xff00ec 0xff00ff 0xff00ec 0xe90049 0xff0080 0xff0004 0xff0004 0x800ff 0xff 0xff0004 0xff00ff 0xff00a3 0xff0024 0xff00ff 0xff 0xef 0xff00ff 0xef 0xff00ff 0xff00ff 0xee00ef 0xff00ff 0xff00ff 0xff00ff 0xff00ff>;
			nvidia,emc-zcal-cnt-long = <0x15>;
			nvidia,emc-acal-interval = <0x1fffff>;
			nvidia,emc-ctt-term_ctrl = <0x802>;
			nvidia,emc-cfg = <0xf3200000>;
			nvidia,emc-cfg-2 = <0x8c7>;
			nvidia,emc-sel-dpd-ctrl = <0x4013c>;
			nvidia,emc-cfg-dig-dll = <0x580068>;
			nvidia,emc-bgbias-ctl0 = <0x8>;
			nvidia,emc-auto-cal-config2 = <0x0>;
			nvidia,emc-auto-cal-config3 = <0x0>;
			nvidia,emc-auto-cal-config = <0xa1430000>;
			nvidia,emc-mode-0 = <0x0>;
			nvidia,emc-mode-1 = <0x10083>;
			nvidia,emc-mode-2 = <0x20004>;
			nvidia,emc-mode-4 = <0x800b0000>;
			nvidia,emc-clock-latency-change = <0x29e0>;
		};

		emc-table@102000 {
			compatible = "nvidia,tegra12-emc-table";
			nvidia,revision = <0x19>;
			nvidia,dvfs-version = "3_102000_02_V5.0.14_V1.1";
			clock-frequency = <0x18e70>;
			nvidia,emc-min-mv = <0x320>;
			nvidia,gk20a-min-mv = <0x320>;
			nvidia,source = "pllp_out0";
			nvidia,src-sel-reg = <0x40000006>;
			nvidia,burst-regs-num = <0xa5>;
			nvidia,burst-up-down-regs-num = <0x1f>;
			nvidia,emc-registers = <0x6 0x15 0x0 0x4 0x2 0x6 0x8 0x3 0xa 0x2 0x2 0x1 0x2 0x0 0x3 0x3 0x6 0x2 0x0 0x5 0x5 0x10000 0x3 0x0 0x0 0x0 0x0 0x4 0xc 0xd 0xf 0x182 0x0 0x60 0x2 0x2 0x2 0x0 0x1 0xc 0x17 0x17 0x3 0x3 0x3 0x6 0x4 0x3 0x3 0x2ae 0x0 0x0 0x0 0x1363a296 0x5800a0 0x8000 0x48000 0x48000 0x48000 0x48000 0x48000 0x48000 0x48000 0x48000 0x48000 0x48000 0x48000 0x48000 0x48000 0x48000 0x48000 0x48000 0x0 0x0 0x0 0x0 0x0 0x0 0x0 0x0 0xfc000 0xfc000 0x0 0xfc000 0xfc000 0x0 0x0 0x0 0x0 0x0 0x0 0x0 0x0 0x0 0x0 0x0 0x0 0x0 0x0 0x0 0x0 0x0 0x0 0x0 0x0 0x0 0x0 0x0 0x0 0x0 0xfc000 0xfc000 0xfc000 0xfc000 0xfc00 0xfc00 0xfc00 0xfc00 0x200 0x0 0x100100 0x130b018 0x0 0x0 0x77ffc000 0x303 0x81f1f008 0x7070000 0x3f 0x15ddddd 0x51451400 0x514514 0x514514 0x51451400 0x3f 0x0 0x0 0x64000 0x25 0x660011 0x660011 0x0 0x3 0xf3f3 0x8000040b 0xa 0x8000001 0x80000026 0x1 0x1 0x3 0x1 0x3 0x1 0x2 0x7 0x2 0x1 0x4 0x5 0x5040102 0x90403 0x73430504 0x70000f03 0x1f0000>;
			nvidia,emc-burst-up-down-regs = <0x1 0x31 0xff00da 0xff00da 0xff0075 0xff00ff 0xff009d 0xff00ff 0xff009d 0x9b0049 0xff0080 0xff0004 0xff0004 0x800ad 0xff 0xff0004 0xff00c6 0xff006d 0xff0024 0xff00d6 0xff 0x9f 0xff00ff 0x9f 0xff00ff 0xff00ff 0x9f00a0 0xff00ff 0xff00ff 0xff00ff 0xff00da>;
			nvidia,emc-zcal-cnt-long = <0x15>;
			nvidia,emc-acal-interval = <0x1fffff>;
			nvidia,emc-ctt-term_ctrl = <0x802>;
			nvidia,emc-cfg = <0xf3200000>;
			nvidia,emc-cfg-2 = <0x8c7>;
			nvidia,emc-sel-dpd-ctrl = <0x4013c>;
			nvidia,emc-cfg-dig-dll = <0x580068>;
			nvidia,emc-bgbias-ctl0 = <0x8>;
			nvidia,emc-auto-cal-config2 = <0x0>;
			nvidia,emc-auto-cal-config3 = <0x0>;
			nvidia,emc-auto-cal-config = <0xa1430000>;
			nvidia,emc-mode-0 = <0x0>;
			nvidia,emc-mode-1 = <0x10083>;
			nvidia,emc-mode-2 = <0x20004>;
			nvidia,emc-mode-4 = <0x800b0000>;
			nvidia,emc-clock-latency-change = <0x1aea>;
		};

		emc-table@204000 {
			compatible = "nvidia,tegra12-emc-table";
			nvidia,revision = <0x19>;
			nvidia,dvfs-version = "3_204000_02_V5.0.14_V1.1";
			clock-frequency = <0x31ce0>;
			nvidia,emc-min-mv = <0x320>;
			nvidia,gk20a-min-mv = <0x320>;
			nvidia,source = "pllp_out0";
			nvidia,src-sel-reg = <0x40000002>;
			nvidia,burst-regs-num = <0xa5>;
			nvidia,burst-up-down-regs-num = <0x1f>;
			nvidia,emc-registers = <0xc 0x2a 0x0 0x8 0x3 0x7 0x8 0x3 0xa 0x3 0x3 0x2 0x3 0x0 0x2 0x2 0x5 0x3 0x0 0x3 0x7 0x10000 0x4 0x0 0x0 0x0 0x0 0x2 0xe 0xf 0x11 0x304 0x0 0xc1 0x2 0x2 0x3 0x0 0x1 0xc 0x2d 0x2d 0x3 0x4 0x3 0x9 0x5 0x3 0x3 0x55b 0x0 0x0 0x0 0x1363a296 0x5800a0 0x8000 0x80000 0x80000 0x80000 0x80000 0x80000 0x80000 0x80000 0x80000 0x80000 0x80000 0x80000 0x80000 0x80000 0x80000 0x80000 0x80000 0x0 0x0 0x0 0x0 0x0 0x0 0x0 0x0 0xa8000 0xa8000 0x0 0xa8000 0xa8000 0x0 0x0 0x0 0x0 0x0 0x0 0x0 0x0 0x0 0x0 0x0 0x0 0x0 0x0 0x0 0x0 0x0 0x0 0x0 0x0 0x0 0x0 0x0 0x0 0x0 0x88000 0x88000 0x88000 0x88000 0x8c00 0x8800 0x8c00 0x8800 0x200 0x0 0x100100 0x130b018 0x0 0x0 0x77ffc000 0x303 0x81f1f008 0x7070000 0x3f 0x15ddddd 0x51451400 0x514514 0x514514 0x51451400 0x3f 0x0 0x0 0x64000 0x4a 0xcc0011 0xcc0011 0x0 0x4 0xd3b3 0x80000713 0xa 0x1000003 0x80000040 0x1 0x1 0x6 0x3 0x5 0x1 0x2 0x7 0x3 0x1 0x5 0x5 0x5050103 0xa0506 0x72e40a07 0x70000f03 0x1f0000>;
			nvidia,emc-burst-up-down-regs = <0x1 0x62 0xff006d 0xff006d 0xff003c 0xff00af 0xff004f 0xff00af 0xff004f 0x4e0049 0xff0080 0xff0004 0xff0004 0x80057 0xff 0xff0004 0xff0063 0xff0036 0xff0024 0xff006b 0xff 0x50 0xff00ff 0x50 0xff00ff 0xd400ff 0x510050 0xff00ff 0xff00ff 0xff00c6 0xff006d>;
			nvidia,emc-zcal-cnt-long = <0x17>;
			nvidia,emc-acal-interval = <0x1fffff>;
			nvidia,emc-ctt-term_ctrl = <0x802>;
			nvidia,emc-cfg = <0xf3200000>;
			nvidia,emc-cfg-2 = <0x8cf>;
			nvidia,emc-sel-dpd-ctrl = <0x4013c>;
			nvidia,emc-cfg-dig-dll = <0x580068>;
			nvidia,emc-bgbias-ctl0 = <0x8>;
			nvidia,emc-auto-cal-config2 = <0x0>;
			nvidia,emc-auto-cal-config3 = <0x0>;
			nvidia,emc-auto-cal-config = <0xa1430000>;
			nvidia,emc-mode-0 = <0x0>;
			nvidia,emc-mode-1 = <0x10083>;
			nvidia,emc-mode-2 = <0x20004>;
			nvidia,emc-mode-4 = <0x800b0000>;
			nvidia,emc-clock-latency-change = <0xd5c>;
		};

		emc-table@300000 {
			compatible = "nvidia,tegra12-emc-table";
			nvidia,revision = <0x19>;
			nvidia,dvfs-version = "3_300000_03_V5.0.14_V1.1";
			clock-frequency = <0x493e0>;
			nvidia,emc-min-mv = <0x334>;
			nvidia,gk20a-min-mv = <0x334>;
			nvidia,source = "pllc_out0";
			nvidia,src-sel-reg = <0x20000002>;
			nvidia,burst-regs-num = <0xa5>;
			nvidia,burst-up-down-regs-num = <0x1f>;
			nvidia,emc-registers = <0x11 0x3e 0x0 0xc 0x5 0x7 0x8 0x3 0xa 0x5 0x5 0x2 0x3 0x0 0x2 0x2 0x6 0x3 0x0 0x3 0x8 0x30000 0x4 0x0 0x0 0x0 0x0 0x2 0xf 0x12 0x14 0x46e 0x0 0x11b 0x2 0x2 0x5 0x0 0x1 0xc 0x42 0x42 0x3 0x5 0x3 0xd 0x7 0x3 0x3 0x7e0 0x0 0x0 0x0 0x1363a096 0x5800a0 0x8000 0x20000 0x20000 0x20000 0x20000 0x20000 0x20000 0x20000 0x20000 0x20000 0x20000 0x20000 0x20000 0x20000 0x20000 0x20000 0x20000 0x0 0x0 0x0 0x0 0x0 0x0 0x0 0x0 0x58000 0x58000 0x0 0x58000 0x58000 0x0 0x0 0x0 0x0 0x0 0x0 0x0 0x0 0x0 0x0 0x0 0x0 0x0 0x0 0x0 0x0 0x0 0x0 0x0 0x0 0x0 0x0 0x0 0x0 0x0 0x58000 0x58000 0x58000 0x58000 0x5c00 0x5800 0x5c00 0x5800 0x200 0x0 0x100100 0x1231239 0x0 0x0 0x77ffc000 0x303 0x81f1f008 0x7070000 0x3f 0x15ddddd 0x51451420 0x514514 0x514514 0x51451400 0x3f 0x0 0x0 0x64000 0x6c 0x12c0011 0x12c0011 0x0 0x4 0x52a3 0x800009ed 0xb 0x8000004 0x80000040 0x1 0x2 0x9 0x5 0x7 0x1 0x2 0x7 0x3 0x1 0x5 0x5 0x5050103 0xc0709 0x72c50e0a 0x70000f03 0x1f0000>;
			nvidia,emc-burst-up-down-regs = <0x4 0x90 0xff004a 0xff004a 0xff003c 0xff0090 0xff0041 0xff0090 0xff0041 0x350049 0xff0080 0xff0004 0xff0004 0x8003b 0xff 0xff0004 0xff0043 0xff002d 0xff0024 0xff0049 0xff 0x36 0xff00ff 0x36 0xff00ff 0xd400ff 0x510036 0xff00ff 0xff00ff 0xff0087 0xff004a>;
			nvidia,emc-zcal-cnt-long = <0x1f>;
			nvidia,emc-acal-interval = <0x1fffff>;
			nvidia,emc-ctt-term_ctrl = <0x802>;
			nvidia,emc-cfg = <0xf3300000>;
			nvidia,emc-cfg-2 = <0x8d7>;
			nvidia,emc-sel-dpd-ctrl = <0x4013c>;
			nvidia,emc-cfg-dig-dll = <0x580068>;
			nvidia,emc-bgbias-ctl0 = <0x0>;
			nvidia,emc-auto-cal-config2 = <0x0>;
			nvidia,emc-auto-cal-config3 = <0x0>;
			nvidia,emc-auto-cal-config = <0xa1430000>;
			nvidia,emc-mode-0 = <0x0>;
			nvidia,emc-mode-1 = <0x10083>;
			nvidia,emc-mode-2 = <0x20004>;
			nvidia,emc-mode-4 = <0x800b0000>;
			nvidia,emc-clock-latency-change = <0xa78>;
		};

		emc-table@396000 {
			compatible = "nvidia,tegra12-emc-table";
			nvidia,revision = <0x19>;
			nvidia,dvfs-version = "3_396000_03_V5.0.14_V1.1";
			clock-frequency = <0x60ae0>;
			nvidia,emc-min-mv = <0x352>;
			nvidia,gk20a-min-mv = <0x352>;
			nvidia,source = "pllm_out0";
			nvidia,src-sel-reg = <0x2>;
			nvidia,burst-regs-num = <0xa5>;
			nvidia,burst-up-down-regs-num = <0x1f>;
			nvidia,emc-registers = <0x17 0x53 0x0 0x10 0x7 0x8 0x8 0x3 0xa 0x7 0x7 0x3 0x3 0x0 0x2 0x2 0x6 0x3 0x0 0x2 0x9 0x30000 0x4 0x0 0x0 0x0 0x0 0x1 0x10 0x12 0x14 0x5d9 0x0 0x176 0x2 0x2 0x7 0x0 0x1 0xe 0x58 0x58 0x3 0x6 0x3 0x12 0x9 0x3 0x3 0xa66 0x0 0x0 0x0 0x1363a096 0x5800a0 0x8000 0x20000 0x20000 0x20000 0x20000 0x20000 0x20000 0x20000 0x20000 0x20000 0x20000 0x20000 0x20000 0x20000 0x20000 0x20000 0x20000 0x0 0x0 0x0 0x0 0x0 0x0 0x0 0x0 0x48000 0x48000 0x0 0x48000 0x48000 0x0 0x0 0x0 0x0 0x0 0x0 0x0 0x0 0x0 0x0 0x0 0x0 0x0 0x0 0x0 0x0 0x0 0x0 0x0 0x0 0x0 0x0 0x0 0x0 0x0 0x40000 0x40000 0x40000 0x40000 0x4000 0x4000 0x4000 0x4000 0x200 0x0 0x100100 0x1231239 0x0 0x0 0x77ffc000 0x303 0x81f1f008 0x7070000 0x3f 0x15ddddd 0x51451420 0x514514 0x514514 0x51451400 0x3f 0x0 0x0 0x64000 0x8f 0x18c0011 0x18c0011 0x0 0x4 0x52a3 0x80000cc7 0xb 0xf000005 0x80000040 0x2 0x3 0xc 0x7 0x9 0x1 0x2 0x7 0x3 0x1 0x5 0x5 0x5050103 0xe090c 0x72c6120d 0x70000f03 0x1f0000>;
			nvidia,emc-burst-up-down-regs = <0xa 0xbe 0xff0038 0xff0038 0xff003c 0xff0090 0xff0041 0xff0090 0xff0041 0x280049 0xff0080 0xff0004 0xff0004 0x8002d 0xff 0xff0004 0xff0033 0xff0022 0xff0024 0xff0037 0xff 0x36 0xff00ff 0x36 0xff00ff 0xd400ff 0x510029 0xff00ff 0xff00ff 0xff0066 0xff0038>;
			nvidia,emc-zcal-cnt-long = <0x28>;
			nvidia,emc-acal-interval = <0x1fffff>;
			nvidia,emc-ctt-term_ctrl = <0x802>;
			nvidia,emc-cfg = <0xf3300000>;
			nvidia,emc-cfg-2 = <0x897>;
			nvidia,emc-sel-dpd-ctrl = <0x4001c>;
			nvidia,emc-cfg-dig-dll = <0x580068>;
			nvidia,emc-bgbias-ctl0 = <0x0>;
			nvidia,emc-auto-cal-config2 = <0x0>;
			nvidia,emc-auto-cal-config3 = <0x0>;
			nvidia,emc-auto-cal-config = <0xa1430000>;
			nvidia,emc-mode-0 = <0x0>;
			nvidia,emc-mode-1 = <0x10083>;
			nvidia,emc-mode-2 = <0x20004>;
			nvidia,emc-mode-4 = <0x800b0000>;
			nvidia,emc-clock-latency-change = <0x884>;
		};

		emc-table@528000 {
			compatible = "nvidia,tegra12-emc-table";
			nvidia,revision = <0x19>;
			nvidia,dvfs-version = "3_528000_03_V5.0.14_V1.1";
			clock-frequency = <0x80e80>;
			nvidia,emc-min-mv = <0x370>;
			nvidia,gk20a-min-mv = <0x366>;
			nvidia,source = "pllm_ud";
			nvidia,src-sel-reg = <0x80000000>;
			nvidia,burst-regs-num = <0xa5>;
			nvidia,burst-up-down-regs-num = <0x1f>;
			nvidia,emc-registers = <0x1f 0x6e 0x0 0x16 0x9 0x9 0x9 0x3 0xd 0x9 0x9 0x5 0x4 0x0 0x2 0x2 0x7 0x4 0x0 0x2 0xb 0x40000 0x5 0x0 0x0 0x0 0x0 0x1 0x12 0x15 0x17 0x7cd 0x0 0x1f3 0x3 0x3 0x9 0x0 0x1 0x11 0x75 0x75 0x4 0x8 0x4 0x19 0xc 0x3 0x3 0xddd 0x0 0x0 0x0 0x1363a096 0xe01200b9 0x8000 0xa 0xa 0xa 0xa 0xa 0xa 0xa 0xa 0xa 0xa 0xa 0xa 0xa 0xa 0xa 0xa 0x0 0x0 0x0 0x0 0x0 0x0 0x0 0x0 0x400e 0x400e 0x0 0x4010 0x4010 0x0 0x0 0x0 0x0 0x0 0x0 0x0 0x0 0x0 0x1 0x1 0x0 0x0 0x0 0x0 0x1 0x0 0x1 0x1 0x0 0x0 0x0 0x0 0x1 0x0 0xc 0xc 0xc 0xc 0xd 0xc 0xd 0xc 0x220 0x0 0x100100 0x123123d 0x0 0x0 0x77ffc004 0x303 0x81f1f008 0x7070000 0x3f 0x15ddddd 0x51451420 0x514514 0x514514 0x51451400 0x3f 0x0 0x0 0x64000 0xbf 0x2100013 0x2100013 0x0 0x5 0x42a0 0x800010b3 0xd 0xf000007 0x80000040 0x3 0x4 0x10 0xa 0xd 0x2 0x2 0x9 0x3 0x1 0x6 0x6 0x6060103 0x120b10 0x72c81811 0x70000f03 0x1f0000>;
			nvidia,emc-burst-up-down-regs = <0xd 0xfd 0xc10038 0xc10038 0xc1003c 0xc10090 0xc10041 0xc10090 0xc10041 0x270049 0xc10080 0xc10004 0xc10004 0x80021 0xc1 0xc10004 0xc10026 0xc1001a 0xc10024 0xc10029 0xc1 0x36 0xc100c1 0x36 0xc100c1 0xd400ff 0x510029 0xc100c1 0xc100c1 0xc10065 0xc1002a>;
			nvidia,emc-zcal-cnt-long = <0x34>;
			nvidia,emc-acal-interval = <0x1fffff>;
			nvidia,emc-ctt-term_ctrl = <0x802>;
			nvidia,emc-cfg = <0xf3300000>;
			nvidia,emc-cfg-2 = <0x89f>;
			nvidia,emc-sel-dpd-ctrl = <0x4001c>;
			nvidia,emc-cfg-dig-dll = <0xe0120069>;
			nvidia,emc-bgbias-ctl0 = <0x0>;
			nvidia,emc-auto-cal-config2 = <0x0>;
			nvidia,emc-auto-cal-config3 = <0x0>;
			nvidia,emc-auto-cal-config = <0xa1430000>;
			nvidia,emc-mode-0 = <0x0>;
			nvidia,emc-mode-1 = <0x100c3>;
			nvidia,emc-mode-2 = <0x20006>;
			nvidia,emc-mode-4 = <0x800b0000>;
			nvidia,emc-clock-latency-change = <0x5a0>;
		};

		emc-table@600000 {
			compatible = "nvidia,tegra12-emc-table";
			nvidia,revision = <0x19>;
			nvidia,dvfs-version = "3_600000_02_V5.0.14_V1.1";
			clock-frequency = <0x927c0>;
			nvidia,emc-min-mv = <0x38e>;
			nvidia,gk20a-min-mv = <0x38e>;
			nvidia,source = "pllc_ud";
			nvidia,src-sel-reg = <0xe0000000>;
			nvidia,burst-regs-num = <0xa5>;
			nvidia,burst-up-down-regs-num = <0x1f>;
			nvidia,emc-registers = <0x23 0x7d 0x0 0x19 0xa 0xa 0xb 0x4 0xf 0xa 0xa 0x5 0x4 0x0 0x4 0x4 0xa 0x4 0x0 0x3 0xd 0x70000 0x5 0x0 0x0 0x0 0x0 0x2 0x14 0x18 0x1a 0x8e4 0x0 0x239 0x4 0x4 0xa 0x0 0x1 0x13 0x84 0x84 0x5 0x9 0x5 0x1c 0xd 0x3 0x3 0xfc0 0x0 0x0 0x0 0x1363a096 0xe00e00b9 0x8000 0xa 0xa 0xa 0xa 0xa 0xa 0xa 0xa 0xa 0xa 0xa 0xa 0xa 0xa 0xa 0xa 0x0 0x0 0x0 0x0 0x0 0x0 0x0 0x0 0xe 0xe 0x0 0x10 0x10 0x0 0x0 0x0 0x0 0x0 0x0 0x0 0x0 0x0 0x3 0x3 0x2 0x2 0x2 0x1 0x3 0x1 0x3 0x3 0x2 0x2 0x2 0x1 0x3 0x1 0xb 0xb 0xb 0xb 0xc 0xb 0xc 0xb 0x220 0x0 0x100100 0x121103d 0x0 0x0 0x77ffc004 0x303 0x81f1f008 0x7070000 0x3f 0x15ddddd 0x51451420 0x514514 0x514514 0x51451400 0x3f 0x0 0x0 0x64000 0xd8 0x2580014 0x2580014 0x0 0x5 0x40a0 0x800012d6 0x10 0x9 0x80000040 0x4 0x5 0x12 0xb 0xe 0x2 0x3 0xa 0x3 0x1 0x6 0x7 0x7060103 0x140d12 0x72c91b13 0x70000f03 0x1f0000>;
			nvidia,emc-burst-up-down-regs = <0xf 0x120 0xaa0038 0xaa0038 0xaa003c 0xaa0090 0xaa0041 0xaa0090 0xaa0041 0x270049 0xaa0080 0xaa0004 0xaa0004 0x8001d 0xaa 0xaa0004 0xaa0022 0xaa0018 0xaa0024 0xaa0024 0xaa 0x36 0xaa00aa 0x36 0xaa00aa 0xd400ff 0x510029 0xaa00aa 0xaa00aa 0xaa0065 0xaa0025>;
			nvidia,emc-zcal-cnt-long = <0x3a>;
			nvidia,emc-acal-interval = <0x1fffff>;
			nvidia,emc-ctt-term_ctrl = <0x802>;
			nvidia,emc-cfg = <0xf3300000>;
			nvidia,emc-cfg-2 = <0x89f>;
			nvidia,emc-sel-dpd-ctrl = <0x4001c>;
			nvidia,emc-cfg-dig-dll = <0xe00e0069>;
			nvidia,emc-bgbias-ctl0 = <0x0>;
			nvidia,emc-auto-cal-config2 = <0x0>;
			nvidia,emc-auto-cal-config3 = <0x0>;
			nvidia,emc-auto-cal-config = <0xa1430000>;
			nvidia,emc-mode-0 = <0x0>;
			nvidia,emc-mode-1 = <0x100e3>;
			nvidia,emc-mode-2 = <0x20007>;
			nvidia,emc-mode-4 = <0x800b0000>;
			nvidia,emc-clock-latency-change = <0x5a0>;
		};

		emc-table@792000 {
			compatible = "nvidia,tegra12-emc-table";
			nvidia,revision = <0x19>;
			nvidia,dvfs-version = "3_792000_01_V5.0.14_V1.1";
			clock-frequency = <0xc15c0>;
			nvidia,emc-min-mv = <0x3d4>;
			nvidia,gk20a-min-mv = <0x3d4>;
			nvidia,source = "pllm_ud";
			nvidia,src-sel-reg = <0x80000000>;
			nvidia,burst-regs-num = <0xa5>;
			nvidia,burst-up-down-regs-num = <0x1f>;
			nvidia,emc-registers = <0x2f 0xa6 0x0 0x21 0xe 0xd 0xd 0x5 0x13 0xe 0xe 0x7 0x5 0x0 0x5 0x5 0xd 0x5 0x0 0x4 0x10 0xa0000 0x7 0x0 0x0 0x0 0x0 0x3 0x17 0x1d 0x1f 0xbd1 0x0 0x2f4 0x5 0x5 0xe 0x0 0x1 0x17 0xaf 0xaf 0x6 0xc 0x6 0x26 0x11 0x3 0x3 0x14cb 0x0 0x0 0x0 0x1363a096 0xe00700b9 0x8000 0xa 0xa 0xa 0xa 0xa 0xa 0xa 0xa 0xa 0xa 0xa 0xa 0xa 0xa 0xa 0xa 0x0 0x0 0x0 0x0 0x0 0x0 0x0 0x0 0x400d 0x400d 0x0 0x4010 0x4010 0x0 0x0 0x0 0x0 0x0 0x0 0x0 0x0 0x0 0x7 0x7 0x6 0x6 0x6 0x5 0x6 0x5 0x7 0x7 0x6 0x6 0x6 0x5 0x6 0x5 0xa 0xa 0xa 0xa 0xb 0xa 0xb 0xa 0x220 0x0 0x100100 0x120103d 0x0 0x0 0x77ffc004 0x303 0x81f1f008 0x7070000 0x0 0x15ddddd 0x61861820 0x514514 0x514514 0x61861800 0x3f 0x0 0x0 0x64000 0x11e 0x3180017 0x3180017 0x0 0x7 0x4080 0x8000188b 0x14 0xe00000b 0x80000040 0x6 0x7 0x18 0xf 0x13 0x3 0x3 0xc 0x4 0x1 0x8 0x8 0x8080104 0x1a1118 0x72ac2419 0x70000f02 0x1f0000>;
			nvidia,emc-burst-up-down-regs = <0x13 0x17c 0x810038 0x810038 0x81003c 0x810090 0x810041 0x810090 0x810041 0x270049 0x810080 0x810004 0x810004 0x80016 0x81 0x810004 0x810019 0x810018 0x810024 0x81001c 0x81 0x36 0x810081 0x36 0x810081 0xd400ff 0x510029 0x810081 0x810081 0x810065 0x81001c>;
			nvidia,emc-zcal-cnt-long = <0x4c>;
			nvidia,emc-acal-interval = <0x1fffff>;
			nvidia,emc-ctt-term_ctrl = <0x802>;
			nvidia,emc-cfg = <0xf3300000>;
			nvidia,emc-cfg-2 = <0x89f>;
			nvidia,emc-sel-dpd-ctrl = <0x4001c>;
			nvidia,emc-cfg-dig-dll = <0xe0070069>;
			nvidia,emc-bgbias-ctl0 = <0x0>;
			nvidia,emc-auto-cal-config2 = <0x0>;
			nvidia,emc-auto-cal-config3 = <0x0>;
			nvidia,emc-auto-cal-config = <0xa1430000>;
			nvidia,emc-mode-0 = <0x0>;
			nvidia,emc-mode-1 = <0x10043>;
			nvidia,emc-mode-2 = <0x2001a>;
			nvidia,emc-mode-4 = <0x800b0000>;
			nvidia,emc-clock-latency-change = <0x4b0>;
		};

		emc-table@924000 {
			compatible = "nvidia,tegra12-emc-table";
			nvidia,revision = <0x19>;
			nvidia,dvfs-version = "3_924000_01_V5.0.14_V1.1";
			clock-frequency = <0xe1960>;
			nvidia,emc-min-mv = <0x3f2>;
			nvidia,gk20a-min-mv = <0x3f2>;
			nvidia,source = "pllm_ud";
			nvidia,src-sel-reg = <0x80000000>;
			nvidia,burst-regs-num = <0xa5>;
			nvidia,burst-up-down-regs-num = <0x1f>;
			nvidia,emc-registers = <0x37 0xc2 0x0 0x26 0x10 0xf 0x10 0x6 0x17 0x10 0x10 0x9 0x5 0x0 0x7 0x7 0x10 0x5 0x0 0x5 0x12 0xd0000 0x7 0x0 0x0 0x0 0x0 0x4 0x19 0x20 0x22 0xdd4 0x0 0x375 0x6 0x6 0x10 0x0 0x1 0x1b 0xcc 0xcc 0x7 0xe 0x7 0x2d 0x14 0x3 0x3 0x1842 0x0 0x0 0x0 0x1363a896 0xe00400b9 0x8000 0x4 0x4 0x4 0x4 0x4 0x4 0x4 0x4 0x4 0x4 0x4 0x4 0x4 0x4 0x4 0x4 0x0 0x0 0x0 0x0 0x0 0x0 0x0 0x0 0x400d 0x400d 0x0 0x11 0x11 0x0 0x0 0x0 0x0 0x0 0x0 0x0 0x0 0x0 0x4 0x4 0x4 0x4 0x4 0x4 0x4 0x4 0x4 0x4 0x4 0x4 0x4 0x4 0x4 0x4 0x9 0x9 0x9 0x9 0xa 0x9 0xa 0x9 0x220 0x0 0x100100 0x120103d 0x0 0x0 0x77ffc004 0x303 0x81f1f008 0x7070000 0x0 0x15ddddd 0x5d75d720 0x514514 0x514514 0x5d75d700 0x3f 0x0 0x0 0x64000 0x14d 0x39c0019 0x39c0019 0x0 0x7 0x4080 0x80001c77 0x17 0xe00000d 0x80000040 0x7 0x8 0x1b 0x12 0x17 0x4 0x4 0xe 0x4 0x1 0x9 0x9 0x9090104 0x1e141b 0x72ae2a1c 0x70000f02 0x1f0000>;
			nvidia,emc-burst-up-down-regs = <0x17 0x1bb 0x6e0038 0x6e0038 0x6e003c 0x6e0090 0x6e0041 0x6e0090 0x6e0041 0x270049 0x6e0080 0x6e0004 0x6e0004 0x80016 0x6e 0x6e0004 0x6e0019 0x6e0018 0x6e0024 0x6e001b 0x6e 0x36 0x6e006e 0x36 0x6e006e 0xd400ff 0x510029 0x6e006e 0x6e006e 0x6e0065 0x6e001c>;
			nvidia,emc-zcal-cnt-long = <0x58>;
			nvidia,emc-acal-interval = <0x1fffff>;
			nvidia,emc-ctt-term_ctrl = <0x802>;
			nvidia,emc-cfg = <0xf3300000>;
			nvidia,emc-cfg-2 = <0x89f>;
			nvidia,emc-sel-dpd-ctrl = <0x4001c>;
			nvidia,emc-cfg-dig-dll = <0xe0040069>;
			nvidia,emc-bgbias-ctl0 = <0x0>;
			nvidia,emc-auto-cal-config2 = <0x0>;
			nvidia,emc-auto-cal-config3 = <0x0>;
			nvidia,emc-auto-cal-config = <0xa1430000>;
			nvidia,emc-mode-0 = <0x0>;
			nvidia,emc-mode-1 = <0x10083>;
			nvidia,emc-mode-2 = <0x2001c>;
			nvidia,emc-mode-4 = <0x800b0000>;
			nvidia,emc-clock-latency-change = <0x49c>;
		};

		emc-table-derated@12750 {
			compatible = "nvidia,tegra12-emc-table-derated";
			nvidia,revision = <0x19>;
			nvidia,dvfs-version = "01_12750_01_V5.0.14_V1.1";
			clock-frequency = <0x31ce>;
			nvidia,emc-min-mv = <0x320>;
			nvidia,gk20a-min-mv = <0x320>;
			nvidia,source = "pllp_out0";
			nvidia,src-sel-reg = <0x4000003e>;
			nvidia,burst-regs-num = <0xa5>;
			nvidia,burst-up-down-regs-num = <0x1f>;
			nvidia,emc-registers = <0x0 0x3 0x0 0x2 0x2 0x6 0x8 0x3 0xa 0x2 0x2 0x1 0x2 0x0 0x3 0x3 0x6 0x2 0x0 0x5 0x5 0x10000 0x3 0x0 0x0 0x0 0x0 0x4 0xc 0xd 0xf 0xb 0x0 0x2 0x2 0x2 0x2 0x0 0x1 0xc 0x3 0x3 0x3 0x3 0x3 0x6 0x4 0x3 0x3 0x56 0x0 0x0 0x0 0x1363a296 0x5800a0 0x8000 0x48000 0x48000 0x48000 0x48000 0x48000 0x48000 0x48000 0x48000 0x48000 0x48000 0x48000 0x48000 0x48000 0x48000 0x48000 0x48000 0x0 0x0 0x0 0x0 0x0 0x0 0x0 0x0 0xfc000 0xfc000 0x0 0xfc000 0xfc000 0x0 0x0 0x0 0x0 0x0 0x0 0x0 0x0 0x0 0x0 0x0 0x0 0x0 0x0 0x0 0x0 0x0 0x0 0x0 0x0 0x0 0x0 0x0 0x0 0x0 0xfc000 0xfc000 0xfc000 0xfc000 0xfc00 0xfc00 0xfc00 0xfc00 0x200 0x0 0x100100 0x130b018 0x0 0x0 0x77ffc000 0x303 0x81f1f008 0x7070000 0x3f 0x15ddddd 0x51451400 0x514514 0x514514 0x51451400 0x3f 0x0 0x0 0x64000 0x11 0xd0011 0xd0011 0x0 0x3 0xf3f3 0x8000011c 0xa 0x40040001 0x8000000a 0x1 0x1 0x2 0x0 0x3 0x1 0x2 0x7 0x2 0x1 0x4 0x5 0x5040102 0x90402 0x77c30303 0x70000f03 0x1f0000>;
			nvidia,emc-burst-up-down-regs = <0x1 0x7 0xff00ff 0xff00ff 0xff00ff 0xff00ff 0xff00ff 0xff00ff 0xff00ff 0xff0049 0xff0080 0xff0004 0xff0004 0x800ff 0xff 0xff0004 0xff00ff 0xff00ff 0xff0024 0xff00ff 0xff 0xff 0xff00ff 0xff 0xff00ff 0xff00ff 0xff00ff 0xff00ff 0xff00ff 0xff00ff 0xff00ff>;
			nvidia,emc-zcal-cnt-long = <0x15>;
			nvidia,emc-acal-interval = <0x1fffff>;
			nvidia,emc-ctt-term_ctrl = <0x802>;
			nvidia,emc-cfg = <0xf3200000>;
			nvidia,emc-cfg-2 = <0x8c7>;
			nvidia,emc-sel-dpd-ctrl = <0x4013c>;
			nvidia,emc-cfg-dig-dll = <0x580068>;
			nvidia,emc-bgbias-ctl0 = <0x8>;
			nvidia,emc-auto-cal-config2 = <0x0>;
			nvidia,emc-auto-cal-config3 = <0x0>;
			nvidia,emc-auto-cal-config = <0xa1430000>;
			nvidia,emc-mode-0 = <0x0>;
			nvidia,emc-mode-1 = <0x10083>;
			nvidia,emc-mode-2 = <0x20004>;
			nvidia,emc-mode-4 = <0x800b0000>;
			nvidia,emc-clock-latency-change = <0xe1dc>;
		};

		emc-table-derated@20400 {
			compatible = "nvidia,tegra12-emc-table-derated";
			nvidia,revision = <0x19>;
			nvidia,dvfs-version = "01_20400_01_V5.0.14_V1.1";
			clock-frequency = <0x4fb0>;
			nvidia,emc-min-mv = <0x320>;
			nvidia,gk20a-min-mv = <0x320>;
			nvidia,source = "pllp_out0";
			nvidia,src-sel-reg = <0x40000026>;
			nvidia,burst-regs-num = <0xa5>;
			nvidia,burst-up-down-regs-num = <0x1f>;
			nvidia,emc-registers = <0x1 0x4 0x0 0x2 0x2 0x6 0x8 0x3 0xa 0x2 0x2 0x1 0x2 0x0 0x3 0x3 0x6 0x2 0x0 0x5 0x5 0x10000 0x3 0x0 0x0 0x0 0x0 0x4 0xc 0xd 0xf 0x13 0x0 0x4 0x2 0x2 0x2 0x0 0x1 0xc 0x5 0x5 0x3 0x3 0x3 0x6 0x4 0x3 0x3 0x8a 0x0 0x0 0x0 0x1363a296 0x5800a0 0x8000 0x48000 0x48000 0x48000 0x48000 0x48000 0x48000 0x48000 0x48000 0x48000 0x48000 0x48000 0x48000 0x48000 0x48000 0x48000 0x48000 0x0 0x0 0x0 0x0 0x0 0x0 0x0 0x0 0xfc000 0xfc000 0x0 0xfc000 0xfc000 0x0 0x0 0x0 0x0 0x0 0x0 0x0 0x0 0x0 0x0 0x0 0x0 0x0 0x0 0x0 0x0 0x0 0x0 0x0 0x0 0x0 0x0 0x0 0x0 0x0 0xfc000 0xfc000 0xfc000 0xfc000 0xfc00 0xfc00 0xfc00 0xfc00 0x200 0x0 0x100100 0x130b018 0x0 0x0 0x77ffc000 0x303 0x81f1f008 0x7070000 0x3f 0x15ddddd 0x51451400 0x514514 0x514514 0x51451400 0x3f 0x0 0x0 0x64000 0x11 0x150011 0x150011 0x0 0x3 0xf3f3 0x8000012a 0xa 0x40020001 0x80000012 0x1 0x1 0x2 0x0 0x3 0x1 0x2 0x7 0x2 0x1 0x4 0x5 0x5040102 0x90402 0x75a30303 0x70000f03 0x1f0000>;
			nvidia,emc-burst-up-down-regs = <0x1 0xa 0xff00ff 0xff00ff 0xff00ff 0xff00ff 0xff00ff 0xff00ff 0xff00ff 0xff0049 0xff0080 0xff0004 0xff0004 0x800ff 0xff 0xff0004 0xff00ff 0xff00ff 0xff0024 0xff00ff 0xff 0xff 0xff00ff 0xff 0xff00ff 0xff00ff 0xff00ff 0xff00ff 0xff00ff 0xff00ff 0xff00ff>;
			nvidia,emc-zcal-cnt-long = <0x15>;
			nvidia,emc-acal-interval = <0x1fffff>;
			nvidia,emc-ctt-term_ctrl = <0x802>;
			nvidia,emc-cfg = <0xf3200000>;
			nvidia,emc-cfg-2 = <0x8c7>;
			nvidia,emc-sel-dpd-ctrl = <0x4013c>;
			nvidia,emc-cfg-dig-dll = <0x580068>;
			nvidia,emc-bgbias-ctl0 = <0x8>;
			nvidia,emc-auto-cal-config2 = <0x0>;
			nvidia,emc-auto-cal-config3 = <0x0>;
			nvidia,emc-auto-cal-config = <0xa1430000>;
			nvidia,emc-mode-0 = <0x0>;
			nvidia,emc-mode-1 = <0x10083>;
			nvidia,emc-mode-2 = <0x20004>;
			nvidia,emc-mode-4 = <0x800b0000>;
			nvidia,emc-clock-latency-change = <0x8b1a>;
		};

		emc-table-derated@40800 {
			compatible = "nvidia,tegra12-emc-table-derated";
			nvidia,revision = <0x19>;
			nvidia,dvfs-version = "01_40800_01_V5.0.14_V1.1";
			clock-frequency = <0x9f60>;
			nvidia,emc-min-mv = <0x320>;
			nvidia,gk20a-min-mv = <0x320>;
			nvidia,source = "pllp_out0";
			nvidia,src-sel-reg = <0x40000012>;
			nvidia,burst-regs-num = <0xa5>;
			nvidia,burst-up-down-regs-num = <0x1f>;
			nvidia,emc-registers = <0x2 0x8 0x0 0x2 0x2 0x6 0x8 0x3 0xa 0x2 0x2 0x1 0x2 0x0 0x3 0x3 0x6 0x2 0x0 0x5 0x5 0x10000 0x3 0x0 0x0 0x0 0x0 0x4 0xc 0xd 0xf 0x26 0x0 0x9 0x2 0x2 0x2 0x0 0x1 0xc 0x9 0x9 0x3 0x3 0x3 0x6 0x4 0x3 0x3 0x113 0x0 0x0 0x0 0x1363a296 0x5800a0 0x8000 0x48000 0x48000 0x48000 0x48000 0x48000 0x48000 0x48000 0x48000 0x48000 0x48000 0x48000 0x48000 0x48000 0x48000 0x48000 0x48000 0x0 0x0 0x0 0x0 0x0 0x0 0x0 0x0 0xfc000 0xfc000 0x0 0xfc000 0xfc000 0x0 0x0 0x0 0x0 0x0 0x0 0x0 0x0 0x0 0x0 0x0 0x0 0x0 0x0 0x0 0x0 0x0 0x0 0x0 0x0 0x0 0x0 0x0 0x0 0x0 0xfc000 0xfc000 0xfc000 0xfc000 0xfc00 0xfc00 0xfc00 0xfc00 0x200 0x0 0x100100 0x130b018 0x0 0x0 0x77ffc000 0x303 0x81f1f008 0x7070000 0x3f 0x15ddddd 0x51451400 0x514514 0x514514 0x51451400 0x3f 0x0 0x0 0x64000 0x11 0x290011 0x290011 0x0 0x3 0xf3f3 0x80000151 0xa 0xa0000001 0x80000017 0x1 0x1 0x2 0x0 0x3 0x1 0x2 0x7 0x2 0x1 0x4 0x5 0x5040102 0x90402 0x74030303 0x70000f03 0x1f0000>;
			nvidia,emc-burst-up-down-regs = <0x1 0x14 0xff00ff 0xff00ff 0xff00ff 0xff00ff 0xff00ff 0xff00ff 0xff00ff 0xff0049 0xff0080 0xff0004 0xff0004 0x800ff 0xff 0xff0004 0xff00ff 0xff00ff 0xff0024 0xff00ff 0xff 0xff 0xff00ff 0xff 0xff00ff 0xff00ff 0xff00ff 0xff00ff 0xff00ff 0xff00ff 0xff00ff>;
			nvidia,emc-zcal-cnt-long = <0x15>;
			nvidia,emc-acal-interval = <0x1fffff>;
			nvidia,emc-ctt-term_ctrl = <0x802>;
			nvidia,emc-cfg = <0xf3200000>;
			nvidia,emc-cfg-2 = <0x8c7>;
			nvidia,emc-sel-dpd-ctrl = <0x4013c>;
			nvidia,emc-cfg-dig-dll = <0x580068>;
			nvidia,emc-bgbias-ctl0 = <0x8>;
			nvidia,emc-auto-cal-config2 = <0x0>;
			nvidia,emc-auto-cal-config3 = <0x0>;
			nvidia,emc-auto-cal-config = <0xa1430000>;
			nvidia,emc-mode-0 = <0x0>;
			nvidia,emc-mode-1 = <0x10083>;
			nvidia,emc-mode-2 = <0x20004>;
			nvidia,emc-mode-4 = <0x800b0000>;
			nvidia,emc-clock-latency-change = <0x5172>;
		};

		emc-table-derated@68000 {
			compatible = "nvidia,tegra12-emc-table-derated";
			nvidia,revision = <0x19>;
			nvidia,dvfs-version = "01_68000_01_V5.0.14_V1.1";
			clock-frequency = <0x109a0>;
			nvidia,emc-min-mv = <0x320>;
			nvidia,gk20a-min-mv = <0x320>;
			nvidia,source = "pllp_out0";
			nvidia,src-sel-reg = <0x4000000a>;
			nvidia,burst-regs-num = <0xa5>;
			nvidia,burst-up-down-regs-num = <0x1f>;
			nvidia,emc-registers = <0x4 0xe 0x0 0x2 0x2 0x6 0x8 0x3 0xa 0x2 0x2 0x1 0x2 0x0 0x3 0x3 0x6 0x2 0x0 0x5 0x5 0x10000 0x3 0x0 0x0 0x0 0x0 0x4 0xc 0xd 0xf 0x40 0x0 0x10 0x2 0x2 0x2 0x0 0x1 0xc 0xf 0xf 0x3 0x3 0x3 0x6 0x4 0x3 0x3 0x1c9 0x0 0x0 0x0 0x1363a296 0x5800a0 0x8000 0x48000 0x48000 0x48000 0x48000 0x48000 0x48000 0x48000 0x48000 0x48000 0x48000 0x48000 0x48000 0x48000 0x48000 0x48000 0x48000 0x0 0x0 0x0 0x0 0x0 0x0 0x0 0x0 0xfc000 0xfc000 0x0 0xfc000 0xfc000 0x0 0x0 0x0 0x0 0x0 0x0 0x0 0x0 0x0 0x0 0x0 0x0 0x0 0x0 0x0 0x0 0x0 0x0 0x0 0x0 0x0 0x0 0x0 0x0 0x0 0xfc000 0xfc000 0xfc000 0xfc000 0xfc00 0xfc00 0xfc00 0xfc00 0x200 0x0 0x100100 0x130b018 0x0 0x0 0x77ffc000 0x303 0x81f1f008 0x7070000 0x3f 0x15ddddd 0x51451400 0x514514 0x514514 0x51451400 0x3f 0x0 0x0 0x64000 0x19 0x440011 0x440011 0x0 0x3 0xf3f3 0x80000185 0xa 0x1 0x8000001e 0x1 0x1 0x2 0x0 0x3 0x1 0x2 0x7 0x2 0x1 0x4 0x5 0x5040102 0x90402 0x73830403 0x70000f03 0x1f0000>;
			nvidia,emc-burst-up-down-regs = <0x1 0x21 0xff00ff 0xff00ff 0xff00b0 0xff00ff 0xff00ec 0xff00ff 0xff00ec 0xe90049 0xff0080 0xff0004 0xff0004 0x800ff 0xff 0xff0004 0xff00ff 0xff00a3 0xff0024 0xff00ff 0xff 0xef 0xff00ff 0xef 0xff00ff 0xff00ff 0xee00ef 0xff00ff 0xff00ff 0xff00ff 0xff00ff>;
			nvidia,emc-zcal-cnt-long = <0x15>;
			nvidia,emc-acal-interval = <0x1fffff>;
			nvidia,emc-ctt-term_ctrl = <0x802>;
			nvidia,emc-cfg = <0xf3200000>;
			nvidia,emc-cfg-2 = <0x8c7>;
			nvidia,emc-sel-dpd-ctrl = <0x4013c>;
			nvidia,emc-cfg-dig-dll = <0x580068>;
			nvidia,emc-bgbias-ctl0 = <0x8>;
			nvidia,emc-auto-cal-config2 = <0x0>;
			nvidia,emc-auto-cal-config3 = <0x0>;
			nvidia,emc-auto-cal-config = <0xa1430000>;
			nvidia,emc-mode-0 = <0x0>;
			nvidia,emc-mode-1 = <0x10083>;
			nvidia,emc-mode-2 = <0x20004>;
			nvidia,emc-mode-4 = <0x800b0000>;
			nvidia,emc-clock-latency-change = <0x29e0>;
		};

		emc-table-derated@102000 {
			compatible = "nvidia,tegra12-emc-table-derated";
			nvidia,revision = <0x19>;
			nvidia,dvfs-version = "01_102000_01_V5.0.14_V1.1";
			clock-frequency = <0x18e70>;
			nvidia,emc-min-mv = <0x320>;
			nvidia,gk20a-min-mv = <0x320>;
			nvidia,source = "pllp_out0";
			nvidia,src-sel-reg = <0x40000006>;
			nvidia,burst-regs-num = <0xa5>;
			nvidia,burst-up-down-regs-num = <0x1f>;
			nvidia,emc-registers = <0x6 0x15 0x0 0x4 0x2 0x6 0x8 0x3 0xa 0x2 0x2 0x1 0x2 0x0 0x3 0x3 0x6 0x2 0x0 0x5 0x5 0x10000 0x3 0x0 0x0 0x0 0x0 0x4 0xc 0xd 0xf 0x60 0x0 0x18 0x2 0x2 0x2 0x0 0x1 0xc 0x17 0x17 0x3 0x3 0x3 0x6 0x4 0x3 0x3 0x2ae 0x0 0x0 0x0 0x1363a296 0x5800a0 0x8000 0x48000 0x48000 0x48000 0x48000 0x48000 0x48000 0x48000 0x48000 0x48000 0x48000 0x48000 0x48000 0x48000 0x48000 0x48000 0x48000 0x0 0x0 0x0 0x0 0x0 0x0 0x0 0x0 0xfc000 0xfc000 0x0 0xfc000 0xfc000 0x0 0x0 0x0 0x0 0x0 0x0 0x0 0x0 0x0 0x0 0x0 0x0 0x0 0x0 0x0 0x0 0x0 0x0 0x0 0x0 0x0 0x0 0x0 0x0 0x0 0xfc000 0xfc000 0xfc000 0xfc000 0xfc00 0xfc00 0xfc00 0xfc00 0x200 0x0 0x100100 0x130b018 0x0 0x0 0x77ffc000 0x303 0x81f1f008 0x7070000 0x3f 0x15ddddd 0x51451400 0x514514 0x514514 0x51451400 0x3f 0x0 0x0 0x64000 0x25 0x660011 0x660011 0x0 0x3 0xf3f3 0x800001c5 0xa 0x8000001 0x80000026 0x1 0x1 0x3 0x1 0x3 0x1 0x2 0x7 0x2 0x1 0x4 0x5 0x5040102 0x90403 0x73430504 0x70000f03 0x1f0000>;
			nvidia,emc-burst-up-down-regs = <0x1 0x31 0xff00da 0xff00da 0xff0075 0xff00ff 0xff009d 0xff00ff 0xff009d 0x9b0049 0xff0080 0xff0004 0xff0004 0x800ad 0xff 0xff0004 0xff00c6 0xff006d 0xff0024 0xff00d6 0xff 0x9f 0xff00ff 0x9f 0xff00ff 0xff00ff 0x9f00a0 0xff00ff 0xff00ff 0xff00ff 0xff00da>;
			nvidia,emc-zcal-cnt-long = <0x15>;
			nvidia,emc-acal-interval = <0x1fffff>;
			nvidia,emc-ctt-term_ctrl = <0x802>;
			nvidia,emc-cfg = <0xf3200000>;
			nvidia,emc-cfg-2 = <0x8c7>;
			nvidia,emc-sel-dpd-ctrl = <0x4013c>;
			nvidia,emc-cfg-dig-dll = <0x580068>;
			nvidia,emc-bgbias-ctl0 = <0x8>;
			nvidia,emc-auto-cal-config2 = <0x0>;
			nvidia,emc-auto-cal-config3 = <0x0>;
			nvidia,emc-auto-cal-config = <0xa1430000>;
			nvidia,emc-mode-0 = <0x0>;
			nvidia,emc-mode-1 = <0x10083>;
			nvidia,emc-mode-2 = <0x20004>;
			nvidia,emc-mode-4 = <0x800b0000>;
			nvidia,emc-clock-latency-change = <0x1aea>;
		};

		emc-table-derated@204000 {
			compatible = "nvidia,tegra12-emc-table-derated";
			nvidia,revision = <0x19>;
			nvidia,dvfs-version = "01_204000_01_V5.0.14_V1.1";
			clock-frequency = <0x31ce0>;
			nvidia,emc-min-mv = <0x320>;
			nvidia,gk20a-min-mv = <0x320>;
			nvidia,source = "pllp_out0";
			nvidia,src-sel-reg = <0x40000002>;
			nvidia,burst-regs-num = <0xa5>;
			nvidia,burst-up-down-regs-num = <0x1f>;
			nvidia,emc-registers = <0xc 0x2a 0x0 0x8 0x4 0x7 0x8 0x3 0xa 0x4 0x4 0x2 0x3 0x0 0x2 0x2 0x5 0x3 0x0 0x3 0x7 0x10000 0x4 0x0 0x0 0x0 0x0 0x2 0xe 0xf 0x11 0xc1 0x0 0x30 0x2 0x2 0x4 0x0 0x1 0xc 0x2d 0x2d 0x3 0x4 0x3 0x9 0x5 0x3 0x3 0x55b 0x0 0x0 0x0 0x1363a296 0x5800a0 0x8000 0x80000 0x80000 0x80000 0x80000 0x80000 0x80000 0x80000 0x80000 0x80000 0x80000 0x80000 0x80000 0x80000 0x80000 0x80000 0x80000 0x0 0x0 0x0 0x0 0x0 0x0 0x0 0x0 0xa8000 0xa8000 0x0 0xa8000 0xa8000 0x0 0x0 0x0 0x0 0x0 0x0 0x0 0x0 0x0 0x0 0x0 0x0 0x0 0x0 0x0 0x0 0x0 0x0 0x0 0x0 0x0 0x0 0x0 0x0 0x0 0x88000 0x88000 0x88000 0x88000 0x8c00 0x8800 0x8c00 0x8800 0x200 0x0 0x100100 0x130b018 0x0 0x0 0x77ffc000 0x303 0x81f1f008 0x7070000 0x3f 0x15ddddd 0x51451400 0x514514 0x514514 0x51451400 0x3f 0x0 0x0 0x64000 0x4a 0xcc0011 0xcc0011 0x0 0x4 0xd3b3 0x80000287 0xa 0x1000003 0x80000040 0x1 0x2 0x6 0x3 0x5 0x1 0x2 0x7 0x3 0x1 0x5 0x5 0x5050103 0xb0606 0x72e40a07 0x70000f03 0x1f0000>;
			nvidia,emc-burst-up-down-regs = <0x1 0x62 0xff006d 0xff006d 0xff003c 0xff00af 0xff004f 0xff00af 0xff004f 0x4e0049 0xff0080 0xff0004 0xff0004 0x80057 0xff 0xff0004 0xff0063 0xff0036 0xff0024 0xff006b 0xff 0x50 0xff00ff 0x50 0xff00ff 0xd400ff 0x510050 0xff00ff 0xff00ff 0xff00c6 0xff006d>;
			nvidia,emc-zcal-cnt-long = <0x17>;
			nvidia,emc-acal-interval = <0x1fffff>;
			nvidia,emc-ctt-term_ctrl = <0x802>;
			nvidia,emc-cfg = <0xf3200000>;
			nvidia,emc-cfg-2 = <0x8cf>;
			nvidia,emc-sel-dpd-ctrl = <0x4013c>;
			nvidia,emc-cfg-dig-dll = <0x580068>;
			nvidia,emc-bgbias-ctl0 = <0x8>;
			nvidia,emc-auto-cal-config2 = <0x0>;
			nvidia,emc-auto-cal-config3 = <0x0>;
			nvidia,emc-auto-cal-config = <0xa1430000>;
			nvidia,emc-mode-0 = <0x0>;
			nvidia,emc-mode-1 = <0x10083>;
			nvidia,emc-mode-2 = <0x20004>;
			nvidia,emc-mode-4 = <0x800b0000>;
			nvidia,emc-clock-latency-change = <0xd5c>;
		};

		emc-table-derated@300000 {
			compatible = "nvidia,tegra12-emc-table-derated";
			nvidia,revision = <0x19>;
			nvidia,dvfs-version = "01_300000_01_V5.0.14_V1.1";
			clock-frequency = <0x493e0>;
			nvidia,emc-min-mv = <0x334>;
			nvidia,gk20a-min-mv = <0x334>;
			nvidia,source = "pllc_out0";
			nvidia,src-sel-reg = <0x20000002>;
			nvidia,burst-regs-num = <0xa5>;
			nvidia,burst-up-down-regs-num = <0x1f>;
			nvidia,emc-registers = <0x12 0x3e 0x0 0xd 0x5 0x7 0x8 0x3 0xa 0x5 0x5 0x3 0x3 0x0 0x2 0x2 0x6 0x3 0x0 0x3 0x8 0x30000 0x4 0x0 0x0 0x0 0x0 0x2 0xf 0x12 0x14 0x11b 0x0 0x46 0x2 0x2 0x5 0x0 0x1 0xc 0x42 0x42 0x3 0x5 0x3 0xd 0x7 0x3 0x3 0x7e0 0x0 0x0 0x0 0x1363a096 0x5800a0 0x8000 0x20000 0x20000 0x20000 0x20000 0x20000 0x20000 0x20000 0x20000 0x20000 0x20000 0x20000 0x20000 0x20000 0x20000 0x20000 0x20000 0x0 0x0 0x0 0x0 0x0 0x0 0x0 0x0 0x58000 0x58000 0x0 0x58000 0x58000 0x0 0x0 0x0 0x0 0x0 0x0 0x0 0x0 0x0 0x0 0x0 0x0 0x0 0x0 0x0 0x0 0x0 0x0 0x0 0x0 0x0 0x0 0x0 0x0 0x0 0x58000 0x58000 0x58000 0x58000 0x5c00 0x5800 0x5c00 0x5800 0x200 0x0 0x100100 0x1231239 0x0 0x0 0x77ffc000 0x303 0x81f1f008 0x7070000 0x3f 0x15ddddd 0x51451420 0x514514 0x514514 0x51451400 0x3f 0x0 0x0 0x64000 0x6c 0x12c0011 0x12c0011 0x0 0x4 0x52a3 0x8000033e 0xb 0x8000004 0x80000040 0x1 0x2 0x9 0x5 0x7 0x1 0x2 0x7 0x3 0x1 0x5 0x5 0x5050103 0xc0709 0x72c50e0a 0x70000f03 0x1f0000>;
			nvidia,emc-burst-up-down-regs = <0x4 0x90 0xff004a 0xff004a 0xff003c 0xff0090 0xff0041 0xff0090 0xff0041 0x350049 0xff0080 0xff0004 0xff0004 0x8003b 0xff 0xff0004 0xff0043 0xff002d 0xff0024 0xff0049 0xff 0x36 0xff00ff 0x36 0xff00ff 0xd400ff 0x510036 0xff00ff 0xff00ff 0xff0087 0xff004a>;
			nvidia,emc-zcal-cnt-long = <0x1f>;
			nvidia,emc-acal-interval = <0x1fffff>;
			nvidia,emc-ctt-term_ctrl = <0x802>;
			nvidia,emc-cfg = <0xf3300000>;
			nvidia,emc-cfg-2 = <0x8d7>;
			nvidia,emc-sel-dpd-ctrl = <0x4013c>;
			nvidia,emc-cfg-dig-dll = <0x580068>;
			nvidia,emc-bgbias-ctl0 = <0x0>;
			nvidia,emc-auto-cal-config2 = <0x0>;
			nvidia,emc-auto-cal-config3 = <0x0>;
			nvidia,emc-auto-cal-config = <0xa1430000>;
			nvidia,emc-mode-0 = <0x0>;
			nvidia,emc-mode-1 = <0x10083>;
			nvidia,emc-mode-2 = <0x20004>;
			nvidia,emc-mode-4 = <0x800b0000>;
			nvidia,emc-clock-latency-change = <0xa78>;
		};

		emc-table-derated@396000 {
			compatible = "nvidia,tegra12-emc-table-derated";
			nvidia,revision = <0x19>;
			nvidia,dvfs-version = "01_396000_01_V5.0.14_V1.1";
			clock-frequency = <0x60ae0>;
			nvidia,emc-min-mv = <0x352>;
			nvidia,gk20a-min-mv = <0x352>;
			nvidia,source = "pllm_out0";
			nvidia,src-sel-reg = <0x2>;
			nvidia,burst-regs-num = <0xa5>;
			nvidia,burst-up-down-regs-num = <0x1f>;
			nvidia,emc-registers = <0x18 0x53 0x0 0x11 0x7 0x8 0x8 0x3 0xa 0x7 0x7 0x4 0x3 0x0 0x2 0x2 0x6 0x3 0x0 0x2 0x9 0x30000 0x4 0x0 0x0 0x0 0x0 0x1 0x10 0x12 0x14 0x176 0x0 0x5d 0x2 0x2 0x7 0x0 0x1 0xe 0x58 0x58 0x3 0x6 0x3 0x12 0xa 0x3 0x3 0xa66 0x0 0x0 0x0 0x1363a096 0x5800a0 0x8000 0x20000 0x20000 0x20000 0x20000 0x20000 0x20000 0x20000 0x20000 0x20000 0x20000 0x20000 0x20000 0x20000 0x20000 0x20000 0x20000 0x0 0x0 0x0 0x0 0x0 0x0 0x0 0x0 0x48000 0x48000 0x0 0x48000 0x48000 0x0 0x0 0x0 0x0 0x0 0x0 0x0 0x0 0x0 0x0 0x0 0x0 0x0 0x0 0x0 0x0 0x0 0x0 0x0 0x0 0x0 0x0 0x0 0x0 0x0 0x40000 0x40000 0x40000 0x40000 0x4000 0x4000 0x4000 0x4000 0x200 0x0 0x100100 0x1231239 0x0 0x0 0x77ffc000 0x303 0x81f1f008 0x7070000 0x3f 0x15ddddd 0x51451420 0x514514 0x514514 0x51451400 0x3f 0x0 0x0 0x64000 0x8f 0x18c0011 0x18c0011 0x0 0x4 0x52a3 0x800003f4 0xb 0xf000005 0x80000040 0x2 0x3 0xc 0x7 0x9 0x2 0x2 0x7 0x3 0x1 0x5 0x5 0x5050103 0xe090c 0x72c6120d 0x70000f03 0x1f0000>;
			nvidia,emc-burst-up-down-regs = <0xa 0xbe 0xff0038 0xff0038 0xff003c 0xff0090 0xff0041 0xff0090 0xff0041 0x280049 0xff0080 0xff0004 0xff0004 0x8002d 0xff 0xff0004 0xff0033 0xff0022 0xff0024 0xff0037 0xff 0x36 0xff00ff 0x36 0xff00ff 0xd400ff 0x510029 0xff00ff 0xff00ff 0xff0066 0xff0038>;
			nvidia,emc-zcal-cnt-long = <0x28>;
			nvidia,emc-acal-interval = <0x1fffff>;
			nvidia,emc-ctt-term_ctrl = <0x802>;
			nvidia,emc-cfg = <0xf3300000>;
			nvidia,emc-cfg-2 = <0x897>;
			nvidia,emc-sel-dpd-ctrl = <0x4001c>;
			nvidia,emc-cfg-dig-dll = <0x580068>;
			nvidia,emc-bgbias-ctl0 = <0x0>;
			nvidia,emc-auto-cal-config2 = <0x0>;
			nvidia,emc-auto-cal-config3 = <0x0>;
			nvidia,emc-auto-cal-config = <0xa1430000>;
			nvidia,emc-mode-0 = <0x0>;
			nvidia,emc-mode-1 = <0x10083>;
			nvidia,emc-mode-2 = <0x20004>;
			nvidia,emc-mode-4 = <0x800b0000>;
			nvidia,emc-clock-latency-change = <0x884>;
		};

		emc-table-derated@528000 {
			compatible = "nvidia,tegra12-emc-table-derated";
			nvidia,revision = <0x19>;
			nvidia,dvfs-version = "01_528000_01_V5.0.14_V1.1";
			clock-frequency = <0x80e80>;
			nvidia,emc-min-mv = <0x370>;
			nvidia,gk20a-min-mv = <0x366>;
			nvidia,source = "pllm_ud";
			nvidia,src-sel-reg = <0x80000000>;
			nvidia,burst-regs-num = <0xa5>;
			nvidia,burst-up-down-regs-num = <0x1f>;
			nvidia,emc-registers = <0x20 0x6e 0x0 0x17 0xa 0xa 0x9 0x3 0xd 0xa 0xa 0x6 0x4 0x0 0x2 0x2 0x7 0x4 0x0 0x2 0xb 0x40000 0x5 0x0 0x0 0x0 0x0 0x1 0x12 0x15 0x17 0x1f3 0x0 0x7c 0x3 0x3 0xa 0x0 0x1 0x11 0x75 0x75 0x4 0x8 0x4 0x19 0xd 0x3 0x3 0xddd 0x0 0x0 0x0 0x1363a096 0xe01200b9 0x8000 0xa 0xa 0xa 0xa 0xa 0xa 0xa 0xa 0xa 0xa 0xa 0xa 0xa 0xa 0xa 0xa 0x0 0x0 0x0 0x0 0x0 0x0 0x0 0x0 0x400e 0x400e 0x0 0x4010 0x4010 0x0 0x0 0x0 0x0 0x0 0x0 0x0 0x0 0x0 0x1 0x1 0x0 0x0 0x0 0x0 0x1 0x0 0x1 0x1 0x0 0x0 0x0 0x0 0x1 0x0 0xc 0xc 0xc 0xc 0xd 0xc 0xd 0xc 0x220 0x0 0x100100 0x123123d 0x0 0x0 0x77ffc004 0x303 0x81f1f008 0x7070000 0x3f 0x15ddddd 0x51451420 0x514514 0x514514 0x51451400 0x3f 0x0 0x0 0x64000 0xbf 0x2100013 0x2100013 0x0 0x5 0x42a0 0x800004ef 0xd 0xf000007 0x80000040 0x4 0x5 0x11 0xa 0xd 0x3 0x2 0x9 0x3 0x1 0x6 0x6 0x6060103 0x130c11 0x72c81812 0x70000f03 0x1f0000>;
			nvidia,emc-burst-up-down-regs = <0xd 0xfd 0xc10038 0xc10038 0xc1003c 0xc10090 0xc10041 0xc10090 0xc10041 0x270049 0xc10080 0xc10004 0xc10004 0x80021 0xc1 0xc10004 0xc10026 0xc1001a 0xc10024 0xc10029 0xc1 0x36 0xc100c1 0x36 0xc100c1 0xd400ff 0x510029 0xc100c1 0xc100c1 0xc10065 0xc1002a>;
			nvidia,emc-zcal-cnt-long = <0x34>;
			nvidia,emc-acal-interval = <0x1fffff>;
			nvidia,emc-ctt-term_ctrl = <0x802>;
			nvidia,emc-cfg = <0xf3300000>;
			nvidia,emc-cfg-2 = <0x89f>;
			nvidia,emc-sel-dpd-ctrl = <0x4001c>;
			nvidia,emc-cfg-dig-dll = <0xe0120069>;
			nvidia,emc-bgbias-ctl0 = <0x0>;
			nvidia,emc-auto-cal-config2 = <0x0>;
			nvidia,emc-auto-cal-config3 = <0x0>;
			nvidia,emc-auto-cal-config = <0xa1430000>;
			nvidia,emc-mode-0 = <0x0>;
			nvidia,emc-mode-1 = <0x100c3>;
			nvidia,emc-mode-2 = <0x20006>;
			nvidia,emc-mode-4 = <0x800b0000>;
			nvidia,emc-clock-latency-change = <0x5a0>;
		};

		emc-table-derated@600000 {
			compatible = "nvidia,tegra12-emc-table-derated";
			nvidia,revision = <0x19>;
			nvidia,dvfs-version = "01_600000_01_V5.0.14_V1.1";
			clock-frequency = <0x927c0>;
			nvidia,emc-min-mv = <0x38e>;
			nvidia,gk20a-min-mv = <0x38e>;
			nvidia,source = "pllc_ud";
			nvidia,src-sel-reg = <0xe0000000>;
			nvidia,burst-regs-num = <0xa5>;
			nvidia,burst-up-down-regs-num = <0x1f>;
			nvidia,emc-registers = <0x25 0x7d 0x0 0x1a 0xb 0xa 0xb 0x4 0xf 0xb 0xb 0x7 0x4 0x0 0x4 0x4 0xa 0x4 0x0 0x3 0xd 0x70000 0x5 0x0 0x0 0x0 0x0 0x2 0x14 0x18 0x1a 0x237 0x0 0x8d 0x4 0x4 0xb 0x0 0x1 0x13 0x84 0x84 0x5 0x9 0x5 0x1c 0xe 0x3 0x3 0xfc0 0x0 0x0 0x0 0x1363a096 0xe00e00b9 0x8000 0xa 0xa 0xa 0xa 0xa 0xa 0xa 0xa 0xa 0xa 0xa 0xa 0xa 0xa 0xa 0xa 0x0 0x0 0x0 0x0 0x0 0x0 0x0 0x0 0xe 0xe 0x0 0x10 0x10 0x0 0x0 0x0 0x0 0x0 0x0 0x0 0x0 0x0 0x3 0x3 0x2 0x2 0x2 0x1 0x3 0x1 0x3 0x3 0x2 0x2 0x2 0x1 0x3 0x1 0xb 0xb 0xb 0xb 0xc 0xb 0xc 0xb 0x220 0x0 0x100100 0x121103d 0x0 0x0 0x77ffc004 0x303 0x81f1f008 0x7070000 0x3f 0x15ddddd 0x51451420 0x514514 0x514514 0x51451400 0x3f 0x0 0x0 0x64000 0xd8 0x2580014 0x2580014 0x0 0x5 0x40a0 0x80000578 0x10 0x9 0x80000040 0x4 0x5 0x13 0xc 0xe 0x3 0x3 0xa 0x3 0x1 0x6 0x7 0x7060103 0x150e13 0x72a91b14 0x70000f03 0x1f0000>;
			nvidia,emc-burst-up-down-regs = <0xf 0x120 0xaa0038 0xaa0038 0xaa003c 0xaa0090 0xaa0041 0xaa0090 0xaa0041 0x270049 0xaa0080 0xaa0004 0xaa0004 0x8001d 0xaa 0xaa0004 0xaa0022 0xaa0018 0xaa0024 0xaa0024 0xaa 0x36 0xaa00aa 0x36 0xaa00aa 0xd400ff 0x510029 0xaa00aa 0xaa00aa 0xaa0065 0xaa0025>;
			nvidia,emc-zcal-cnt-long = <0x3a>;
			nvidia,emc-acal-interval = <0x1fffff>;
			nvidia,emc-ctt-term_ctrl = <0x802>;
			nvidia,emc-cfg = <0xf3300000>;
			nvidia,emc-cfg-2 = <0x89f>;
			nvidia,emc-sel-dpd-ctrl = <0x4001c>;
			nvidia,emc-cfg-dig-dll = <0xe00e0069>;
			nvidia,emc-bgbias-ctl0 = <0x0>;
			nvidia,emc-auto-cal-config2 = <0x0>;
			nvidia,emc-auto-cal-config3 = <0x0>;
			nvidia,emc-auto-cal-config = <0xa1430000>;
			nvidia,emc-mode-0 = <0x0>;
			nvidia,emc-mode-1 = <0x100e3>;
			nvidia,emc-mode-2 = <0x20007>;
			nvidia,emc-mode-4 = <0x800b0000>;
			nvidia,emc-clock-latency-change = <0x5a0>;
		};

		emc-table-derated@792000 {
			compatible = "nvidia,tegra12-emc-table-derated";
			nvidia,revision = <0x19>;
			nvidia,dvfs-version = "01_792000_01_V5.0.14_V1.1";
			clock-frequency = <0xc15c0>;
			nvidia,emc-min-mv = <0x3d4>;
			nvidia,gk20a-min-mv = <0x3d4>;
			nvidia,source = "pllm_ud";
			nvidia,src-sel-reg = <0x80000000>;
			nvidia,burst-regs-num = <0xa5>;
			nvidia,burst-up-down-regs-num = <0x1f>;
			nvidia,emc-registers = <0x30 0xa6 0x0 0x22 0xf 0xd 0xd 0x5 0x13 0xf 0xf 0x9 0x5 0x0 0x5 0x5 0xd 0x5 0x0 0x4 0x10 0xa0000 0x7 0x0 0x0 0x0 0x0 0x3 0x17 0x1d 0x1f 0x2ec 0x0 0xbb 0x5 0x5 0xf 0x0 0x1 0x17 0xaf 0xaf 0x6 0xc 0x6 0x26 0x13 0x3 0x3 0x14cb 0x0 0x0 0x0 0x1363a096 0xe00700b9 0x8000 0xa 0xa 0xa 0xa 0xa 0xa 0xa 0xa 0xa 0xa 0xa 0xa 0xa 0xa 0xa 0xa 0x0 0x0 0x0 0x0 0x0 0x0 0x0 0x0 0x400d 0x400d 0x0 0x4010 0x4010 0x0 0x0 0x0 0x0 0x0 0x0 0x0 0x0 0x0 0x7 0x7 0x6 0x6 0x6 0x5 0x6 0x5 0x7 0x7 0x6 0x6 0x6 0x5 0x6 0x5 0xa 0xa 0xa 0xa 0xb 0xa 0xb 0xa 0x220 0x0 0x100100 0x120103d 0x0 0x0 0x77ffc004 0x303 0x81f1f008 0x7070000 0x0 0x15ddddd 0x61861820 0x514514 0x514514 0x61861800 0x3f 0x0 0x0 0x64000 0x11e 0x3180017 0x3180017 0x0 0x7 0x4080 0x800006e5 0x14 0xe00000b 0x80000040 0x6 0x7 0x19 0x10 0x13 0x4 0x3 0xc 0x4 0x1 0x8 0x8 0x8080104 0x1b1219 0x72ac241a 0x70000f02 0x1f0000>;
			nvidia,emc-burst-up-down-regs = <0x13 0x17c 0x810038 0x810038 0x81003c 0x810090 0x810041 0x810090 0x810041 0x270049 0x810080 0x810004 0x810004 0x80016 0x81 0x810004 0x810019 0x810018 0x810024 0x81001c 0x81 0x36 0x810081 0x36 0x810081 0xd400ff 0x510029 0x810081 0x810081 0x810065 0x81001c>;
			nvidia,emc-zcal-cnt-long = <0x4c>;
			nvidia,emc-acal-interval = <0x1fffff>;
			nvidia,emc-ctt-term_ctrl = <0x802>;
			nvidia,emc-cfg = <0xf3300000>;
			nvidia,emc-cfg-2 = <0x89f>;
			nvidia,emc-sel-dpd-ctrl = <0x4001c>;
			nvidia,emc-cfg-dig-dll = <0xe0070069>;
			nvidia,emc-bgbias-ctl0 = <0x0>;
			nvidia,emc-auto-cal-config2 = <0x0>;
			nvidia,emc-auto-cal-config3 = <0x0>;
			nvidia,emc-auto-cal-config = <0xa1430000>;
			nvidia,emc-mode-0 = <0x0>;
			nvidia,emc-mode-1 = <0x10043>;
			nvidia,emc-mode-2 = <0x2001a>;
			nvidia,emc-mode-4 = <0x800b0000>;
			nvidia,emc-clock-latency-change = <0x4b0>;
		};

		emc-table-derated@924000 {
			compatible = "nvidia,tegra12-emc-table-derated";
			nvidia,revision = <0x19>;
			nvidia,dvfs-version = "01_924000_01_V5.0.14_V1.1";
			clock-frequency = <0xe1960>;
			nvidia,emc-min-mv = <0x3f2>;
			nvidia,gk20a-min-mv = <0x3f2>;
			nvidia,source = "pllm_ud";
			nvidia,src-sel-reg = <0x80000000>;
			nvidia,burst-regs-num = <0xa5>;
			nvidia,burst-up-down-regs-num = <0x1f>;
			nvidia,emc-registers = <0x39 0xc2 0x0 0x28 0x12 0xf 0x10 0x6 0x17 0x12 0x12 0xa 0x5 0x0 0x7 0x7 0x10 0x5 0x0 0x5 0x12 0xd0000 0x7 0x0 0x0 0x0 0x0 0x4 0x19 0x20 0x22 0x369 0x0 0xda 0x6 0x6 0x12 0x0 0x1 0x1b 0xcc 0xcc 0x7 0xe 0x7 0x2d 0x16 0x3 0x3 0x1842 0x0 0x0 0x0 0x1363a896 0xe00400b9 0x8000 0x4 0x4 0x4 0x4 0x4 0x4 0x4 0x4 0x4 0x4 0x4 0x4 0x4 0x4 0x4 0x4 0x0 0x0 0x0 0x0 0x0 0x0 0x0 0x0 0x400d 0x400d 0x0 0x11 0x11 0x0 0x0 0x0 0x0 0x0 0x0 0x0 0x0 0x0 0x4 0x4 0x4 0x4 0x4 0x4 0x4 0x4 0x4 0x4 0x4 0x4 0x4 0x4 0x4 0x4 0x9 0x9 0x9 0x9 0xa 0x9 0xa 0x9 0x220 0x0 0x100100 0x120103d 0x0 0x0 0x77ffc004 0x303 0x81f1f008 0x7070000 0x0 0x15ddddd 0x5d75d720 0x514514 0x514514 0x5d75d700 0x3f 0x0 0x0 0x64000 0x14d 0x39c0019 0x39c0019 0x0 0x7 0x4080 0x800007e0 0x17 0xe00000d 0x80000040 0x8 0x9 0x1d 0x13 0x17 0x5 0x4 0xe 0x4 0x1 0x9 0x9 0x9090104 0x20161d 0x72ae2a1e 0x70000f02 0x1f0000>;
			nvidia,emc-burst-up-down-regs = <0x17 0x1bb 0x6e0038 0x6e0038 0x6e003c 0x6e0090 0x6e0041 0x6e0090 0x6e0041 0x270049 0x6e0080 0x6e0004 0x6e0004 0x80016 0x6e 0x6e0004 0x6e0019 0x6e0018 0x6e0024 0x6e001b 0x6e 0x36 0x6e006e 0x36 0x6e006e 0xd400ff 0x510029 0x6e006e 0x6e006e 0x6e0065 0x6e001c>;
			nvidia,emc-zcal-cnt-long = <0x58>;
			nvidia,emc-acal-interval = <0x1fffff>;
			nvidia,emc-ctt-term_ctrl = <0x802>;
			nvidia,emc-cfg = <0xf3300000>;
			nvidia,emc-cfg-2 = <0x89f>;
			nvidia,emc-sel-dpd-ctrl = <0x4001c>;
			nvidia,emc-cfg-dig-dll = <0xe0040069>;
			nvidia,emc-bgbias-ctl0 = <0x0>;
			nvidia,emc-auto-cal-config2 = <0x0>;
			nvidia,emc-auto-cal-config3 = <0x0>;
			nvidia,emc-auto-cal-config = <0xa1430000>;
			nvidia,emc-mode-0 = <0x0>;
			nvidia,emc-mode-1 = <0x10083>;
			nvidia,emc-mode-2 = <0x2001c>;
			nvidia,emc-mode-4 = <0x800b0000>;
			nvidia,emc-clock-latency-change = <0x49c>;
		};
	};

	regulators {
		compatible = "simple-bus";
		#address-cells = <0x1>;
		#size-cells = <0x0>;

		regulator@0 {
			compatible = "regulator-fixed";
			reg = <0x0>;
			regulator-name = "vdd_ac_bat";
			regulator-min-microvolt = <0x4c4b40>;
			regulator-max-microvolt = <0x4c4b40>;
			regulator-always-on;

			consumers {

				c1 {
					regulator-consumer-supply = "vdd_sys_bl";
				};
			};
		};

		regulator@1 {
			compatible = "regulator-fixed-sync";
			reg = <0x1>;
			regulator-name = "usb0-vbus";
			regulator-min-microvolt = <0x4c4b40>;
			regulator-max-microvolt = <0x4c4b40>;
			gpio = <0x7 0x6c 0x0>;
			enable-active-high;
			gpio-open-drain;

			consumers {

				c1 {
					regulator-consumer-supply = "usb_vbus0";
					regulator-consumer-device = "tegra-xhci";
				};
			};
		};

		regulator@2 {
			compatible = "regulator-fixed-sync";
			reg = <0x2>;
			regulator-name = "usb1-vbus";
			regulator-min-microvolt = <0x4c4b40>;
			regulator-max-microvolt = <0x4c4b40>;
			enable-active-high;
			gpio = <0x7 0x6d 0x0>;
			gpio-open-drain;
			vin-supply = <0xb>;

			consumers {

				c1 {
					regulator-consumer-supply = "usb_vbus";
					regulator-consumer-device = "tegra-ehci.1";
				};

				c2 {
					regulator-consumer-supply = "usb_vbus1";
					regulator-consumer-device = "tegra-xhci";
				};
			};
		};

		regulator@3 {
			compatible = "regulator-fixed-sync";
			reg = <0x3>;
			regulator-name = "usb2-vbus";
			regulator-min-microvolt = <0x4c4b40>;
			regulator-max-microvolt = <0x4c4b40>;
			enable-active-high;
			gpio = <0x7 0xf9 0x0>;
			gpio-open-drain;
			vin-supply = <0xb>;

			consumers {

				c1 {
					regulator-consumer-supply = "usb_vbus";
					regulator-consumer-device = "tegra-ehci.2";
				};

				c2 {
					regulator-consumer-supply = "usb_vbus2";
					regulator-consumer-device = "tegra-xhci";
				};
			};
		};

		regulator@41 {
			compatible = "regulator-fixed-sync";
			reg = <0x29>;
			regulator-name = "avdd-lcd-vsp";
			regulator-min-microvolt = <0x53ec60>;
			regulator-max-microvolt = <0x53ec60>;
			regulator-boot-on;
			gpio = <0x7 0x44 0x0>;
			enable-active-high;

			consumers {

				c1 {
					regulator-consumer-supply = "avdd_lcd";
				};
			};
		};

		regulator@42 {
			compatible = "regulator-fixed-sync";
			reg = <0x2a>;
			regulator-name = "avdd-lcd-vsn";
			regulator-min-microvolt = <0x53ec60>;
			regulator-max-microvolt = <0x53ec60>;
			regulator-boot-on;
			gpio = <0x7 0x92 0x0>;
			enable-active-high;

			consumers {

				c1 {
					regulator-consumer-supply = "bvdd_lcd";
				};
			};
		};

		regulator@5 {
			compatible = "regulator-fixed-sync";
			reg = <0x5>;
			regulator-name = "vdd-lcd";
			regulator-min-microvolt = <0x124f80>;
			regulator-max-microvolt = <0x124f80>;
			enable-active-high;
			gpio = <0x10 0x4 0x0>;
			vin-supply = <0xc>;

			consumers {

				c1 {
					regulator-consumer-supply = "vdd_lcd_1v2_s";
				};
			};
		};

		regulator@6 {
			compatible = "regulator-fixed-sync";
			reg = <0x6>;
			regulator-name = "ldoen";
			regulator-min-microvolt = <0x124f80>;
			regulator-max-microvolt = <0x124f80>;
			enable-active-high;
			gpio = <0x10 0x6 0x0>;
			vin-supply = <0xc>;

			consumers {

				c1 {
					regulator-consumer-supply = "ldoen";
					regulator-consumer-device = "tegra-snd-rt5639";
				};
			};
		};

		regulator@8 {
			compatible = "regulator-fixed-sync";
			reg = <0x8>;
			regulator-name = "en-lcd-bl";
			regulator-min-microvolt = <0x4c4b40>;
			regulator-max-microvolt = <0x4c4b40>;
			enable-active-high;
			gpio = <0x7 0x3a 0x0>;

			consumers {

				c1 {
					regulator-consumer-supply = "vdd_lcd_bl_en";
				};
			};
		};

		regulator@9 {
			compatible = "regulator-fixed-sync";
			reg = <0x9>;
			regulator-name = "vdd-hdmi";
			regulator-min-microvolt = <0x4c4b40>;
			regulator-max-microvolt = <0x4c4b40>;
			enable-active-high;
			gpio = <0x7 0x56 0x0>;
			vin-supply = <0x11>;

			consumers {

				c1 {
					regulator-consumer-supply = "vdd_hdmi_5v0";
					regulator-consumer-device = "tegradc.1";
				};
			};
		};

		regulator@10 {
			compatible = "regulator-fixed-sync";
			reg = <0xa>;
			regulator-name = "vdd-cam-1v8";
			regulator-min-microvolt = <0x1b7740>;
			regulator-max-microvolt = <0x1b7740>;
			enable-active-high;
			gpio = <0x10 0x1 0x0>;
			vin-supply = <0xc>;

			consumers {

				c1 {
					regulator-consumer-supply = "vdd_cam_1v8";
				};
			};
		};

		regulator@11 {
			compatible = "regulator-fixed-sync";
			reg = <0xb>;
			regulator-name = "vdd-cam-1v2";
			regulator-min-microvolt = <0x124f80>;
			regulator-max-microvolt = <0x124f80>;
			enable-active-high;
			gpio = <0x10 0x2 0x0>;
			vin-supply = <0xc>;

			consumers {

				c1 {
					regulator-consumer-supply = "vdd_cam_1v2";
				};
			};
		};
	};

	gpio-keys {
		compatible = "gpio-keys";

		power {
			label = "Power";
			gpios = <0x7 0x80 0x1>;
			linux,code = <0x74>;
			gpio-key,wakeup;
		};

		volume_down {
			label = "Volume Down";
			gpios = <0x7 0x87 0x1>;
			linux,code = <0x72>;
		};

		volume_up {
			label = "Volume Up";
			gpios = <0x7 0x86 0x1>;
			linux,code = <0x73>;
		};

		hall_intr1 {
			label = "lid_back";
			gpios = <0x7 0xb3 0x1>;
			linux,code = <0x12>;
			linux,input-type = <0x5>;
			gpio-key,wakeup;
		};

		hall_intr2 {
			label = "lid_front";
			gpios = <0x7 0x45 0x1>;
			linux,code = <0x0>;
			linux,input-type = <0x5>;
			gpio-key,wakeup;
		};
	};

	sysedp_batmon_calc {
		compatible = "nvidia,tegra124-sysedp_batmon_calc";
		ocv_lut = <0x64 0x426030 0x50 0x3f9d28 0x32 0x3c68d8 0x14 0x3a6d08 0xa 0x390d78 0x5 0x36b3e8 0x0 0x33e140>;
		ibat_lut = <0x258 0x2328 0xfffffda8 0x2328 0xfffffd44 0x0>;
		rbat_data = <0x186a0 0x186a0 0x186a0 0x186a0 0x186a0 0x186a0>;
		temp_axis = <0xe6>;
		capacity_axis = <0x64 0x50 0x3c 0x28 0x14 0x0>;
		power_supply = "battery";
		r_const = <0x4e20>;
		vsys_min = <0x2c4020>;
	};

	chosen {
		bootargs = "tegraid=40.0.0.00.00 vmalloc=256M video=tegrafb console=ttyS0,115200n8 earlyprintk";
		linux,initrd-start = <0x85000000>;
		linux,initrd-end = <0x851bc400>;
	};

	pwmleds {
		compatible = "pwm-leds";

		button_led {
			label = "button-backlight";
			pwms = <0x12 0x1 0x2710>;
			max-brightness = <0x64>;
			max-duty = <0x32>;
		};
	};
};
